VERSION ""

NS_ :

BS_:

BU_: GW BCM ACM BSD
VAL_TABLE_ Rolling_Counter_0x85 15 "Invalid" ;
VAL_TABLE_ ACM_Crash_Sts 3 "Invalid Value" 2 "Invalid Value" 1 "Crash_Detected" 0 "No_Event" ;
VAL_TABLE_ ACM_Airbag_Deployment_Status 3 "Invalid Value" 2 "Invalid Value" 1 "Airbag_Deployment" 0 "No_Airbag_Deployment" ;
VAL_TABLE_ ACM_Crash_Intensity 7 "Invalid_Value" 6 "Invalid_Value" 5 "Invalid_Value" 4 "Invalid_Value" 3 "Crash_Intensity_3" 2 "Crash_Intensity_2" 1 "Crash_Intensity_1" 0 "No_Crash" ;
VAL_TABLE_ ACM_Front_Crash 3 "Invalid Value" 2 "Invalid Value" 1 "Front_Crash_Detected" 0 "No_Event" ;
VAL_TABLE_ ACM_DriverSide_Crash 3 "Invalid Value" 2 "Invalid Value" 1 "Driverside_Crash_Detected" 0 "No_Event" ;
VAL_TABLE_ ACM_PassSide_Crash 3 "Invalid Value" 2 "Invalid Value" 1 "PassSide_Crash_Detected" 0 "No_Event" ;
VAL_TABLE_ ACM_Rear_Crash 3 "Invalid Value" 2 "Invalid Value" 1 "Rear_Crash_Detected" 0 "No_Event" ;
VAL_TABLE_ ACM_Rollover_Crash 3 "Invalid Value" 2 "Invalid Value" 1 "Rollover_Crash_Detected" 0 "No_Event" ;
VAL_TABLE_ Rolling_Counter_0x381 15 "Invalid" ;
VAL_TABLE_ ACM_Seat_Occupancy_Passenger 3 "Failure" 2 "Not_Available" 1 "Seat Occupied" 0 "Seat_Not_Occupied" ;
VAL_TABLE_ ACM_Seat_Occupancy_2nd_Row_Dri_r 3 "Failure" 2 "Not_Available" 1 "Seat Occupied" 0 "Seat_Not_Occupied" ;
VAL_TABLE_ ACM_Seat_Occupancy_2nd_Row_Pas_r 3 "Failure" 2 "Not_Available" 1 "Seat Occupied" 0 "Seat_Not_Occupied" ;
VAL_TABLE_ ACM_Seat_Occupancy_2nd_Row_Mid_r 3 "Failure" 2 "Not_Available" 1 "Seat Occupied" 0 "Seat_Not_Occupied" ;
VAL_TABLE_ ACM_Seat_Belt_Status_Passenger 3 "Failure" 2 "Not_Available" 1 "Buckled" 0 "Not_buckled" ;
VAL_TABLE_ ACM_Seat_Belt_Status_Driver 3 "Failure" 2 "Not_Available" 1 "Buckled" 0 "Not_buckled" ;
VAL_TABLE_ ACM_Seat_Belt_Status_2nd_Row_Dri 3 "Failure" 2 "Not_Available" 1 "Buckled" 0 "Not_buckled" ;
VAL_TABLE_ ACM_Seat_Belt_Status_2nd_Row_Mid 3 "Failure" 2 "Not_Available" 1 "Buckled" 0 "Not_buckled" ;
VAL_TABLE_ ACM_Seat_Belt_Status_2nd_Row_Pas 3 "Failure" 2 "Not_Available" 1 "Buckled" 0 "Not_buckled" ;
VAL_TABLE_ ACM_Seat_Belt_Status_3rd_Row_Dri 3 "Failure" 2 "Not_Available" 1 "Buckled" 0 "Not_buckled" ;
VAL_TABLE_ ACM_Seat_Belt_Status_3rd_Row_Pas 3 "Failure" 2 "Not_Available" 1 "Buckled" 0 "Not_buckled" ;
VAL_TABLE_ Rolling_Counter_0x488 15 "Invalid" ;
VAL_TABLE_ ACM_Malfunction 0 "ACM_Failure" 1 "ACM_Normal_Operation" ;
VAL_TABLE_ ACM_Pre_Drive_Check 0 "ACM_Pre_Drive_Check" 1 "ACM_Normal_Operation" ;
VAL_TABLE_ ACM_in_Plant_Mode 0 "ACM_in_Plant_Mode" 1 "ACM_in_Normal_Mode" ;
VAL_TABLE_ ACM_PAB_Suppression 0 "Not_Suppressed" 1 "Suppressed" 2 "Function Failure" 3 "Invalid_Value" ;
VAL_TABLE_ ACM_Airbag_Disabled 0 "ACM_AirBag_Disabled" 1 "ACM_Normal_Operation" ;
VAL_TABLE_ ACM_Development_Calibration 0 "ACM_Dev_Calibrated" 1 "ACM_Normal_Operation" ;
VAL_TABLE_ ACM_In_Disposal_Mode 0 "ACM_In_Disposal_Mode" 1 "ACM_Normal_Operation" ;
VAL_TABLE_ ACM_Seatbelt_Reminder_Request 0 "Seatbelt reminder NOT activated" 1 "Seatbelt reminder activated" ;
VAL_TABLE_ ACM_SBR_Chime_Req 0 "No Active Chime" 1 "Active Chime" ;
VAL_TABLE_ ACM_SBR_Blinking_Req 0 "No Blinking" 1 "Blinking 1Hz" ;
VAL_TABLE_ BCM_STAT_RemoteLockFeedback 7 "Signal invalid" 6 "Reserved" 5 "Reserved" 4 "Inactive" 3 "Horn Only" 2 "Lights Only" 1 "Lights and Horn" 0 "OFF" ;
VAL_TABLE_ BCM_STAT_RemoteDoorUnlock_reserv 3 "Signal invalid" 2 "All doors" 1 "Driver door" 0 "Reserved" ;
VAL_TABLE_ BCM_STAT_AutoDoorUnlock 3 "Signal invalid" 2 "Reserved" 1 "ON" 0 "OFF" ;
VAL_TABLE_ BCM_STAT_DoorSpeedLock 7 "Signal invalid" 5 "25KMH" 4 "20KMH" 3 "15KMH" 2 "10KMH" 1 "5KMH" 0 "OFF" ;
VAL_TABLE_ BCM_STAT_DayTimeRunningLight_res 3 "Signal invalid" 2 "Reserved" 1 "ON" 0 "OFF" ;
VAL_TABLE_ BCM_STAT_AntiTheftMode 7 "Signal invalid" 3 "Light and Horn" 2 "Horn Only" 1 "Light Only" 0 "OFF" ;
VAL_TABLE_ BCM_FOBID_userprofile_link 5 "Searching" 4 "No key found" 3 "key illegal" 2 "Fob2" 1 "Fob1" 0 "No trigger from MHU" ;
VAL_TABLE_ BCM_feedback_FollowMeHomeTime 4 "120s" 3 "90s" 2 "60s" 1 "30s" 0 "OFF" ;
VAL_TABLE_ Rolling_Counter_0x12f 15 "Invalid" ;
VAL_TABLE_ ST_KL_KEY_VLD 15 "Signal invalid" 14 "Error" 13 "Reserved" 12 "Reserved" 11 "Reserved" 10 "Reserved" 9 "Reserved" 8 "Reserved" 7 "Reserved" 6 "Reserved" 5 "Key 10sec delay" 4 "Key valid IR" 3 "Key valid AR" 2 "Key search activ" 1 "Key invalid" 0 "Init" ;
VAL_TABLE_ ST_SSP 3 "Signal invalid" 2 "Reserve" 1 "SSB pressed" 0 "SSB not pressed" ;
VAL_TABLE_ BCM_IMMO_Sts 2 "failed " 1 "pass " 0 "init" ;
VAL_TABLE_ REQ_ConsumerControlAudioVolumeCo 7 "signal invalid" 6 "Reserved" 5 "Reserved" 4 "Reserved" 3 "Reserved" 2 "Level 2" 1 "Level 1" 0 "No Reduction" ;
VAL_TABLE_ Rolling_Counter_0x105 15 "Invalid" ;
VAL_TABLE_ BCM_STAT_TrunkAjar 3 "Signal invalid" 2 "Reserved" 1 "Opened" 0 "Closed" ;
VAL_TABLE_ BCM_STAT_DoorAjarDriver 3 "Signal invalid" 2 "Reserved" 1 "Opened" 0 "Closed" ;
VAL_TABLE_ BCM_STAT_DoorAjarPassenger 3 "Signal invalid" 2 "Reserved" 1 "Opened" 0 "Closed" ;
VAL_TABLE_ BCM_STAT_DoorAjarRL 3 "Signal invalid" 2 "Reserved" 1 "Opened" 0 "Closed" ;
VAL_TABLE_ BCM_STAT_DoorAjarRR 3 "Signal invalid" 2 "Reserved" 1 "Opened" 0 "Closed" ;
VAL_TABLE_ BCM_STAT_BonnetAjar 3 "Signal invalid" 2 "Reserved" 1 "Opened" 0 "Closed" ;
VAL_TABLE_ Rolling_Counter_0x106 15 "Invalid" ;
VAL_TABLE_ BCM_HighBeamSts 0 "OFF" 1 "ON" 2 "Fault (Reserved)" 3 "Signal Invalid" ;
VAL_TABLE_ BCM_LowBeamSts 0 "OFF" 1 "ON" 2 "Fault (Reserved)" 3 "Signal Invalid" ;
VAL_TABLE_ BCM_PosLmpSts 0 "OFF" 1 "ON" 2 "Fault (Reserved)" 3 "Signal Invalid" ;
VAL_TABLE_ BCM_TurnIndicatorSts 0 "OFF" 1 "Left On" 2 "Right On" 3 "Left and Right On" ;
VAL_TABLE_ BCM_DayRunningLampSts_reserved 0 "OFF" 1 "ON" 2 "Fault (Reserved)" 3 "Signal Invalid" ;
VAL_TABLE_ BCM_ReverseLightSts 0 "OFF" 1 "ON" 2 "Fault (Reserved)" 3 "Signal Invalid" ;
VAL_TABLE_ BCM_StopLightSts 0 "OFF" 1 "ON" 2 "Fault (Reserved)" 3 "Signal Invalid" ;
VAL_TABLE_ BCM_Fr_Dimming_dome_lampSts 0 "OFF" 1 "ON" 2 "Fault (Reserved)" 3 "Signal Invalid" ;
VAL_TABLE_ BCM_Heated_rearglass 0 "OFF" 1 "ON" 2 "Fault (Reserved)" 3 "Signal Invalid" ;
VAL_TABLE_ BCM_BsdLightSts 0 "OFF" 1 "Left On" 2 "Right On" 3 "Left and Right On" ;
VAL_TABLE_ BCM_STAT_LightActivation 7 "Signal invalid" 6 "Reserved" 5 "Reserved" 4 "Reserved" 3 "AutoLight" 2 "LowBeam" 1 "PositionLight" 0 "OFF" ;
VAL_TABLE_ BCM_STAT_InteriorLight 3 "Signal invalid" 2 "Reserved" 1 "ON" 0 "OFF" ;
VAL_TABLE_ Rolling_Counter_0x107 15 "Invalid" ;
VAL_TABLE_ STAT_ATWS 7 "Signal invalid" 6 "Reserved" 5 "Reserved" 4 "Security Failure" 3 "Partly secured" 2 "Alarm" 1 "Unsecured" 0 "Secured" ;
VAL_TABLE_ STAT_DoorLockDriver 3 "Signal invalid" 2 "Reserved" 1 "Locked" 0 "Unlocked" ;
VAL_TABLE_ Rolling_Counter_0x109 15 "Invalid" ;
VAL_TABLE_ BCM_STAT_HazardWarn 3 "Signal invalid" 2 "Reserved" 1 "Active" 0 "Not active" ;
VAL_TABLE_ BCM_STAT_Horn_Reserved 3 "Signal invalid" 2 "Reserved" 1 "ON" 0 "OFF" ;
VAL_TABLE_ BCM_STAT_WiperStalkSW 7 "Invalid" 6 "Reserved" 5 "Reserved" 4 "High" 3 "Low/Mist" 2 "Auto" 1 "OFF" 0 "Mist (reserved)" ;
VAL_TABLE_ BCM_STAT_WiperStalkSW2 7 "Invalid" 6 "Reserved" 5 "Reserved" 4 "wash(Front wash)" 3 "wiper&wash" 2 "wiper (rear wiper)" 1 "OFF(rear wiper)" 0 "wiper&wash(rear wiper and rear wash)" ;
VAL_TABLE_ BCM_LigntSensor 1 "invalid" 0 "valid" ;
VAL_TABLE_ BCM_STAT_lampStalkSW1 7 "Invalid" 6 "Reserved" 5 "Reserved" 4 "Reserved" 3 "OFF" 2 "positionlight" 1 "Lowbeam" 0 "Auto" ;
VAL_TABLE_ BCM_STAT_lampStalkSW2 3 "Invalid" 2 "neutral status" 1 "HighBeam" 0 "FlashHighBeam" ;
VAL_TABLE_ Rolling_Counter_0x10a 15 "Invalid" ;
VAL_TABLE_ BCM_LVTop_up 1 "start Top up" 0 "stop Top up" ;
VAL_TABLE_ RemoteAccessKey 15 "Invalid" 8 "Panic alarm press" 7 "Panic alarm long press" 6 "Long press unlock" 5 "Long press lock" 4 "Tailgate unlock" 3 "Tailgate unlock long press" 2 "Unlock" 1 "Lock" 0 "No command" ;
VAL_TABLE_ PassiveAccessTrunk 3 "Signal invalid" 2 "Reserved" 1 "Pressed" 0 "Not pressed" ;
VAL_TABLE_ BCM_CurrentValid_FOB 0 "No Valid FOB" 1 "FOB_1" 2 "FOB_2" 3 "FOB_3" 4 "FOB_4" 5 "Reserved" 6 "Reserved" 7 "Reserved" ;
VAL_TABLE_ BCM_ACCRelayOutputSts 0 "Inactive" 1 "Active" 2 "Reserved" 3 "Signal Invalid" ;
VAL_TABLE_ BCM_IGN1RelayOutputSts 0 "Inactive" 1 "Active" 2 "Reserved" 3 "Signal Invalid" ;
VAL_TABLE_ BCM_ACCRelayFalutSts 0 "No Fault" 1 "Fault" 2 "Reserved" 3 "Signal Invalid" ;
VAL_TABLE_ BCM_IGN1RelayFalutSts 0 "No Fault" 1 "Fault" 2 "Reserved" 3 "Signal Invalid" ;
VAL_TABLE_ BCM_KEY_MatchSts 0 "No Match" 1 "Match Success" 2 "Match Failed" 3 "Matching" ;
VAL_TABLE_ Rolling_Counter_0x112 15 "Invalid" ;
VAL_TABLE_ STAT_Terminal 7 "Signal invalid" 6 "Reserved" 5 "Reserved" 4 "SW update OTA (Not used in VFe34)" 3 "Engine start (eMotor running)" 2 "ON (Driver Present)" 1 "ACC (Park)" 0 "OFF(Comfort Enable)" ;
VAL_TABLE_ STAT_CL30s_L_Reserved 3 "Signal invalid" 2 "Failure" 1 "ON" 0 "OFF" ;
VAL_TABLE_ PEPS_Lock_IGNNotOff_Alert 1 "Active" 0 "Inactive" ;
VAL_TABLE_ PEPS_CID_NotInside_Alert 1 "Active" 0 "Inactive" ;
VAL_TABLE_ PEPS_CID_Left_Alert 1 "Active" 0 "Inactive" ;
VAL_TABLE_ PEPS_RMKey_BatteryLow_Alert 1 "Active" 0 "Inactive" ;
VAL_TABLE_ PEPS_PressBrakePedal_Alert 1 "Active" 0 "Inactive" ;
VAL_TABLE_ PEPS_Shift_Position_Alert 1 "Active" 0 "Inactive" ;
VAL_TABLE_ PEPS_Lock_KeyInside_Alert 1 "Active" 0 "Inactive" ;
VAL_TABLE_ PEPS_EmergencyStop_Reserved 3 "Invalid" 2 "Reserved" 1 "EmergencyStopMode" 0 "Normal" ;
VAL_TABLE_ PEPS_CID_NotIndenfied_Alert 1 "Active" 0 "InActive" ;
VAL_TABLE_ BCM_Positionlight_reminder 0 "Inactive" 1 "Active" 2 "Reserved" 3 "Signal Invalid" ;
VAL_TABLE_ Rolling_Counter_0x20D 15 "Invalid" ;
VAL_TABLE_ BCM_ODO 1048575 "Invalid" ;
VAL_TABLE_ Rolling_Counter_0x10C 15 "Invalid" ;
VAL_TABLE_ BCM_TboxAuthStatus 0 "Have not learn. Not allow action" 1 "PASSED" 2 "FALIED: Authentication fail" 3 "Invalid" ;
VAL_TABLE_ Rolling_Counter_0x110 15 "Invalid" ;
VAL_TABLE_ BCM_APM_FLWIN_Postion 7 "Reserved" 6 "closing" 5 "opening" 4 "Open-80%（Bottom to 80%）" 3 "80%-Close(80% to Top) " 2 "Open(Bottom) " 1 "Closed(Top)" 0 "NotActive" ;
VAL_TABLE_ BCM_APM_FRWIN_Postion 7 "Reserved" 6 "closing " 5 "opening" 4 "Open-80%（Bottom to 80%）" 3 "80%-Close(80% to Top) " 2 "Open(Bottom) " 1 "Closed(Top)" 0 "NotActive" ;
VAL_TABLE_ BCM_APM_RLWIN_Postion 7 "Reserved" 6 "closing " 5 "opening" 4 "Open-80%（Bottom to 80%）" 3 "80%-Close(80% to Top) " 2 "Open(Bottom) " 1 "Closed(Top)" 0 "NotActive" ;
VAL_TABLE_ BCM_APM_RRWIN_Postion 7 "Reserved" 6 "closing " 5 "opening" 4 "Open-80%（Bottom to 80%）" 3 "80%-Close(80% to Top) " 2 "Open(Bottom) " 1 "Closed(Top)" 0 "NotActive" ;
VAL_TABLE_ APM_Status 1 "Error" 0 "No Error" ;
VAL_TABLE_ ChildProtectionStatus 3 "Invaild" 2 "Reserved" 1 "ON" 0 "OFF" ;
VAL_TABLE_ APM_Window_DriveSW_FL_Status 5 "Reserved" 4 "Auto up" 3 "Manual up " 2 "OFF " 1 "Manual down" 0 "Auto down" ;
VAL_TABLE_ APM_Window_DriveSW_FR_Status 7 "Reserved" 6 "Reserved" 5 "Reserved" 4 "Manual up (Reserved Auto up)" 3 "Manual up " 2 "OFF " 1 "Manual down" 0 "Auto down" ;
VAL_TABLE_ APM_Window_DriveSW_RL_Status 7 "Reserved" 6 "Reserved" 5 "Reserved" 4 "Manual up (Reserved Auto up)" 3 "Manual up " 2 "OFF " 1 "Manual down" 0 "Auto down" ;
VAL_TABLE_ APM_Window_DriveSW_RR_Status 7 "Reserved" 6 "Reserved" 5 "Reserved" 4 "Manual up (Reserved Auto up)" 3 "Manual up " 2 "OFF " 1 "Manual down" 0 "Auto down" ;
VAL_TABLE_ APM_Window_PassengerSW_Status 7 "Reserved" 6 "Reserved" 5 "Reserved" 4 "Manual up (Reserved Auto up)" 3 "Manual up " 2 "OFF " 1 "Manual down" 0 "Auto down" ;
VAL_TABLE_ APM_Window_PassengerSW_RL_Status 7 "Reserved" 6 "Reserved" 5 "Reserved" 4 "Manual up (Reserved Auto up)" 3 "Manual up " 2 "OFF " 1 "Manual down" 0 "Auto down" ;
VAL_TABLE_ APM_Window_PassengerSW_RR_Status 7 "Reserved" 6 "Reserved" 5 "Reserved" 4 "Manual up (Reserved Auto up)" 3 "Manual up " 2 "OFF " 1 "Manual down" 0 "Auto down" ;
VAL_TABLE_ Rolling_Counter_0x128 15 "Invalid" ;
VAL_TABLE_ ADAS_RCTA_IndLeft 0 "Indicator output off" 1 "Indicator On(warning stage - 1)" 2 "Indicator flashing(warning stage - 2)" 3 "Reserved" ;
VAL_TABLE_ ADAS_RCTA_IndRight 0 "Indicator output off" 1 "Indicator On(warning stage - 1)" 2 "Indicator flashing(warning stage - 2)" 3 "Reserved" ;
VAL_TABLE_ ADAS_RCTA_SndWarn 0 "Sound Warning disable" 1 "Left Sound Warning enable" 2 "Right Sound Warning enable" 3 "Left and Right Sound Warning enable" ;
VAL_TABLE_ ADAS_RCTA_check 0 "Available" 1 "Temporarily not available" 2 "Permanently not available" 3 "signal invalid" ;
VAL_TABLE_ ADAS_RCTA_state 0 "OFF State" 1 "Stand by state" 2 "Armed state" 3 "Warning stage" ;
VAL_TABLE_ ADAS_RCTA_sens_Feed_Reserved 0 "Early" 1 "Normal" 2 "Late" 3 "signal invalid" ;
VAL_TABLE_ ADAS_RCTA_Mode_Feed 0 "Off" 1 "On" 2 "Reserved" 3 "signal invalid" ;
VAL_TABLE_ Rolling_Counter_0x133 15 "Invalid" ;
VAL_TABLE_ ADAS_BSD_check 0 "Available" 1 "Temporarily not available" 2 "Permanently not available" 3 "signal invalid" ;
VAL_TABLE_ ADAS_BSD_state 0 "OFF State" 1 "Stand by state" 2 "Armed state" 3 "Warning" ;
VAL_TABLE_ ADAS_BSD_AudChime_Feed 0 "Off" 1 "On" 2 "Reserved" 3 "signal invalid" ;
VAL_TABLE_ ADAS_BSD_IndLeft 0 "Indicator output off" 1 "Indicator On(warning stage - 1)" 2 "Indicator flashing(warning stage - 2)" 3 "Sensor Fault" ;
VAL_TABLE_ ADAS_BSD_IndRight 0 "Indicator output off" 1 "Indicator On(warning stage - 1)" 2 "Indicator flashing(warning stage - 2)" 3 "Sensor Fault" ;
VAL_TABLE_ ADAS_BSD_SndWarn 0 "Sound Warning disable" 1 "Sound Warning enable" ;
VAL_TABLE_ ADAS_BSD_Mode_Feed 0 "Off" 1 "On" 2 "Reserved" 3 "signal invalid" ;
VAL_TABLE_ ADAS_BSD_sens_Feed 0 "Early" 1 "Normal" 2 "Late" 3 "signal invalid" ;
VAL_TABLE_ Rolling_Counter_0x352 15 "Invalid" ;
VAL_TABLE_ ADAS_DOW_Warn 0 "No Info" 1 "Left Warning" 2 "Right Warning" 3 "Left & Right Warning" ;
VAL_TABLE_ ADAS_DOW_SndWarn 0 "Sound Warning disable" 1 "Left Sound Warning enable" 2 "Right Sound Warning enable" 3 "Left and Right Sound Warning enable" ;
VAL_TABLE_ ADAS_DOW_state 0 "OFF State" 1 "Stand by state" 2 "Armed state" 3 "Warning stage" ;
VAL_TABLE_ ADAS_DOW_IndLeft 0 "Indicator output off" 1 "Indicator On(warning stage - 1)" 2 "Indicator flashing(warning stage - 2)" 3 "Sensor Fault" ;
VAL_TABLE_ ADAS_DOW_IndRight 0 "Indicator output off" 1 "Indicator On(warning stage - 1)" 2 "Indicator flashing(warning stage - 2)" 3 "Sensor Fault" ;
VAL_TABLE_ ADAS_DOW_sens_Feed_Reserved 0 "Early" 1 "Normal" 2 "Late" 3 "signal invalid" ;
VAL_TABLE_ ADAS_DOW_Mode_Feed 3 "signal invalid" 2 "Reserved" 1 "ON" 0 "OFF" ;
VAL_TABLE_ ADAS_DOW_AudChime_Feed 0 "Off" 1 "On" 2 "Reserved" 3 "signal invalid" ;
VAL_TABLE_ ADAS_DOW_check 0 "Available" 1 "Temporarily not available" 2 "Permanently not available" 3 "signal invalid" ;
VAL_TABLE_ Rolling_Counter_0x4C0 15 "Invalid" ;
VAL_TABLE_ ADAS_Warning_Flag_1 0 "No Error" 1 "Error" ;
VAL_TABLE_ ADAS_Warning_Flag_2 0 "No Error" 1 "Error" ;
VAL_TABLE_ ADAS_Warning_Flag_3 0 "No Error" 1 "Error" ;
VAL_TABLE_ ADAS_Warning_Flag_4 0 "No Error" 1 "Error" ;
VAL_TABLE_ ADAS_Warning_Flag_5 0 "No Error" 1 "Error" ;
VAL_TABLE_ ADAS_Warning_Flag_6 0 "No Error" 1 "Error" ;
VAL_TABLE_ ADAS_Warning_Flag_7 0 "No Error" 1 "Error" ;
VAL_TABLE_ ADAS_Warning_Flag_8 0 "No Error" 1 "Error" ;
VAL_TABLE_ ADAS_Warning_Flag_9 0 "No Error" 1 "Error" ;
VAL_TABLE_ ADAS_Warning_Flag_10 0 "No Error" 1 "Error" ;
VAL_TABLE_ ADAS_Warning_Flag_11 0 "No Error" 1 "Error" ;
VAL_TABLE_ ADAS_Warning_Flag_12 0 "No Error" 1 "Error" ;
VAL_TABLE_ ADAS_Warning_Flag_13 0 "No Error" 1 "Error" ;
VAL_TABLE_ ADAS_Warning_Flag_14 0 "No Error" 1 "Error" ;
VAL_TABLE_ ADAS_Warning_Flag_15 0 "No Error" 1 "Error" ;
VAL_TABLE_ ADAS_Warning_Flag_16 0 "No Error" 1 "Error" ;
VAL_TABLE_ ADAS_Warning_Flag_17 0 "No Error" 1 "Error" ;
VAL_TABLE_ ADAS_Warning_Flag_18 0 "No Error" 1 "Error" ;
VAL_TABLE_ ADAS_Warning_Flag_19 0 "No Error" 1 "Error" ;
VAL_TABLE_ ADAS_Warning_Flag_20 0 "No Error" 1 "Error" ;
VAL_TABLE_ ADAS_Warning_Flag_21 0 "No Error" 1 "Error" ;
VAL_TABLE_ ADAS_Warning_Flag_22 0 "No Error" 1 "Error" ;
VAL_TABLE_ ADAS_Warning_Flag_23 0 "No Error" 1 "Error" ;
VAL_TABLE_ ADAS_Warning_Flag_24 0 "No Error" 1 "Error" ;
VAL_TABLE_ ADAS_Warning_Flag_25 0 "No Error" 1 "Error" ;
VAL_TABLE_ ADAS_Warning_Flag_26 0 "No Error" 1 "Error" ;
VAL_TABLE_ ADAS_Warning_Flag_27 0 "No Error" 1 "Error" ;
VAL_TABLE_ ADAS_Warning_Flag_28 0 "No Error" 1 "Error" ;
VAL_TABLE_ Rolling_Counter_0x353 15 "Invalid" ;
VAL_TABLE_ ADAS_RadarRight_Cal_Status 0 "No Calib" 1 "Calib OK" ;
VAL_TABLE_ ADAS_RadarLeft_Cal_Status 0 "No Calib" 1 "Calib OK" ;
VAL_TABLE_ ADAS_RadarRight_DynaCal_Status 0 "In Calibrating" 1 "The absolute value of calibration angle is greater than 6 degrees" ;
VAL_TABLE_ ADAS_RadarLeft_DynaCal_Status 0 "In Calibrating" 1 "The absolute value of calibration angle is greater than 6 degrees" ;
VAL_TABLE_ ADAS_MasterSRR_check 0 "Available" 1 "Temporarily not available" 2 "Permanently not available" ;
VAL_TABLE_ ADAS_SlaveSRR_check 0 "Available" 1 "Temporarily not available" 2 "Permanently not available" ;
VAL_TABLE_ ADAS_CalSensorMasterProgress 255 "Invaild" ;
VAL_TABLE_ ADAS_CalSensorSlaverProgress 255 "Invalid" ;
VAL_TABLE_ RollingCounter_0x342 15 "Invalid" ;
VAL_TABLE_ ABS_LRWhlSpdRaw 32767 "Invalid" ;
VAL_TABLE_ ABS_LRWhlSpdRawValid 1 "Valid" 0 "Invalid" ;
VAL_TABLE_ ABS_RRWhlSpdRaw 32767 "Invalid" ;
VAL_TABLE_ ABS_RRWhlSpdRawValid 1 "Valid" 0 "Invalid" ;
VAL_TABLE_ ABS_VehSpd 32767 "Invalid" ;
VAL_TABLE_ ABS_VehSpdValid 1 "Valid" 0 "Invalid" ;
VAL_TABLE_ RollingCounter_0x142 15 "Invalid" ;
VAL_TABLE_ AbsDiagSessionLampReq_Reserved 1 "lamp on" 0 "lamp off" ;
VAL_TABLE_ ABS_AbsCtrlActv 1 "active" 0 "inactive" ;
VAL_TABLE_ ABS_EbdFlgFlt 1 "failure" 0 "no failure" ;
VAL_TABLE_ ABS_AbsFlgFlt 1 "failure" 0 "no failure" ;
VAL_TABLE_ ABS_ESS_Active 1 "active" 0 "inactive" ;
VAL_TABLE_ ABS_LowBrakeFluid 1 "failure" 0 "no failure" ;
VAL_TABLE_ RollingCounter_0x132 15 "Invalid" ;
VAL_TABLE_ ESC_HSA_Control_Status 1 "active" 0 "inactive" ;
VAL_TABLE_ ESC_HSA_Status_Fault 1 " HSA Defective" 0 "HSA Normale" ;
VAL_TABLE_ ESC_TcsDisableSts 3 "signal invalid" 2 "reservred" 1 "disabled" 0 "enabled" ;
VAL_TABLE_ ESC_TcsCtrlActv 1 "active" 0 "inactive" ;
VAL_TABLE_ ESC_TcsFlgFlt 1 "failure" 0 "no failure" ;
VAL_TABLE_ ESC_EscDisableSts 1 "disabled" 0 "enabled" ;
VAL_TABLE_ ESC_EscCtrlActv 1 "active" 0 "inactive" ;
VAL_TABLE_ ESC_EscFlgFlt 1 "failure" 0 "no failure" ;
VAL_TABLE_ ESC_HBAFlgFlt 1 "failure" 0 "no failure" ;
VAL_TABLE_ ESC_HbaCtrlActv 1 "active" 0 "inactive" ;
VAL_TABLE_ ESC_SlopeGradeAngle 255 "Invalid" ;
VAL_TABLE_ ESC_MasterCylinderPressure 4095 "Invalid" ;
VAL_TABLE_ RollingCounter_0x3E2 15 "Invalid" ;
VAL_TABLE_ ESC_LateralACC 255 "Invalid" ;
VAL_TABLE_ ESC_LateralACC_Valid 1 "Valid" 0 "Invalid" ;
VAL_TABLE_ ESC_LongitudeACC 1023 "Invalid" ;
VAL_TABLE_ ESC_LongitudeACC_Valid 1 "Valid" 0 "Invalid" ;
VAL_TABLE_ ESC_VehDynYawRate 16383 "Invalid" ;
VAL_TABLE_ ESC_VehDynYawRate_Valid 1 "Valid" 0 "Invalid" ;
VAL_TABLE_ Rolling_counter_0x37E 15 "Invalid" ;
VAL_TABLE_ EPS_SteeringTorque 4095 "Invalid" ;
VAL_TABLE_ EPS_TorqSensorStatus 1 "Invalid" 0 "Valid" ;
VAL_TABLE_ EPS_EpsFailed 1 "failed" 0 "not failed" ;
VAL_TABLE_ EPS_Mode 3 " Invalid" 1 "low assist" 0 "full assist" ;
VAL_TABLE_ Rolling_counter_0x17E 15 "Invalid" ;
VAL_TABLE_ SAS_SteerWheelAngle 65535 "Invalid" ;
VAL_TABLE_ SAS_SteeringAngleValid 1 "Valid" 0 "Invalid" ;
VAL_TABLE_ SAS_SASStsSnsr 1 "sensor value valid" 0 "sensor value Invalid" ;
VAL_TABLE_ SAS_SteerWhlRotSpd 16383 "Invalid" ;
VAL_TABLE_ SAS_SteerWhlRotSpdStatus 1 "Valid" 0 "Invalid" ;
VAL_TABLE_ SAS_Calibrated 1 "Calibrated" 0 "Not Calibrated" ;
VAL_TABLE_ SAS_SASFailure 1 "No Failure" 0 "Failure" ;
VAL_TABLE_ RollingCounter_0x269 15 "Invalid" ;
VAL_TABLE_ VCU_VehicleHVStatus 3 "Reserved" 2 "ReadyToDrive" 1 "HV On" 0 "Not ready" ;
VAL_TABLE_ VCU_ActualGear 7 "Fault" 6 "Reserved" 5 "Reserved" 4 "Reserved" 3 "D" 2 "N" 1 "R" 0 "P reserved" ;
VAL_TABLE_ VCU_ActualGearValid 1 "nvalid" 0 "Valid" ;
VAL_TABLE_ VCU_AccPedalPosition 255 "Invalid" ;
VAL_TABLE_ VCU_AccPedalPositionValid 1 "Invalid" 0 "Valid" ;
VAL_TABLE_ VCU_TqReductionRqstResponse_Rese 1 "active" 0 "inactive" ;
VAL_TABLE_ VCU_BrakePedalSts 3 "Invalid" 2 "Reserved" 1 "pressed" 0 "Not pressed" ;
VAL_TABLE_ CCU_ExternalTemperature 255 "Invaild" ;
VAL_TABLE_ CCU_ExternalTemperatureFailSts 1 "invalid" 0 "valid" ;
VAL_TABLE_ IPC_Sec 63 "Invalid" ;
VAL_TABLE_ IPC_Min 63 "Invalid" ;
VAL_TABLE_ IPC_Hour 31 "Invalid" ;
VAL_TABLE_ IPC_Day 31 "Invalid" ;
VAL_TABLE_ IPC_Month 15 "Invalid" ;
VAL_TABLE_ IPC_Year 255 "Invalid" ;
VAL_TABLE_ IPC_SelfCheckStatus 1 "self-check finish" 0 "self-checking" ;
VAL_TABLE_ Rolling_Counter_0x20C 15 "Invalid" ;
VAL_TABLE_ IPC_ODO 1048575 "Invalid" ;
VAL_TABLE_ IPC_TripA 65535 "Invalid" ;
VAL_TABLE_ IPC_AverageSpeedTripA 4095 "Invalid" ;
VAL_TABLE_ IPC_AverageConsumptionTripA 1023 "Invalid" ;
VAL_TABLE_ IPC_ParkBrakeSts 3 "Invalid" 2 "Reserved" 1 "Applied" 0 "Released" ;
VAL_TABLE_ IPC_VehSpd 32767 "Invalid" ;
VAL_TABLE_ MHU_SET_DoorSpeedLock 15 "Invalid" 14 "Reserved" 13 "Reserved" 12 "Reserved" 11 "Reserved" 10 "Reserved" 9 "Reserved" 8 "Reserved" 7 "Reserved" 6 "Inactive" 5 "25KMH" 4 "20KMH" 3 "15KMH" 2 "10KMH" 1 "5KMH" 0 "OFF" ;
VAL_TABLE_ MHU_SET_RemoteDoorUnlock_reserve 3 "Signal invalid" 2 "Reserved" 1 "All doors" 0 "Driver door" ;
VAL_TABLE_ MHU_SET_RemoteLockFeedback 7 "Signal Invalid" 6 "Reserved" 5 "Reserved" 4 "inactive" 3 "Horn" 2 "Light" 1 "Light/Horn" 0 "OFF" ;
VAL_TABLE_ MHU_SET_AutoUnlockDoor 7 "Invalid" 6 "Reserved" 5 "Reserved" 4 "Reserved" 3 "Reserved" 2 "Inactive" 1 "ON" 0 "OFF" ;
VAL_TABLE_ MHU_SET_MirrorAuto_reserved 3 "Signal invalid" 2 "Reserved" 1 "ON" 0 "OFF" ;
VAL_TABLE_ MHU_Anti_theftAlarmSet 7 "Invalid" 6 "Reserved" 5 "Reserved" 4 "inactive" 3 "Light/Horn" 2 "Horn" 1 "Light" 0 "OFF" ;
VAL_TABLE_ MHU_TriggerReadKey 3 "Signal Invalid" 2 "Reserved" 1 "Request" 0 "No Request" ;
VAL_TABLE_ MHU_Heatrearglass_Set 0 "OFF" 1 "ON" 2 "No action" 3 "Invalid" ;
VAL_TABLE_ MHU_SET_DayTimeRunningLight_rese 3 "Signal invalid" 2 "Reserved" 1 "ON" 0 "OFF" ;
VAL_TABLE_ MHU_SET_FollowMeHomeTime 7 "Invalid" 6 "Inactive" 5 "Reserved" 4 "120s" 3 "90s" 2 "60s" 1 "30s" 0 "OFF" ;
VAL_TABLE_ MHU_St_DimmingIPC 15 "Invalid" 14 "Level 15" 13 "Level 14" 12 "Level 13" 11 "Level 12" 10 "Level 11" 9 "Level 10" 8 "Level 9" 7 "Level 8" 6 "Level 7" 5 "Level 6" 4 "Level 5" 3 "Level 4" 2 "Level 3" 1 "Level 2" 0 "Level 1" ;
VAL_TABLE_ Rolling_Counter_0x432 15 "Invalid" ;
VAL_TABLE_ MHU_FOTA_State 0 "INIT" 1 "NORMAL" 2 "FOTA FLASHING" 3 "FOTA-SUSPENDED" 4 "FAIL-SAFE-ERROR" 5 "SHUTDOWN" 6 "REMOTE DIAGNOSTICS" 7 "Invalid" ;
VAL_TABLE_ TBOX_STAT_TerminalReq 7 "Signal invalid" 6 "No action" 5 "Reserved" 4 "SW Update OTA" 3 "Engine start (eMotor running)" 2 "ON (Driver Present)" 1 "ACC (Park)" 0 "OFF(Comfort Enable)" ;
VAL_TABLE_ MHU_BCM_reqTrunk 3 "Signal invalid" 2 "No action" 1 "Open" 0 "Close reserved" ;
VAL_TABLE_ MHU_BCM_RemoteDoorCtrl 3 "Signal invalid" 2 "Reserved" 1 "Unlock" 0 "Lock" ;
VAL_TABLE_ MHU_APM_ReqWindow 2 "Open(Bottom) " 1 "Closed(Top)" 0 "No action" ;
VAL_TABLE_ MHU_SetHighBeam 1 "Request flashing" 2 "No request" 3 "Invalid" ;
VAL_TABLE_ MHU_SetHornOnOff 0 "OFF" 1 "ON" 2 "No action" 3 "Invalid" ;
VAL_TABLE_ MHU_SetLowBeam 0 "OFF" 1 "ON" 2 "No action" 3 "Invalid" ;
VAL_TABLE_ MHU_BSD_On 3 "Signal invalid" 2 "inactive" 1 "ON" 0 "OFF" ;
VAL_TABLE_ MHU_BSD_sens_Reserved 7 "invalid" 6 "Reserved" 5 "Reserved" 4 "Reserved" 3 "Inactive" 2 "Late" 1 "Normal" 0 "Early" ;
VAL_TABLE_ MHU_BSD_AudWarning 3 "Signal invalid" 2 "inactive" 1 "ON" 0 "OFF" ;
VAL_TABLE_ MHU_RCTA_On 3 "Signal invalid" 2 "inactive" 1 "ON" 0 "OFF" ;
VAL_TABLE_ MHU_RCTA_sens_Reserved 7 "invalid" 6 "Reserved" 5 "Reserved" 4 "Reserved" 3 "Inactive" 2 "Late" 1 "Normal" 0 "Early" ;
VAL_TABLE_ MHU_PA_On 3 "Signal invalid" 2 "inactive" 1 "ON" 0 "OFF" ;
VAL_TABLE_ MHU_DOW_Mode 3 "Signal invalid" 2 "inactive" 1 "ON" 0 "OFF" ;
VAL_TABLE_ MHU_DOW_sens_Reserved 7 "invalid" 6 "Reserved" 5 "Reserved" 4 "Reserved" 3 "Inactive" 2 "Late" 1 "Normal" 0 "Early" ;
VAL_TABLE_ MHU_DOW_AudWarning 3 "Signal invalid" 2 "inactive" 1 "ON" 0 "OFF" ;
VAL_TABLE_ VCU_RegenLevel_Feed 3 "invalid" 2 "High" 1 "Low" 0 "none" ;
VAL_TABLE_ VCU_RBCSts 1 "active" 0 "incative" ;
VAL_TABLE_ VCU_RDCSts 1 "active" 0 "incative" ;
VAL_TABLE_ VCU_Veh_ERR 1 "Error" 0 "Normal" ;
VAL_TABLE_ VCU_DrvSys_ERR 1 "Error" 0 "Normal" ;
VAL_TABLE_ VCU_PackSys_ERR 1 "Error" 0 "Normal" ;
VAL_TABLE_ VCU_TBOX_Veh_STS_Reserved 3 "Other" 2 "Off" 1 "Start" 0 "Invalid" ;
VAL_TABLE_ VCU_VehChg_STS 3 "Charge fault" 2 "Charging complete" 1 "Charging in progress" 0 "Charging not in progress" ;
VAL_TABLE_ VCU_BatterVoltage_Reserved 255 "Invalid" ;
VAL_TABLE_ VCU_BatteryVoltErr_Reserved 1 "warning" 0 "no warning" ;
VAL_TABLE_ VCU_MotorCoolingCircuitErr_Reser 1 "Error" 0 "Normal" ;
VAL_TABLE_ VCU_PackCoolingCircuitErr_Reserv 1 "Error" 0 "Normal" ;
VAL_TABLE_ VCU_VehicleHVStatus 3 "Reserved" 2 "ReadyToDrive" 1 "HV On" 0 "Not ready" ;
VAL_TABLE_ VCU_InstantPowerConsump 1023 "Invalid" ;
VAL_TABLE_ VCU_AveragePowerConsump 1023 "Invalid" ;
VAL_TABLE_ VCU_BrakePedalSts 3 "Invalid" 2 "Reserved" 1 "pressed" 0 "Not pressed" ;
VAL_TABLE_ VCU_DCDC_Output_REQ 1 "enable" 0 "disable" ;
VAL_TABLE_ VCU_DCDC_OutVoltage_REQ 511 "Invalid" ;
VAL_TABLE_ VCU_DCDCAllowedPower 511 "Invalid" ;
VAL_TABLE_ VCU_FanControl_Sts 2 "FAN High " 1 "FAN Low " 0 " off" ;
VAL_TABLE_ VCU_IMMO_Sts 2 "failed " 1 "pass " 0 "init" ;
VAL_TABLE_ VCU_VacuumSts_reserved 3 "Invalid" 2 "quick leak " 1 "slow leak " 0 "Normal" ;
VAL_TABLE_ VCU_VacuumPresWrn 3 "Invalid" 2 "Serious Insufficient " 1 "Slight Insufficient " 0 "Normal" ;
VAL_TABLE_ Rolling_Counter_0x1F8 15 "Invalid" ;
VAL_TABLE_ EDS_output_trq_FR 65535 "Invalid" ;
VAL_TABLE_ EDS_output_trqValid_FR 1 "valid" 0 "invalid" ;
VAL_TABLE_ EDS_Spd_FR 65535 "Invalid" ;
VAL_TABLE_ EDS_SpdValid_FR 1 "valid" 0 "invalid" ;
VAL_TABLE_ EDS_MotorDriveSts_FR 3 "Invaild" 2 "regen control" 1 "Drive control" 0 "Zero control" ;
VAL_TABLE_ EDS_Work_STS_FR 15 "invaild" 14 "power off" 13 "Failure" 12 "after run" 11 "shut down" 5 "HVReady" 4 "normal" 3 "precharge" 2 "standby" 1 "init" 0 "default" ;
VAL_TABLE_ EDS_powoff_req_FR 1 "(Request high voltage power down)" 0 "(No request)" ;
VAL_TABLE_ Rolling_Counter_0x215 15 "Invalid" ;
VAL_TABLE_ BMS_SOE 255 "Invalid" ;
VAL_TABLE_ BMS_HWCrash_Sts 1 "Crash " 0 "No Crash" ;
VAL_TABLE_ BMS_HVIL_STS 2 "short to ground" 1 "Open & short to battery" 0 "Closed" ;
VAL_TABLE_ BMS_IGN_Sts 1 "ON " 0 "OFF" ;
VAL_TABLE_ BMS_Sys_STS 8 "Invalid" 7 "Failure, unable to operate" 6 "BCU Sleep mode" 5 "Successful Power Down" 4 "Power Down process" 3 "Successful Power Down of HV" 2 "Successful High Voltage Power Up" 1 "Self-check passes, can be high-voltage" 0 "Initialization of power on, self-checking" ;
VAL_TABLE_ BMS_HVOnOff_STS 3 "Fail to HV on " 2 "HV On " 1 "Precharge " 0 "HV Off" ;
VAL_TABLE_ BMS_Balance_STS 1 "active " 0 "Inactive" ;
VAL_TABLE_ BMS_SocActual_EST 1023 "Invalid" ;
VAL_TABLE_ BMS_BatBalance_ERR 1 "normal " 0 "Error" ;
VAL_TABLE_ BMS_ISU_Status 3 "Level3(<100 Ohms/V)" 2 "Level2(<200 Ohms/V)" 1 "Level1 <500 Ohms/V ~ >200 Ohms/V" 0 "Normal (> 500 Ohms/V)" ;
VAL_TABLE_ BMS_ERR_LEV 7 "Battery locked -Reserved" 6 "Fault, needs Shutdown and Wakeup" 5 "Emergency off condition" 4 "Delayed power down with FTTI" 3 "Power down without FTTI" 2 "Limp Home" 1 " Warning (any warning in system)" 0 "No error" ;
VAL_TABLE_ BMS_SOH 255 "Invalid" ;
VAL_TABLE_ BMS_HV_Sts 4 "AC Charge" 3 "Super Fast Charge" 2 "HV ON" 1 "Precharge" 0 "HV Off" ;

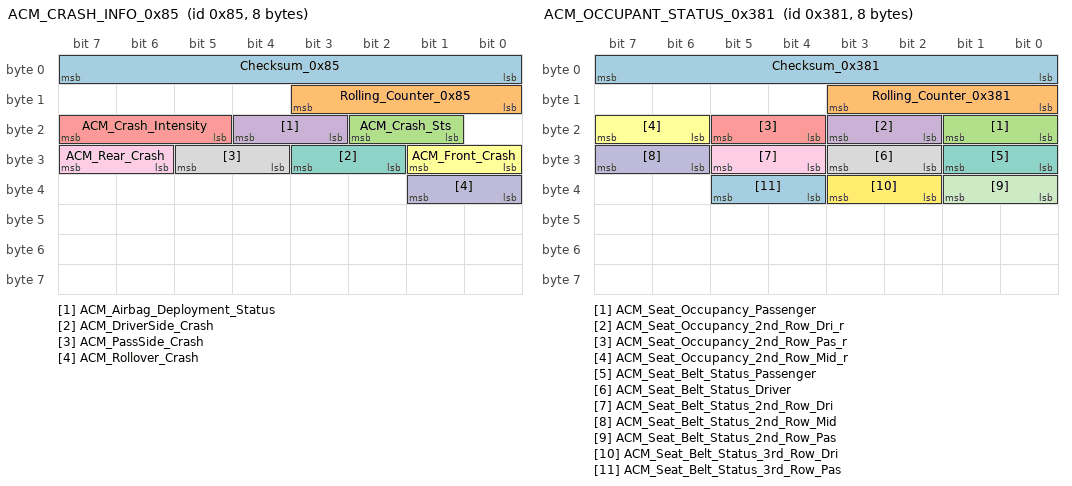
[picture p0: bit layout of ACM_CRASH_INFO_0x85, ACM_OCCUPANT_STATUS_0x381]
BO_ 133 ACM_CRASH_INFO_0x85: 8 ACM
 SG_ Checksum_0x85 : 7|8@0+ (1,0) [0|255] ""  GW,BCM
 SG_ Rolling_Counter_0x85 : 11|4@0+ (1,0) [0|15] ""  GW,BCM
 SG_ ACM_Crash_Sts : 18|2@0+ (1,0) [0|3] ""  GW,BCM
 SG_ ACM_Airbag_Deployment_Status : 20|2@0+ (1,0) [0|3] ""  GW
 SG_ ACM_Crash_Intensity : 23|3@0+ (1,0) [0|7] ""  GW
 SG_ ACM_Front_Crash : 25|2@0+ (1,0) [0|3] ""  GW
 SG_ ACM_DriverSide_Crash : 27|2@0+ (1,0) [0|3] ""  GW
 SG_ ACM_PassSide_Crash : 29|2@0+ (1,0) [0|3] ""  GW
 SG_ ACM_Rear_Crash : 31|2@0+ (1,0) [0|3] ""  GW
 SG_ ACM_Rollover_Crash : 33|2@0+ (1,0) [0|3] ""  GW

BO_ 897 ACM_OCCUPANT_STATUS_0x381: 8 ACM
 SG_ Checksum_0x381 : 7|8@0+ (1,0) [0|255] ""  GW
 SG_ Rolling_Counter_0x381 : 11|4@0+ (1,0) [0|15] ""  GW
 SG_ ACM_Seat_Occupancy_Passenger : 17|2@0+ (1,0) [0|3] ""  GW
 SG_ ACM_Seat_Occupancy_2nd_Row_Dri_r : 19|2@0+ (1,0) [0|3] ""  GW
 SG_ ACM_Seat_Occupancy_2nd_Row_Pas_r : 21|2@0+ (1,0) [0|3] ""  GW
 SG_ ACM_Seat_Occupancy_2nd_Row_Mid_r : 23|2@0+ (1,0) [0|3] ""  GW
 SG_ ACM_Seat_Belt_Status_Passenger : 25|2@0+ (1,0) [0|3] ""  GW
 SG_ ACM_Seat_Belt_Status_Driver : 27|2@0+ (1,0) [0|3] ""  GW
 SG_ ACM_Seat_Belt_Status_2nd_Row_Dri : 29|2@0+ (1,0) [0|3] ""  GW
 SG_ ACM_Seat_Belt_Status_2nd_Row_Mid : 31|2@0+ (1,0) [0|3] ""  GW
 SG_ ACM_Seat_Belt_Status_2nd_Row_Pas : 33|2@0+ (1,0) [0|3] ""  GW
 SG_ ACM_Seat_Belt_Status_3rd_Row_Dri : 35|2@0+ (1,0) [0|3] ""  GW
 SG_ ACM_Seat_Belt_Status_3rd_Row_Pas : 37|2@0+ (1,0) [0|3] ""  GW

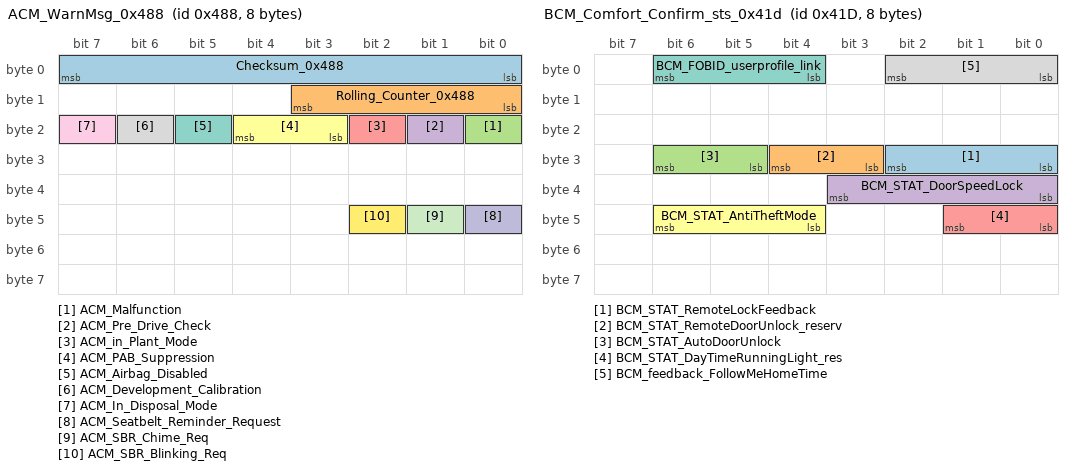
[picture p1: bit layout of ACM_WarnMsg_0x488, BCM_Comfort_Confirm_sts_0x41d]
BO_ 1160 ACM_WarnMsg_0x488: 8 ACM
 SG_ Checksum_0x488 : 7|8@0+ (1,0) [0|255] ""  GW
 SG_ Rolling_Counter_0x488 : 11|4@0+ (1,0) [0|15] ""  GW
 SG_ ACM_Malfunction : 16|1@0+ (1,0) [0|1] ""  GW
 SG_ ACM_Pre_Drive_Check : 17|1@0+ (1,0) [0|1] "Bit"  GW
 SG_ ACM_in_Plant_Mode : 18|1@0+ (1,0) [0|1] "Bit"  GW
 SG_ ACM_PAB_Suppression : 20|2@0+ (1,0) [0|3] "Bit"  GW
 SG_ ACM_Airbag_Disabled : 21|1@0+ (1,0) [0|1] ""  GW
 SG_ ACM_Development_Calibration : 22|1@0+ (1,0) [0|1] ""  GW
 SG_ ACM_In_Disposal_Mode : 23|1@0+ (1,0) [0|1] ""  GW
 SG_ ACM_Seatbelt_Reminder_Request : 40|1@0+ (1,0) [0|1] ""  GW
 SG_ ACM_SBR_Chime_Req : 41|1@0+ (1,0) [0|1] ""  GW
 SG_ ACM_SBR_Blinking_Req : 42|1@0+ (1,0) [0|1] ""  GW

BO_ 1053 BCM_Comfort_Confirm_sts_0x41d: 8 BCM
 SG_ BCM_STAT_RemoteLockFeedback : 26|3@0+ (1,0) [0|7] ""  GW,BSD
 SG_ BCM_STAT_RemoteDoorUnlock_reserv : 28|2@0+ (1,0) [0|3] ""  GW,BSD
 SG_ BCM_STAT_AutoDoorUnlock : 30|2@0+ (1,0) [0|3] ""  GW,BSD
 SG_ BCM_STAT_DoorSpeedLock : 35|4@0+ (1,0) [0|7] ""  GW
 SG_ BCM_STAT_DayTimeRunningLight_res : 41|2@0+ (1,0) [0|3] ""  GW
 SG_ BCM_STAT_AntiTheftMode : 46|3@0+ (1,0) [0|7] ""  GW
 SG_ BCM_FOBID_userprofile_link : 6|3@0+ (1,0) [0|7] ""  GW
 SG_ BCM_feedback_FollowMeHomeTime : 2|3@0+ (1,0) [0|7] ""  GW

BO_ 303 BCM_TERMINAL_0x12f: 8 BCM
 SG_ Checksum_0x12f : 7|8@0+ (1,0) [0|255] ""  GW
 SG_ Rolling_Counter_0x12f : 11|4@0+ (1,0) [0|15] ""  GW
 SG_ ST_KL_KEY_VLD : 19|4@0+ (1,0) [0|15] ""  GW
 SG_ ST_SSP : 25|2@0+ (1,0) [0|3] ""  GW
 SG_ BCM_IMMO_Sts : 29|2@0+ (1,0) [0|2] ""  GW

BO_ 259 BCM_ENERGY_MANAGEMENT_0x103: 8 BCM
 SG_ Q_Discharge : 47|16@0+ (0.125,0) [0|8191.75] "Ah"  GW
 SG_ Q_Charge : 31|16@0+ (0.125,0) [0|8191.75] "Ah"  GW
 SG_ RQ_DCDC_U : 15|8@0+ (0.1,0) [0|25.2] "Vol"  GW
 SG_ REQ_ConsumerControlAudioVolumeCo : 18|3@0+ (1,0) [0|7] ""  GW
 SG_ REQ_CCU_PTC_Limitation : 63|8@0+ (1,0) [0|100] "percent"  GW

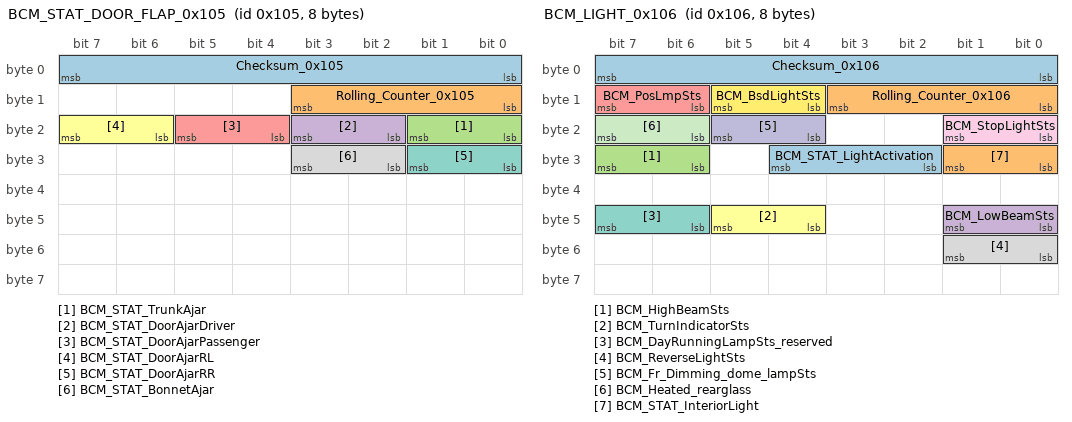
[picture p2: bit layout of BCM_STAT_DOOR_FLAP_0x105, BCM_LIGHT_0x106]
BO_ 261 BCM_STAT_DOOR_FLAP_0x105: 8 BCM
 SG_ Checksum_0x105 : 7|8@0+ (1,0) [0|255] ""  GW,BSD
 SG_ Rolling_Counter_0x105 : 11|4@0+ (1,0) [0|15] ""  GW,BSD
 SG_ BCM_STAT_TrunkAjar : 17|2@0+ (1,0) [0|3] "Bit"  GW,BSD
 SG_ BCM_STAT_DoorAjarDriver : 19|2@0+ (1,0) [0|3] "Bit"  GW,BSD
 SG_ BCM_STAT_DoorAjarPassenger : 21|2@0+ (1,0) [0|3] "Bit"  GW,BSD
 SG_ BCM_STAT_DoorAjarRL : 23|2@0+ (1,0) [0|3] "Bit"  GW,BSD
 SG_ BCM_STAT_DoorAjarRR : 25|2@0+ (1,0) [0|3] "Bit"  GW,BSD
 SG_ BCM_STAT_BonnetAjar : 27|2@0+ (1,0) [0|3] "Bit"  GW,BSD

BO_ 262 BCM_LIGHT_0x106: 8 BCM
 SG_ Checksum_0x106 : 7|8@0+ (1,0) [0|255] ""  GW,ACM,BSD
 SG_ Rolling_Counter_0x106 : 11|4@0+ (1,0) [0|15] ""  GW,ACM,BSD
 SG_ BCM_HighBeamSts : 31|2@0+ (1,0) [0|3] ""  GW
 SG_ BCM_LowBeamSts : 41|2@0+ (1,0) [0|3] ""  GW
 SG_ BCM_PosLmpSts : 15|2@0+ (1,0) [0|3] ""  GW
 SG_ BCM_TurnIndicatorSts : 45|2@0+ (1,0) [0|3] ""  GW,ACM,BSD
 SG_ BCM_DayRunningLampSts_reserved : 47|2@0+ (1,0) [0|3] ""  GW
 SG_ BCM_ReverseLightSts : 49|2@0+ (1,0) [0|3] ""  GW
 SG_ BCM_StopLightSts : 17|2@0+ (1,0) [0|3] ""  GW
 SG_ BCM_Fr_Dimming_dome_lampSts : 21|2@0+ (1,0) [0|3] ""  GW
 SG_ BCM_Heated_rearglass : 23|2@0+ (1,0) [0|3] ""  GW
 SG_ BCM_BsdLightSts : 13|2@0+ (1,0) [0|3] ""  GW
 SG_ BCM_STAT_LightActivation : 28|3@0+ (1,0) [0|7] ""  GW
 SG_ BCM_STAT_InteriorLight : 25|2@0+ (1,0) [0|3] "Bit"  GW

BO_ 263 BCM_STAT_CENTRAL_LOCK_0x107: 8 BCM
 SG_ Checksum_0x107 : 7|8@0+ (1,0) [0|255] ""  GW,BSD
 SG_ Rolling_Counter_0x107 : 11|4@0+ (1,0) [0|15] ""  GW,BSD
 SG_ STAT_ATWS : 20|3@0+ (1,0) [0|7] "Bit"  GW
 SG_ STAT_DoorLockDriver : 23|2@0+ (1,0) [0|3] "Bit"  GW,BSD

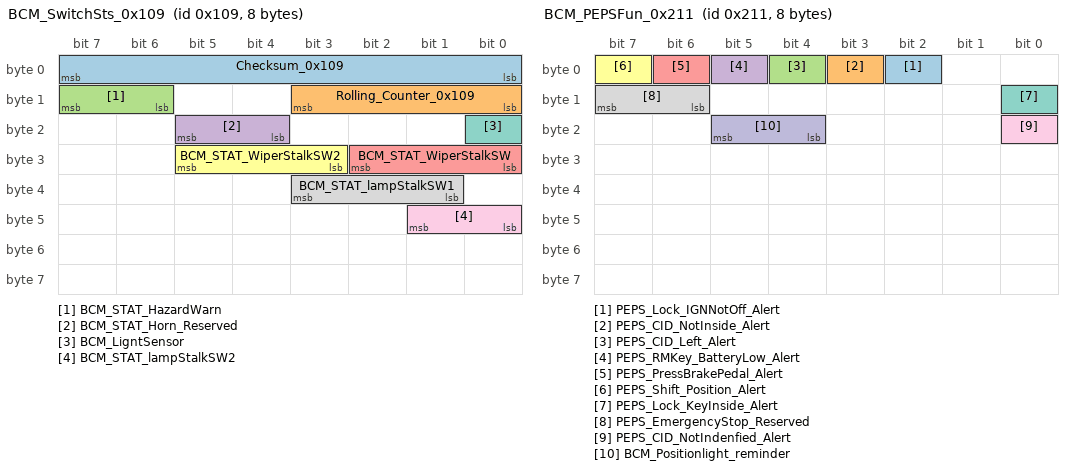
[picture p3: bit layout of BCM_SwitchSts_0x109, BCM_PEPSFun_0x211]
BO_ 265 BCM_SwitchSts_0x109: 8 BCM
 SG_ Checksum_0x109 : 7|8@0+ (1,0) [0|255] ""  ACM,BSD
 SG_ Rolling_Counter_0x109 : 11|4@0+ (1,0) [0|15] ""  ACM,BSD
 SG_ BCM_STAT_HazardWarn : 15|2@0+ (1,0) [0|3] ""  ACM,BSD
 SG_ BCM_STAT_Horn_Reserved : 21|2@0+ (1,0) [0|3] "" Vector__XXX
 SG_ BCM_STAT_WiperStalkSW : 26|3@0+ (1,0) [0|7] ""  BSD
 SG_ BCM_STAT_WiperStalkSW2 : 29|3@0+ (1,0) [0|7] ""  BSD
 SG_ BCM_LigntSensor : 16|1@0+ (1,0) [0|1] "" Vector__XXX
 SG_ BCM_STAT_lampStalkSW1 : 35|3@0+ (1,0) [0|7] ""  BSD
 SG_ BCM_STAT_lampStalkSW2 : 41|2@0+ (1,0) [0|3] ""  BSD

BO_ 266 BCM_VOLTAGE_0x10a: 8 BCM
 SG_ Checksum_0x10a : 7|8@0+ (1,0) [0|255] ""  GW,ACM,BSD
 SG_ Rolling_Counter_0x10a : 11|4@0+ (1,0) [0|15] ""  GW,ACM,BSD
 SG_ BCM_LVTop_up : 24|1@0+ (1,0) [0|1] ""  GW,ACM,BSD
 SG_ Ubatt_Reserved : 23|14@0+ (0.001,3) [3|18] "V"  GW,ACM,BSD

BO_ 270 BCM_ENTRY_CONTROL_0x10e: 8 BCM
 SG_ RemoteAccessKey : 7|4@0+ (1,0) [0|7] ""  GW
 SG_ PassiveAccessTrunk : 9|2@0+ (1,0) [0|3] ""  GW
 SG_ BCM_CurrentValid_FOB : 18|3@0+ (1,0) [0|4] ""  GW

BO_ 283 BCM_Power_0x11b: 8 BCM
 SG_ BCM_ACCRelayOutputSts : 3|2@0+ (1,0) [0|3] ""  GW
 SG_ BCM_IGN1RelayOutputSts : 5|2@0+ (1,0) [0|3] ""  GW
 SG_ BCM_ACCRelayFalutSts : 9|2@0+ (1,0) [0|3] ""  GW
 SG_ BCM_IGN1RelayFalutSts : 11|2@0+ (1,0) [0|3] ""  GW
 SG_ BCM_KEY_MatchSts : 15|2@0+ (1,0) [0|3] ""  GW

BO_ 274 BCM_CLAMP_STAT_0x112: 8 BCM
 SG_ Checksum_0x112 : 7|8@0+ (1,0) [0|255] ""  GW,ACM,BSD
 SG_ Rolling_Counter_0x112 : 11|4@0+ (1,0) [0|15] ""  GW,ACM,BSD
 SG_ STAT_Terminal : 34|3@0+ (1,0) [0|7] "Bit"  GW,ACM,BSD
 SG_ STAT_CL30s_L_Reserved : 41|2@0+ (1,0) [0|3] "Bit"  GW

BO_ 529 BCM_PEPSFun_0x211: 8 BCM
 SG_ PEPS_Lock_IGNNotOff_Alert : 2|1@0+ (1,0) [0|1] ""  GW
 SG_ PEPS_CID_NotInside_Alert : 3|1@0+ (1,0) [0|1] ""  GW
 SG_ PEPS_CID_Left_Alert : 4|1@0+ (1,0) [0|1] ""  GW
 SG_ PEPS_RMKey_BatteryLow_Alert : 5|1@0+ (1,0) [0|1] ""  GW
 SG_ PEPS_PressBrakePedal_Alert : 6|1@0+ (1,0) [0|1] ""  GW
 SG_ PEPS_Shift_Position_Alert : 7|1@0+ (1,0) [0|1] ""  GW
 SG_ PEPS_Lock_KeyInside_Alert : 8|1@0+ (1,0) [0|1] ""  GW
 SG_ PEPS_EmergencyStop_Reserved : 15|2@0+ (1,0) [0|3] ""  GW
 SG_ PEPS_CID_NotIndenfied_Alert : 16|1@0+ (1,0) [0|1] ""  GW
 SG_ BCM_Positionlight_reminder : 21|2@0+ (1,0) [0|3] ""  GW

BO_ 525 BCM_ODO_0x20D: 8 BCM
 SG_ Checksum_0x20D : 7|8@0+ (1,0) [0|255] ""  GW
 SG_ Rolling_Counter_0x20D : 11|4@0+ (1,0) [0|15] ""  GW
 SG_ BCM_ODO : 31|20@0+ (1,0) [0|999999] "km"  GW

BO_ 268 BCM_RemoteCtrlSts_0x10C: 8 BCM
 SG_ Checksum_0x10C : 7|8@0+ (1,0) [0|255] ""  GW
 SG_ Rolling_Counter_0x10C : 11|4@0+ (1,0) [0|15] ""  GW
 SG_ BCM_TboxAuthStatus : 13|2@0+ (1,0) [0|2] ""  GW
 SG_ BCM_RandomNum32bit : 39|32@0+ (1,0) [0|4294967295] ""  GW

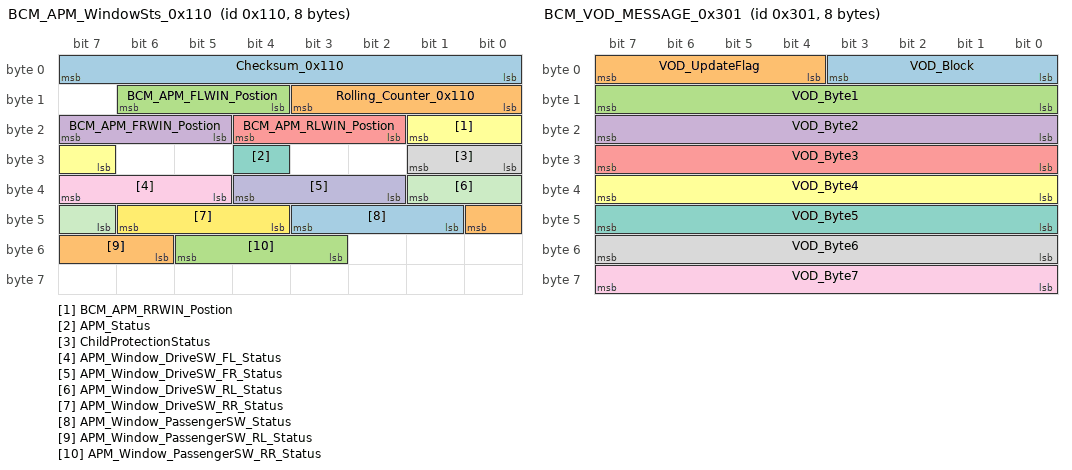
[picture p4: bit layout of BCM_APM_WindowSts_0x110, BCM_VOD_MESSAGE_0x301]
BO_ 272 BCM_APM_WindowSts_0x110: 8 BCM
 SG_ Checksum_0x110 : 7|8@0+ (1,0) [0|255] ""  GW
 SG_ Rolling_Counter_0x110 : 11|4@0+ (1,0) [0|14] ""  GW
 SG_ BCM_APM_FLWIN_Postion : 14|3@0+ (1,0) [0|6] ""  GW
 SG_ BCM_APM_FRWIN_Postion : 23|3@0+ (1,0) [0|6] ""  GW
 SG_ BCM_APM_RLWIN_Postion : 20|3@0+ (1,0) [0|6] ""  GW
 SG_ BCM_APM_RRWIN_Postion : 17|3@0+ (1,0) [0|6] ""  GW
 SG_ APM_Status : 28|1@0+ (1,0) [0|1] ""  GW
 SG_ ChildProtectionStatus : 25|2@0+ (1,0) [0|3] ""  GW
 SG_ APM_Window_DriveSW_FL_Status : 39|3@0+ (1,0) [0|6] ""  GW
 SG_ APM_Window_DriveSW_FR_Status : 36|3@0+ (1,0) [0|6] ""  GW
 SG_ APM_Window_DriveSW_RL_Status : 33|3@0+ (1,0) [0|6] ""  GW
 SG_ APM_Window_DriveSW_RR_Status : 46|3@0+ (1,0) [0|6] ""  GW
 SG_ APM_Window_PassengerSW_Status : 43|3@0+ (1,0) [0|6] ""  GW
 SG_ APM_Window_PassengerSW_RL_Status : 40|3@0+ (1,0) [0|6] ""  GW
 SG_ APM_Window_PassengerSW_RR_Status : 53|3@0+ (1,0) [0|6] ""  GW

BO_ 769 BCM_VOD_MESSAGE_0x301: 8 BCM
 SG_ VOD_Block : 3|4@0+ (1,0) [0|7] ""  GW
 SG_ VOD_UpdateFlag : 7|4@0+ (1,0) [0|7] ""  GW
 SG_ VOD_Byte1 : 15|8@0+ (1,0) [0|255] ""  GW
 SG_ VOD_Byte2 : 23|8@0+ (1,0) [0|255] ""  GW
 SG_ VOD_Byte3 : 31|8@0+ (1,0) [0|255] ""  GW
 SG_ VOD_Byte4 : 39|8@0+ (1,0) [0|255] ""  GW
 SG_ VOD_Byte5 : 47|8@0+ (1,0) [0|255] ""  GW
 SG_ VOD_Byte6 : 55|8@0+ (1,0) [0|255] ""  GW
 SG_ VOD_Byte7 : 63|8@0+ (1,0) [0|255] ""  GW

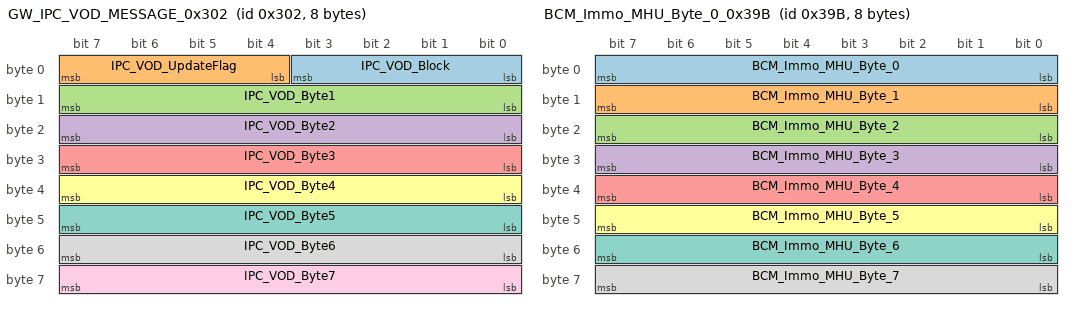
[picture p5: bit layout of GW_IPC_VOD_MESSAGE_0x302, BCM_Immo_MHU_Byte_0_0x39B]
BO_ 770 GW_IPC_VOD_MESSAGE_0x302: 8 GW
 SG_ IPC_VOD_Block : 3|4@0+ (1,0) [0|7] ""  BCM
 SG_ IPC_VOD_UpdateFlag : 7|4@0+ (1,0) [0|7] ""  BCM
 SG_ IPC_VOD_Byte1 : 15|8@0+ (1,0) [0|255] ""  BCM
 SG_ IPC_VOD_Byte2 : 23|8@0+ (1,0) [0|255] ""  BCM
 SG_ IPC_VOD_Byte3 : 31|8@0+ (1,0) [0|255] ""  BCM
 SG_ IPC_VOD_Byte4 : 39|8@0+ (1,0) [0|255] ""  BCM
 SG_ IPC_VOD_Byte5 : 47|8@0+ (1,0) [0|255] ""  BCM
 SG_ IPC_VOD_Byte6 : 55|8@0+ (1,0) [0|255] ""  BCM
 SG_ IPC_VOD_Byte7 : 63|8@0+ (1,0) [0|255] ""  BCM

BO_ 923 BCM_Immo_MHU_Byte_0_0x39B: 8 BCM
 SG_ BCM_Immo_MHU_Byte_0 : 7|8@0+ (1,0) [0|255] ""  GW
 SG_ BCM_Immo_MHU_Byte_1 : 15|8@0+ (1,0) [0|255] ""  GW
 SG_ BCM_Immo_MHU_Byte_2 : 23|8@0+ (1,0) [0|255] ""  GW
 SG_ BCM_Immo_MHU_Byte_3 : 31|8@0+ (1,0) [0|255] ""  GW
 SG_ BCM_Immo_MHU_Byte_4 : 39|8@0+ (1,0) [0|255] ""  GW
 SG_ BCM_Immo_MHU_Byte_5 : 47|8@0+ (1,0) [0|255] ""  GW
 SG_ BCM_Immo_MHU_Byte_6 : 55|8@0+ (1,0) [0|255] ""  GW
 SG_ BCM_Immo_MHU_Byte_7 : 63|8@0+ (1,0) [0|255] ""  GW

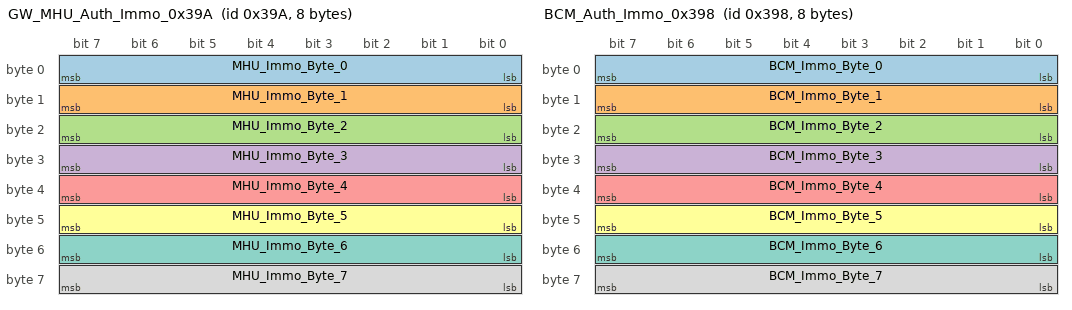
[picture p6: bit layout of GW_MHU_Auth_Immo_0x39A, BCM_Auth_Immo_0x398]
BO_ 922 GW_MHU_Auth_Immo_0x39A: 8 GW
 SG_ MHU_Immo_Byte_0 : 7|8@0+ (1,0) [0|255] ""  BCM
 SG_ MHU_Immo_Byte_1 : 15|8@0+ (1,0) [0|255] ""  BCM
 SG_ MHU_Immo_Byte_2 : 23|8@0+ (1,0) [0|255] ""  BCM
 SG_ MHU_Immo_Byte_3 : 31|8@0+ (1,0) [0|255] ""  BCM
 SG_ MHU_Immo_Byte_4 : 39|8@0+ (1,0) [0|255] ""  BCM
 SG_ MHU_Immo_Byte_5 : 47|8@0+ (1,0) [0|255] ""  BCM
 SG_ MHU_Immo_Byte_6 : 55|8@0+ (1,0) [0|255] ""  BCM
 SG_ MHU_Immo_Byte_7 : 63|8@0+ (1,0) [0|255] ""  BCM

BO_ 920 BCM_Auth_Immo_0x398: 8 BCM
 SG_ BCM_Immo_Byte_0 : 7|8@0+ (1,0) [0|255] ""  GW
 SG_ BCM_Immo_Byte_1 : 15|8@0+ (1,0) [0|255] ""  GW
 SG_ BCM_Immo_Byte_2 : 23|8@0+ (1,0) [0|255] ""  GW
 SG_ BCM_Immo_Byte_3 : 31|8@0+ (1,0) [0|255] ""  GW
 SG_ BCM_Immo_Byte_4 : 39|8@0+ (1,0) [0|255] ""  GW
 SG_ BCM_Immo_Byte_5 : 47|8@0+ (1,0) [0|255] ""  GW
 SG_ BCM_Immo_Byte_6 : 55|8@0+ (1,0) [0|255] ""  GW
 SG_ BCM_Immo_Byte_7 : 63|8@0+ (1,0) [0|255] ""  GW

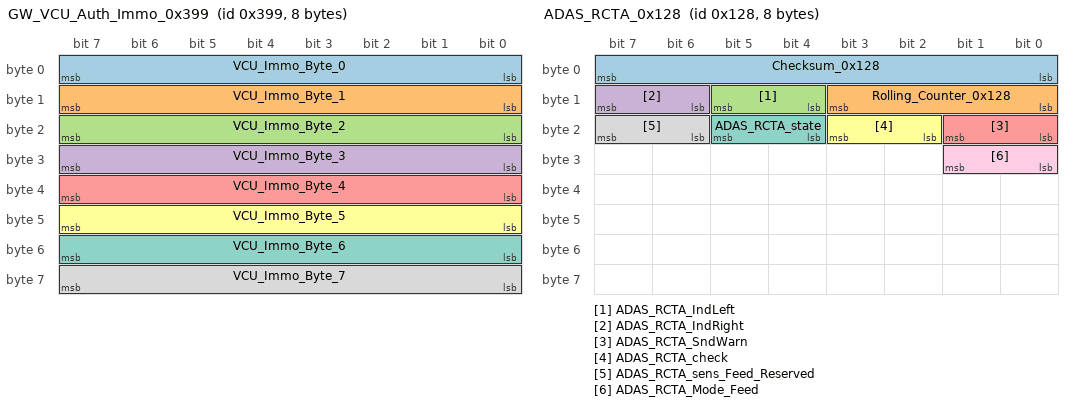
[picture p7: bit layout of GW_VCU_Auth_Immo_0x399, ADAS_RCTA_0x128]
BO_ 921 GW_VCU_Auth_Immo_0x399: 8 GW
 SG_ VCU_Immo_Byte_0 : 7|8@0+ (1,0) [0|255] ""  BCM
 SG_ VCU_Immo_Byte_1 : 15|8@0+ (1,0) [0|255] ""  BCM
 SG_ VCU_Immo_Byte_2 : 23|8@0+ (1,0) [0|255] ""  BCM
 SG_ VCU_Immo_Byte_3 : 31|8@0+ (1,0) [0|255] ""  BCM
 SG_ VCU_Immo_Byte_4 : 39|8@0+ (1,0) [0|255] ""  BCM
 SG_ VCU_Immo_Byte_5 : 47|8@0+ (1,0) [0|255] ""  BCM
 SG_ VCU_Immo_Byte_6 : 55|8@0+ (1,0) [0|255] ""  BCM
 SG_ VCU_Immo_Byte_7 : 63|8@0+ (1,0) [0|255] ""  BCM

BO_ 296 ADAS_RCTA_0x128: 8 BSD
 SG_ Checksum_0x128 : 7|8@0+ (1,0) [0|255] ""  GW,BCM
 SG_ Rolling_Counter_0x128 : 11|4@0+ (1,0) [0|15] ""  GW,BCM
 SG_ ADAS_RCTA_IndLeft : 13|2@0+ (1,0) [0|3] ""  GW,BCM
 SG_ ADAS_RCTA_IndRight : 15|2@0+ (1,0) [0|3] ""  GW,BCM
 SG_ ADAS_RCTA_SndWarn : 17|2@0+ (1,0) [0|3] ""  GW,BCM
 SG_ ADAS_RCTA_check : 19|2@0+ (1,0) [0|3] ""  GW,BCM
 SG_ ADAS_RCTA_state : 21|2@0+ (1,0) [0|3] ""  GW,BCM
 SG_ ADAS_RCTA_sens_Feed_Reserved : 23|2@0+ (1,0) [0|3] ""  GW,BCM
 SG_ ADAS_RCTA_Mode_Feed : 25|2@0+ (1,0) [0|3] ""  GW,BCM

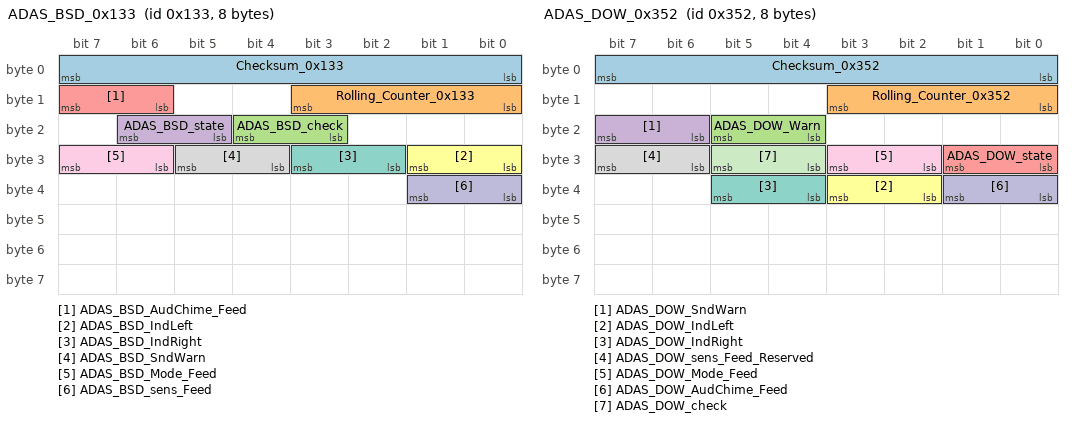
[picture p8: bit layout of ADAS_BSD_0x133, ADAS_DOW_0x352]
BO_ 307 ADAS_BSD_0x133: 8 BSD
 SG_ Checksum_0x133 : 7|8@0+ (1,0) [0|255] ""  GW,BCM
 SG_ Rolling_Counter_0x133 : 11|4@0+ (1,0) [0|15] ""  GW,BCM
 SG_ ADAS_BSD_check : 20|2@0+ (1,0) [0|3] ""  GW,BCM
 SG_ ADAS_BSD_state : 22|2@0+ (1,0) [0|3] ""  GW,BCM
 SG_ ADAS_BSD_AudChime_Feed : 15|2@0+ (1,0) [0|3] ""  GW,BCM
 SG_ ADAS_BSD_IndLeft : 25|2@0+ (1,0) [0|3] ""  GW,BCM
 SG_ ADAS_BSD_IndRight : 27|2@0+ (1,0) [0|3] ""  GW,BCM
 SG_ ADAS_BSD_SndWarn : 29|2@0+ (1,0) [0|3] ""  GW,BCM
 SG_ ADAS_BSD_Mode_Feed : 31|2@0+ (1,0) [0|3] ""  GW,BCM
 SG_ ADAS_BSD_sens_Feed : 33|2@0+ (1,0) [0|3] ""  GW,BCM

BO_ 850 ADAS_DOW_0x352: 8 BSD
 SG_ Checksum_0x352 : 7|8@0+ (1,0) [0|255] ""  GW,BCM
 SG_ Rolling_Counter_0x352 : 11|4@0+ (1,0) [0|15] ""  GW,BCM
 SG_ ADAS_DOW_Warn : 21|2@0+ (1,0) [0|3] ""  GW,BCM
 SG_ ADAS_DOW_SndWarn : 23|2@0+ (1,0) [0|3] ""  GW,BCM
 SG_ ADAS_DOW_state : 25|2@0+ (1,0) [0|3] ""  GW,BCM
 SG_ ADAS_DOW_IndLeft : 35|2@0+ (1,0) [0|3] ""  GW,BCM
 SG_ ADAS_DOW_IndRight : 37|2@0+ (1,0) [0|3] ""  GW,BCM
 SG_ ADAS_DOW_sens_Feed_Reserved : 31|2@0+ (1,0) [0|3] ""  GW,BCM
 SG_ ADAS_DOW_Mode_Feed : 27|2@0+ (1,0) [0|3] ""  GW,BCM
 SG_ ADAS_DOW_AudChime_Feed : 33|2@0+ (1,0) [0|3] ""  GW,BCM
 SG_ ADAS_DOW_check : 29|2@0+ (1,0) [0|3] ""  GW,BCM

BO_ 1216 ADAS_WarnMsg_0x4C0: 8 BSD
 SG_ Checksum_0x4C0 : 7|8@0+ (1,0) [0|255] ""  GW
 SG_ Rolling_Counter_0x4C0 : 11|4@0+ (1,0) [0|15] ""  GW
 SG_ ADAS_Warning_Flag_1 : 12|1@0+ (1,0) [0|1] ""  GW
 SG_ ADAS_Warning_Flag_2 : 13|1@0+ (1,0) [0|1] ""  GW
 SG_ ADAS_Warning_Flag_3 : 14|1@0+ (1,0) [0|1] ""  GW
 SG_ ADAS_Warning_Flag_4 : 15|1@0+ (1,0) [0|1] ""  GW
 SG_ ADAS_Warning_Flag_5 : 16|1@0+ (1,0) [0|1] ""  GW
 SG_ ADAS_Warning_Flag_6 : 17|1@0+ (1,0) [0|1] ""  GW
 SG_ ADAS_Warning_Flag_7 : 18|1@0+ (1,0) [0|1] ""  GW
 SG_ ADAS_Warning_Flag_8 : 19|1@0+ (1,0) [0|1] ""  GW
 SG_ ADAS_Warning_Flag_9 : 20|1@0+ (1,0) [0|1] ""  GW
 SG_ ADAS_Warning_Flag_10 : 21|1@0+ (1,0) [0|1] ""  GW
 SG_ ADAS_Warning_Flag_11 : 22|1@0+ (1,0) [0|1] ""  GW
 SG_ ADAS_Warning_Flag_12 : 23|1@0+ (1,0) [0|1] ""  GW
 SG_ ADAS_Warning_Flag_13 : 24|1@0+ (1,0) [0|1] ""  GW
 SG_ ADAS_Warning_Flag_14 : 25|1@0+ (1,0) [0|1] ""  GW
 SG_ ADAS_Warning_Flag_15 : 26|1@0+ (1,0) [0|1] ""  GW
 SG_ ADAS_Warning_Flag_16 : 27|1@0+ (1,0) [0|1] ""  GW
 SG_ ADAS_Warning_Flag_17 : 28|1@0+ (1,0) [0|1] ""  GW
 SG_ ADAS_Warning_Flag_18 : 29|1@0+ (1,0) [0|1] ""  GW
 SG_ ADAS_Warning_Flag_19 : 30|1@0+ (1,0) [0|1] ""  GW
 SG_ ADAS_Warning_Flag_20 : 31|1@0+ (1,0) [0|1] ""  GW
 SG_ ADAS_Warning_Flag_21 : 32|1@0+ (1,0) [0|1] ""  GW
 SG_ ADAS_Warning_Flag_22 : 33|1@0+ (1,0) [0|1] ""  GW
 SG_ ADAS_Warning_Flag_23 : 34|1@0+ (1,0) [0|1] ""  GW
 SG_ ADAS_Warning_Flag_24 : 35|1@0+ (1,0) [0|1] ""  GW
 SG_ ADAS_Warning_Flag_25 : 36|1@0+ (1,0) [0|1] ""  GW
 SG_ ADAS_Warning_Flag_26 : 37|1@0+ (1,0) [0|1] ""  GW
 SG_ ADAS_Warning_Flag_27 : 38|1@0+ (1,0) [0|1] ""  GW
 SG_ ADAS_Warning_Flag_28 : 39|1@0+ (1,0) [0|1] ""  GW
 SG_ ADAS_Reserved_signal3 : 47|8@0+ (1,0) [0|255] ""  GW
 SG_ ADAS_Reserved_signal4 : 55|8@0+ (1,0) [0|255] ""  GW
 SG_ ADAS_Reserved_signal5 : 63|8@0+ (1,0) [0|255] ""  GW

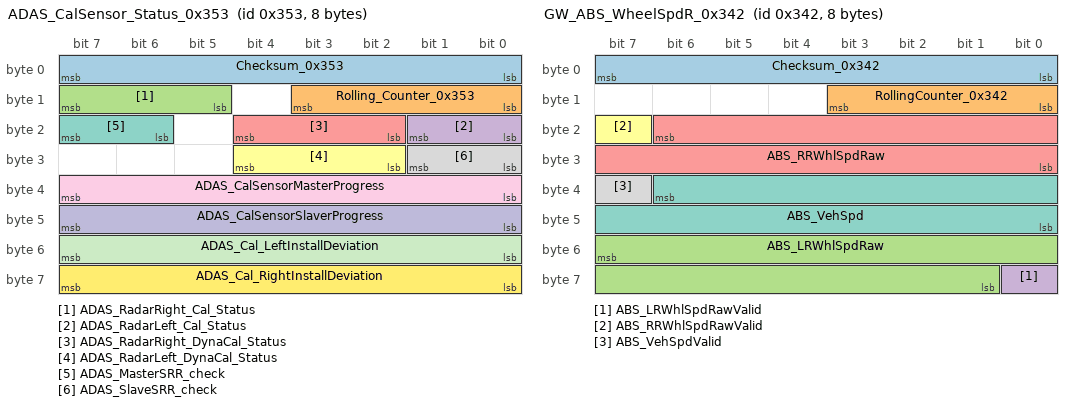
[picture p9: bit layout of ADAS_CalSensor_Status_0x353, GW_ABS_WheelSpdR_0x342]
BO_ 851 ADAS_CalSensor_Status_0x353: 8 BSD
 SG_ Checksum_0x353 : 7|8@0+ (1,0) [0|255] ""  GW
 SG_ Rolling_Counter_0x353 : 11|4@0+ (1,0) [0|15] ""  GW
 SG_ ADAS_RadarRight_Cal_Status : 15|3@0+ (1,0) [0|7] ""  GW
 SG_ ADAS_RadarLeft_Cal_Status : 17|2@0+ (1,0) [0|3] ""  GW
 SG_ ADAS_RadarRight_DynaCal_Status : 20|3@0+ (1,0) [0|7] ""  GW
 SG_ ADAS_RadarLeft_DynaCal_Status : 28|3@0+ (1,0) [0|7] ""  GW
 SG_ ADAS_MasterSRR_check : 23|2@0+ (1,0) [0|3] ""  GW
 SG_ ADAS_SlaveSRR_check : 25|2@0+ (1,0) [0|3] ""  GW
 SG_ ADAS_CalSensorMasterProgress : 39|8@0+ (0.4,0) [0|100] "%"  GW
 SG_ ADAS_CalSensorSlaverProgress : 47|8@0+ (0.4,0) [0|100] "%"  GW
 SG_ ADAS_Cal_LeftInstallDeviation : 55|8@0- (0.1,0) [-12.8|12.7] "deg"  GW
 SG_ ADAS_Cal_RightInstallDeviation : 63|8@0- (0.1,0) [-12.8|12.7] "deg"  GW

BO_ 834 GW_ABS_WheelSpdR_0x342: 8 GW
 SG_ Checksum_0x342 : 7|8@0+ (1,0) [0|255] ""  BCM,ACM,BSD
 SG_ RollingCounter_0x342 : 11|4@0+ (1,0) [0|15] ""  BCM,ACM,BSD
 SG_ ABS_LRWhlSpdRaw : 55|15@0+ (0.01,0) [0|327.66] "kph" Vector__XXX
 SG_ ABS_LRWhlSpdRawValid : 56|1@0+ (1,0) [0|1] "" Vector__XXX
 SG_ ABS_RRWhlSpdRaw : 22|15@0+ (0.01,0) [0|327.66] "kph" Vector__XXX
 SG_ ABS_RRWhlSpdRawValid : 23|1@0+ (1,0) [0|1] "" Vector__XXX
 SG_ ABS_VehSpd : 38|15@0+ (0.01,0) [0|327.66] "kph"  BCM,ACM,BSD
 SG_ ABS_VehSpdValid : 39|1@0+ (1,0) [0|1] ""  BCM,ACM,BSD

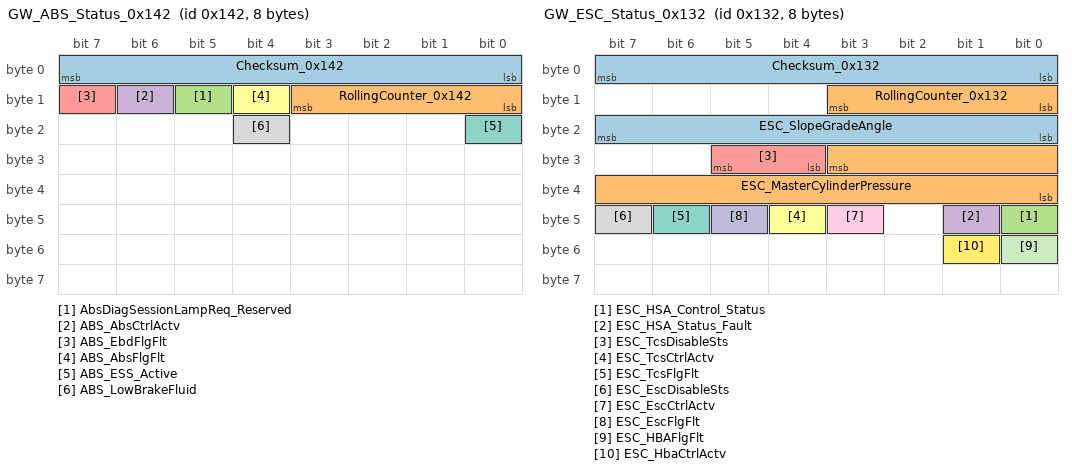
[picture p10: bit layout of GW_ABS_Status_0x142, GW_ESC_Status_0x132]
BO_ 322 GW_ABS_Status_0x142: 8 GW
 SG_ Checksum_0x142 : 7|8@0+ (1,0) [0|255] ""  BCM,ACM
 SG_ RollingCounter_0x142 : 11|4@0+ (1,0) [0|15] ""  BCM,ACM
 SG_ AbsDiagSessionLampReq_Reserved : 13|1@0+ (1,0) [0|1] "" Vector__XXX
 SG_ ABS_AbsCtrlActv : 14|1@0+ (1,0) [0|1] ""  ACM
 SG_ ABS_EbdFlgFlt : 15|1@0+ (1,0) [0|1] "" Vector__XXX
 SG_ ABS_AbsFlgFlt : 12|1@0+ (1,0) [0|1] ""  ACM
 SG_ ABS_ESS_Active : 16|1@0+ (1,0) [0|1] ""  BCM
 SG_ ABS_LowBrakeFluid : 20|1@0+ (1,0) [0|1] "" Vector__XXX

BO_ 306 GW_ESC_Status_0x132: 8 GW
 SG_ Checksum_0x132 : 7|8@0+ (1,0) [0|255] ""  ACM,BSD
 SG_ RollingCounter_0x132 : 11|4@0+ (1,0) [0|15] ""  ACM,BSD
 SG_ ESC_HSA_Control_Status : 40|1@0+ (1,0) [0|1] ""  BSD
 SG_ ESC_HSA_Status_Fault : 41|1@0+ (1,0) [0|1] ""  BSD
 SG_ ESC_TcsDisableSts : 29|2@0+ (1,0) [0|3] ""  BSD
 SG_ ESC_TcsCtrlActv : 44|1@0+ (1,0) [0|1] ""  BSD
 SG_ ESC_TcsFlgFlt : 46|1@0+ (1,0) [0|1] ""  BSD
 SG_ ESC_EscDisableSts : 47|1@0+ (1,0) [0|1] ""  BSD
 SG_ ESC_EscCtrlActv : 43|1@0+ (1,0) [0|1] ""  ACM,BSD
 SG_ ESC_EscFlgFlt : 45|1@0+ (1,0) [0|1] ""  ACM,BSD
 SG_ ESC_HBAFlgFlt : 48|1@0+ (1,0) [0|1] ""  BSD
 SG_ ESC_HbaCtrlActv : 49|1@0+ (1,0) [0|1] ""  BSD
 SG_ ESC_SlopeGradeAngle : 23|8@0+ (0.35433,-45) [-45|45] "deg"  BSD
 SG_ ESC_MasterCylinderPressure : 27|12@0+ (0.1,-100) [-100|309.4] "bar"  BSD

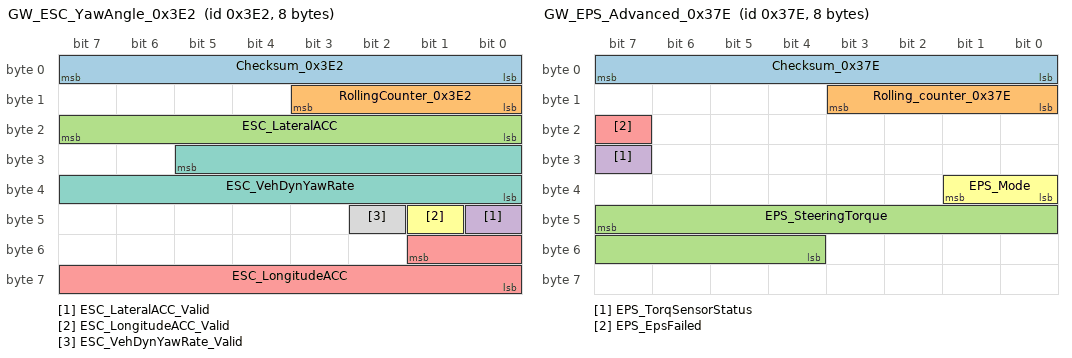
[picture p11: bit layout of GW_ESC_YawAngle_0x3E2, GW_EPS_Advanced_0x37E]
BO_ 994 GW_ESC_YawAngle_0x3E2: 8 GW
 SG_ Checksum_0x3E2 : 7|8@0+ (1,0) [0|255] ""  ACM,BSD
 SG_ RollingCounter_0x3E2 : 11|4@0+ (1,0) [0|15] ""  ACM,BSD
 SG_ ESC_LateralACC : 23|8@0+ (0.01587,-2.0193) [-2.0193|2.0193] "g"  BSD
 SG_ ESC_LateralACC_Valid : 40|1@0+ (1,0) [0|1] ""  BSD
 SG_ ESC_LongitudeACC : 49|10@0+ (0.00392,-1.9929) [-1.9929|1.9929] "g"  BCM,BSD
 SG_ ESC_LongitudeACC_Valid : 41|1@0+ (1,0) [0|1] ""  BCM,BSD
 SG_ ESC_VehDynYawRate : 29|14@0+ (0.03125,-256) [-256|255.96875] "deg/s"  ACM,BSD
 SG_ ESC_VehDynYawRate_Valid : 42|1@0+ (1,0) [0|1] ""  ACM,BSD

BO_ 894 GW_EPS_Advanced_0x37E: 8 GW
 SG_ Checksum_0x37E : 7|8@0+ (1,0) [0|255] ""  BSD
 SG_ Rolling_counter_0x37E : 11|4@0+ (1,0) [0|15] ""  BSD
 SG_ EPS_SteeringTorque : 47|12@0+ (0.01,-20.47) [-20.47|20.47] "Nm"  BSD
 SG_ EPS_TorqSensorStatus : 31|1@0+ (1,0) [0|1] ""  BSD
 SG_ EPS_EpsFailed : 23|1@0+ (1,0) [0|1] ""  BSD
 SG_ EPS_Mode : 33|2@0+ (1,0) [0|3] "" Vector__XXX

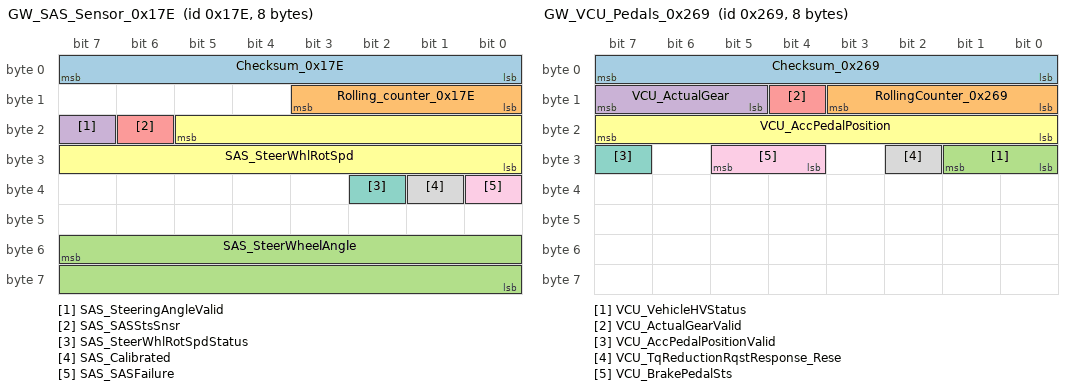
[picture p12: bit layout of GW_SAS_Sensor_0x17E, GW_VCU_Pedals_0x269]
BO_ 382 GW_SAS_Sensor_0x17E: 8 GW
 SG_ Checksum_0x17E : 7|8@0+ (1,0) [0|255] ""  ACM,BSD
 SG_ Rolling_counter_0x17E : 11|4@0+ (1,0) [0|15] ""  ACM,BSD
 SG_ SAS_SteerWheelAngle : 55|16@0+ (0.0238,-780) [-780|779.7] "deg"  ACM,BSD
 SG_ SAS_SteeringAngleValid : 23|1@0+ (1,0) [0|1] ""  ACM,BSD
 SG_ SAS_SASStsSnsr : 22|1@0+ (1,0) [0|1] ""  BSD
 SG_ SAS_SteerWhlRotSpd : 21|14@0+ (0.125,-1024) [-1024|1023.75] "degs"  BSD
 SG_ SAS_SteerWhlRotSpdStatus : 34|1@0+ (1,0) [0|1] ""  BSD
 SG_ SAS_Calibrated : 33|1@0+ (1,0) [0|1] ""  BSD
 SG_ SAS_SASFailure : 32|1@0+ (1,0) [0|1] ""  BSD

BO_ 617 GW_VCU_Pedals_0x269: 8 GW
 SG_ Checksum_0x269 : 7|8@0+ (1,0) [0|255] ""  BCM,ACM,BSD
 SG_ RollingCounter_0x269 : 11|4@0+ (1,0) [0|15] ""  BCM,ACM,BSD
 SG_ VCU_VehicleHVStatus : 25|2@0+ (1,0) [0|3] ""  BCM,ACM
 SG_ VCU_ActualGear : 15|3@0+ (1,0) [0|7] ""  BCM,BSD
 SG_ VCU_ActualGearValid : 12|1@0+ (1,0) [0|1] ""  BCM,BSD
 SG_ VCU_AccPedalPosition : 23|8@0+ (0.4,0) [0|100] "%"  ACM,BSD
 SG_ VCU_AccPedalPositionValid : 31|1@0+ (1,0) [0|1] ""  ACM,BSD
 SG_ VCU_TqReductionRqstResponse_Rese : 26|1@0+ (1,0) [0|1] "" Vector__XXX
 SG_ VCU_BrakePedalSts : 29|2@0+ (1,0) [0|3] ""  BCM,ACM,BSD

BO_ 814 GW_CCU_Info_0x32E: 8 GW
 SG_ CCU_ExternalTemperature : 7|8@0+ (0.5,-40) [-40|87] "°C"  BCM,ACM,BSD
 SG_ CCU_ExternalTemperatureFailSts : 8|1@0+ (1,0) [0|1] ""  BCM,ACM,BSD

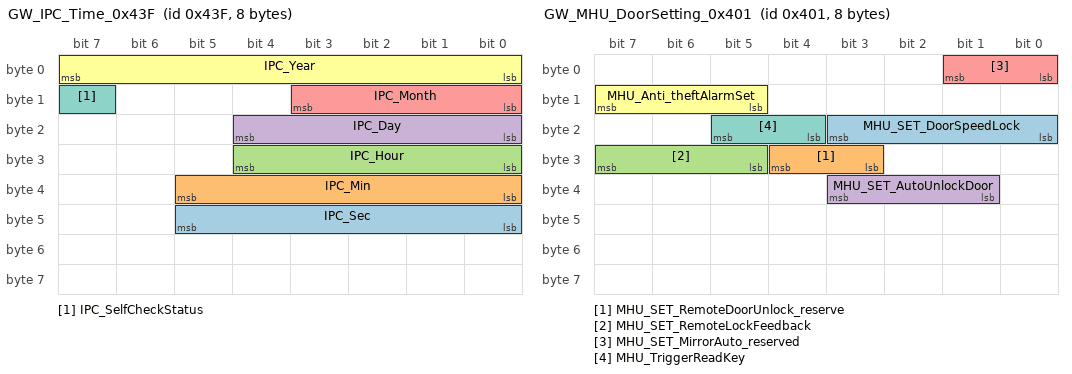
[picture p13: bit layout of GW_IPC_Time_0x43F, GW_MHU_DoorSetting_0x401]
BO_ 1087 GW_IPC_Time_0x43F: 8 GW
 SG_ IPC_Sec : 45|6@0+ (1,0) [0|59] "second"  BCM,ACM,BSD
 SG_ IPC_Min : 37|6@0+ (1,0) [0|59] "min"  BCM,ACM,BSD
 SG_ IPC_Hour : 28|5@0+ (1,0) [0|23] "hour"  BCM,ACM,BSD
 SG_ IPC_Day : 20|5@0+ (1,0) [1|31] ""  BCM,ACM,BSD
 SG_ IPC_Month : 11|4@0+ (1,0) [1|12] ""  BCM,ACM,BSD
 SG_ IPC_Year : 7|8@0+ (1,2000) [2000|2255] ""  BCM,ACM,BSD
 SG_ IPC_SelfCheckStatus : 15|1@0+ (1,0) [0|1] ""  BCM,ACM,BSD

BO_ 524 GW_IPC_ODO_0x20C: 8 GW
 SG_ Checksum_0x20C : 7|8@0+ (1,0) [0|255] ""  BCM,ACM
 SG_ Rolling_Counter_0x20C : 11|4@0+ (1,0) [0|15] ""  BCM,ACM
 SG_ IPC_ODO : 31|20@0+ (1,0) [0|999999] "km"  BCM,ACM,BSD

BO_ 703 GW_IPC_Information_0x2BF: 8 GW
 SG_ IPC_TripA : 7|16@0+ (0.1,0) [0|999.9] "km"  BCM
 SG_ IPC_AverageSpeedTripA : 27|12@0+ (0.0625,0) [0|250] "km/h"  BCM
 SG_ IPC_AverageConsumptionTripA : 23|10@0+ (0.1,0) [0|100] "kwh/100km"  BCM
 SG_ IPC_ParkBrakeSts : 29|2@0+ (1,0) [0|3] ""  BCM
 SG_ IPC_VehSpd : 54|15@0+ (0.01,0) [0|327.66] "kph"  BCM

BO_ 1025 GW_MHU_DoorSetting_0x401: 8 GW
 SG_ MHU_SET_DoorSpeedLock : 19|4@0+ (1,0) [0|15] ""  BCM
 SG_ MHU_SET_RemoteDoorUnlock_reserve : 28|2@0+ (1,0) [0|3] ""  BCM
 SG_ MHU_SET_RemoteLockFeedback : 31|3@0+ (1,0) [0|7] ""  BCM
 SG_ MHU_SET_AutoUnlockDoor : 35|3@0+ (1,0) [0|7] ""  BCM
 SG_ MHU_SET_MirrorAuto_reserved : 1|2@0+ (1,0) [0|3] ""  BCM
 SG_ MHU_Anti_theftAlarmSet : 15|3@0+ (1,0) [0|7] ""  BCM
 SG_ MHU_TriggerReadKey : 21|2@0+ (1,0) [0|3] ""  BCM

BO_ 1026 GW_MHU_LightSetting_0x402: 8 GW
 SG_ MHU_Heatrearglass_Set : 3|2@0+ (1,0) [0|3] ""  BCM
 SG_ MHU_SET_DayTimeRunningLight_rese : 1|2@0+ (1,0) [0|3] ""  BCM
 SG_ MHU_SET_FollowMeHomeTime : 10|3@0+ (1,0) [0|7] ""  BCM

BO_ 967 GW_MHU_SetIPC_0x3C7: 8 GW
 SG_ MHU_VehsSpd_Warn : 39|15@0+ (0.01,0) [0|120] ""  BCM
 SG_ MHU_SET_Volume : 31|8@0+ (1,0) [0|32] "" Vector__XXX
 SG_ MHU_St_DimmingIPC : 7|4@0+ (1,0) [0|15] ""  BCM

BO_ 1074 GW_TELEMATICS_SERVICES_0x432: 8 GW
 SG_ Checksum_0x432 : 7|8@0+ (1,0) [0|255] ""  BCM,BSD
 SG_ Rolling_Counter_0x432 : 11|4@0+ (1,0) [0|14] ""  BCM,BSD
 SG_ MHU_FOTA_State : 15|4@0+ (1,0) [0|14] ""  BCM,BSD
 SG_ MHU_FOTA_Error_Code : 23|8@0+ (1,0) [0|255] ""  BCM,BSD

BO_ 267 GW_MHU_BCM_RemoteClampCtrl_0x10B: 8 GW
 SG_ TBOX_STAT_TerminalReq : 2|3@0+ (1,0) [0|7] "Bit"  BCM
 SG_ TBOX_AuthCode_0x10B : 55|16@0+ (1,0) [0|65535] ""  BCM

BO_ 269 GW_MHU_BCM_DoorsCtrl_0x10D: 8 GW
 SG_ MHU_BCM_reqTrunk : 7|2@0+ (1,0) [0|3] "Bit"  BCM
 SG_ MHU_BCM_RemoteDoorCtrl : 5|2@0+ (1,0) [0|3] "Bit"  BCM
 SG_ MHU_APM_ReqWindow : 3|3@0+ (1,0) [0|6] ""  BCM
 SG_ TBOX_AuthCode_0x10D : 55|16@0+ (1,0) [0|65535] ""  BCM

BO_ 271 GW_MHU_BCM_HornLightControl_0x10: 8 GW
 SG_ MHU_SetHighBeam : 7|2@0+ (1,0) [0|2] ""  BCM
 SG_ MHU_SetHornOnOff : 5|2@0+ (1,0) [0|2] ""  BCM
 SG_ MHU_SetLowBeam : 3|2@0+ (1,0) [0|2] ""  BCM
 SG_ TBOX_AuthCode_0x10F : 55|16@0+ (1,0) [0|65535] ""  BCM

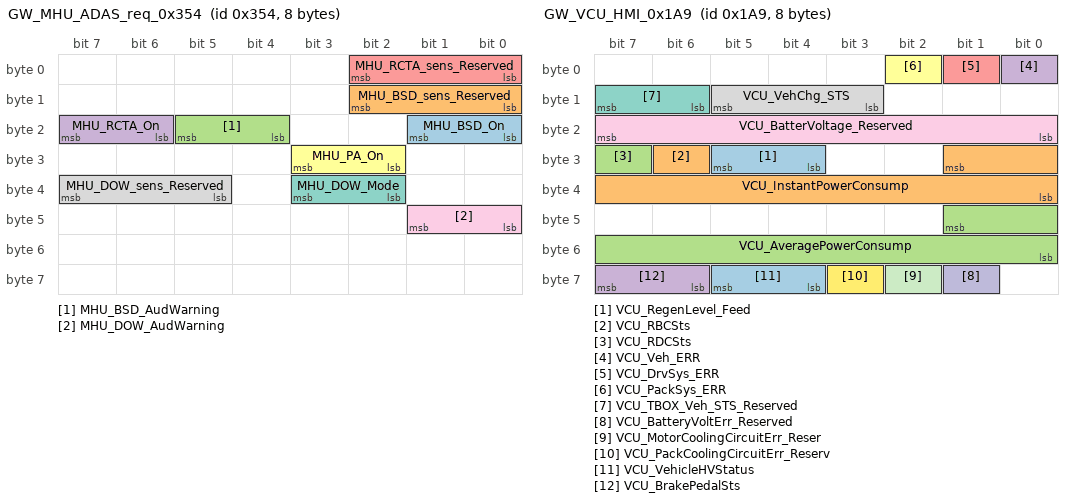
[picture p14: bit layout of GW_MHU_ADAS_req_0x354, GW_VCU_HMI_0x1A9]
BO_ 852 GW_MHU_ADAS_req_0x354: 8 GW
 SG_ MHU_BSD_On : 17|2@0+ (1,0) [0|3] ""  BSD
 SG_ MHU_BSD_sens_Reserved : 10|3@0+ (1,0) [0|3] ""  BSD
 SG_ MHU_BSD_AudWarning : 21|2@0+ (1,0) [0|3] ""  BSD
 SG_ MHU_RCTA_On : 23|2@0+ (1,0) [0|3] ""  BSD
 SG_ MHU_RCTA_sens_Reserved : 2|3@0+ (1,0) [0|3] ""  BSD
 SG_ MHU_PA_On : 27|2@0+ (1,0) [0|3] ""  BSD
 SG_ MHU_DOW_Mode : 35|2@0+ (1,0) [0|3] ""  BSD
 SG_ MHU_DOW_sens_Reserved : 39|3@0+ (1,0) [0|3] ""  BSD
 SG_ MHU_DOW_AudWarning : 41|2@0+ (1,0) [0|3] ""  BSD

BO_ 425 GW_VCU_HMI_0x1A9: 8 GW
 SG_ VCU_RegenLevel_Feed : 29|2@0+ (1,0) [0|3] "" Vector__XXX
 SG_ VCU_RBCSts : 30|1@0+ (1,0) [0|1] "" Vector__XXX
 SG_ VCU_RDCSts : 31|1@0+ (1,0) [0|1] ""  BCM
 SG_ VCU_Veh_ERR : 0|1@0+ (1,0) [0|1] "" Vector__XXX
 SG_ VCU_DrvSys_ERR : 1|1@0+ (1,0) [0|1] "" Vector__XXX
 SG_ VCU_PackSys_ERR : 2|1@0+ (1,0) [0|1] "" Vector__XXX
 SG_ VCU_TBOX_Veh_STS_Reserved : 15|2@0+ (1,0) [0|3] "" Vector__XXX
 SG_ VCU_VehChg_STS : 13|3@0+ (1,0) [0|7] "" Vector__XXX
 SG_ VCU_BatterVoltage_Reserved : 23|8@0+ (0.07,0) [0|17.85] "V"  ACM
 SG_ VCU_BatteryVoltErr_Reserved : 57|1@0+ (1,0) [0|1] "" Vector__XXX
 SG_ VCU_MotorCoolingCircuitErr_Reser : 58|1@0+ (1,0) [0|1] "" Vector__XXX
 SG_ VCU_PackCoolingCircuitErr_Reserv : 59|1@0+ (1,0) [0|1] "" Vector__XXX
 SG_ VCU_VehicleHVStatus : 61|2@0+ (1,0) [0|3] "" Vector__XXX
 SG_ VCU_InstantPowerConsump : 25|10@0+ (0.1,0) [0|100] "kwh/100km" Vector__XXX
 SG_ VCU_AveragePowerConsump : 41|10@0+ (0.1,0) [0|100] "kwh/100km" Vector__XXX
 SG_ VCU_BrakePedalSts : 63|2@0+ (1,0) [0|3] "" Vector__XXX

BO_ 725 GW_VCU_DCDCcontrol_0x2D5: 8 GW
 SG_ VCU_DCDC_Output_REQ : 55|1@0+ (1,0) [0|1] "" Vector__XXX
 SG_ VCU_DCDC_OutVoltage_REQ : 32|9@0+ (0.1,0) [0|50] "V" Vector__XXX
 SG_ VCU_DCDCAllowedPower : 16|9@0+ (0.1,0) [0|50] "KW"  BCM

BO_ 905 GW_VCU_Sts3_0x389: 8 GW
 SG_ VCU_FanControl_Sts : 1|2@0+ (1,0) [0|3] "" Vector__XXX
 SG_ VCU_HVACInletWateTemp : 55|8@0+ (1,-40) [-40|215] "degree" Vector__XXX
 SG_ VCU_IMMO_Sts : 35|2@0+ (1,0) [0|2] ""  BCM
 SG_ VCU_VacuumSts_reserved : 39|2@0+ (1,0) [0|3] "" Vector__XXX
 SG_ VCU_VacuumPresWrn : 37|2@0+ (1,0) [0|3] "" Vector__XXX

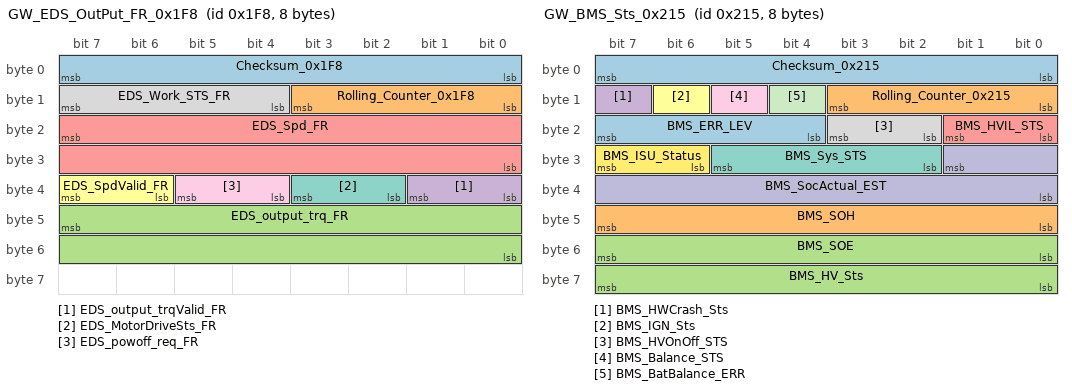
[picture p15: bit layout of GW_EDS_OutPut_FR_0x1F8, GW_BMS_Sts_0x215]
BO_ 504 GW_EDS_OutPut_FR_0x1F8: 8 GW
 SG_ Checksum_0x1F8 : 7|8@0+ (1,0) [0|255] ""  ACM
 SG_ Rolling_Counter_0x1F8 : 11|4@0+ (1,0) [0|15] ""  ACM
 SG_ EDS_output_trq_FR : 47|16@0+ (1,-2000) [-2000|2000] "Nm" Vector__XXX
 SG_ EDS_output_trqValid_FR : 33|2@0+ (1,0) [0|1] "" Vector__XXX
 SG_ EDS_Spd_FR : 23|16@0+ (1,-20000) [-20000|20000] "rpm"  ACM
 SG_ EDS_SpdValid_FR : 39|2@0+ (1,0) [0|1] ""  ACM
 SG_ EDS_MotorDriveSts_FR : 35|2@0+ (1,0) [0|3] "" Vector__XXX
 SG_ EDS_Work_STS_FR : 15|4@0+ (1,0) [0|15] "" Vector__XXX
 SG_ EDS_powoff_req_FR : 37|2@0+ (1,0) [0|1] "" Vector__XXX

BO_ 533 GW_BMS_Sts_0x215: 8 GW
 SG_ Checksum_0x215 : 7|8@0+ (1,0) [0|255] ""  BCM,BSD
 SG_ Rolling_Counter_0x215 : 11|4@0+ (1,0) [0|15] ""  BCM,BSD
 SG_ BMS_SOE : 55|8@0+ (0.5,0) [0|100] "%" Vector__XXX
 SG_ BMS_HWCrash_Sts : 15|1@0+ (1,0) [0|1] "" Vector__XXX
 SG_ BMS_HVIL_STS : 17|2@0+ (1,0) [0|3] "" Vector__XXX
 SG_ BMS_IGN_Sts : 14|1@0+ (1,0) [0|1] "" Vector__XXX
 SG_ BMS_Sys_STS : 29|4@0+ (1,0) [0|15] "" Vector__XXX
 SG_ BMS_HVOnOff_STS : 19|2@0+ (1,0) [0|3] ""  BCM,BSD
 SG_ BMS_Balance_STS : 13|1@0+ (1,0) [0|1] "" Vector__XXX
 SG_ BMS_SocActual_EST : 25|10@0+ (0.1,0) [0|100] "percent" Vector__XXX
 SG_ BMS_BatBalance_ERR : 12|1@0+ (1,0) [0|1] "" Vector__XXX
 SG_ BMS_ISU_Status : 31|2@0+ (1,0) [0|3] "" Vector__XXX
 SG_ BMS_ERR_LEV : 23|4@0+ (1,0) [0|15] "" Vector__XXX
 SG_ BMS_SOH : 47|8@0+ (0.5,0) [0|100] "%" Vector__XXX
 SG_ BMS_HV_Sts : 63|8@0+ (1,0) [0|255] ""  BSD

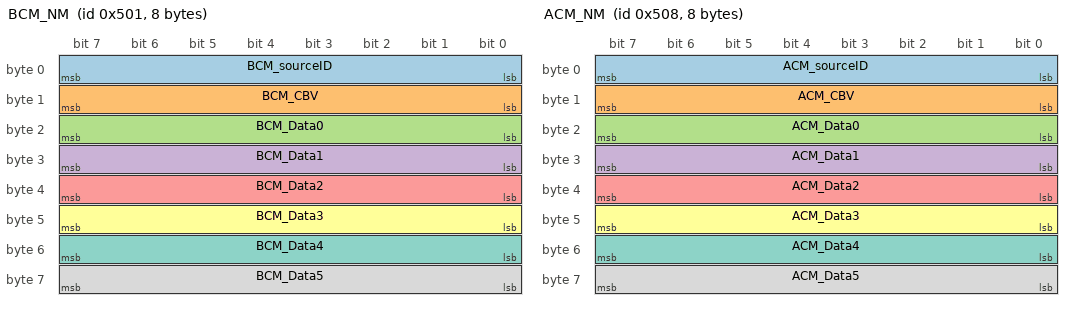
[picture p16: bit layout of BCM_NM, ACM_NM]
BO_ 1281 BCM_NM: 8 BCM
 SG_ BCM_sourceID : 7|8@0+ (1,0) [0|255] ""  GW,ACM,BSD
 SG_ BCM_CBV : 15|8@0+ (1,0) [0|255] ""  GW,ACM,BSD
 SG_ BCM_Data0 : 23|8@0+ (1,0) [0|255] ""  GW,ACM,BSD
 SG_ BCM_Data1 : 31|8@0+ (1,0) [0|255] ""  GW,ACM,BSD
 SG_ BCM_Data2 : 39|8@0+ (1,0) [0|255] ""  GW,ACM,BSD
 SG_ BCM_Data3 : 47|8@0+ (1,0) [0|255] ""  GW,ACM,BSD
 SG_ BCM_Data4 : 55|8@0+ (1,0) [0|255] ""  GW,ACM,BSD
 SG_ BCM_Data5 : 63|8@0+ (1,0) [0|255] ""  GW,ACM,BSD

BO_ 1288 ACM_NM: 8 ACM
 SG_ ACM_sourceID : 7|8@0+ (1,0) [0|255] ""  GW,BCM,BSD
 SG_ ACM_CBV : 15|8@0+ (1,0) [0|255] ""  GW,BCM,BSD
 SG_ ACM_Data0 : 23|8@0+ (1,0) [0|255] ""  GW,BCM,BSD
 SG_ ACM_Data1 : 31|8@0+ (1,0) [0|255] ""  GW,BCM,BSD
 SG_ ACM_Data2 : 39|8@0+ (1,0) [0|255] ""  GW,BCM,BSD
 SG_ ACM_Data3 : 47|8@0+ (1,0) [0|255] ""  GW,BCM,BSD
 SG_ ACM_Data4 : 55|8@0+ (1,0) [0|255] ""  GW,BCM,BSD
 SG_ ACM_Data5 : 63|8@0+ (1,0) [0|255] ""  GW,BCM,BSD

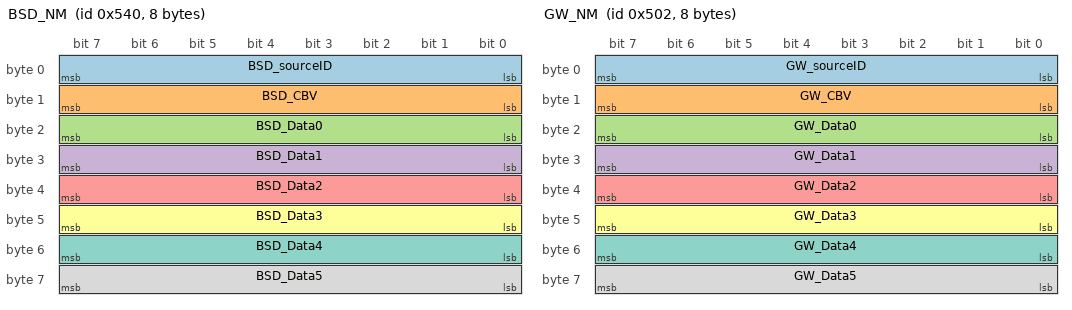
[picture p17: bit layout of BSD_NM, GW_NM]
BO_ 1344 BSD_NM: 8 BSD
 SG_ BSD_sourceID : 7|8@0+ (1,0) [0|255] ""  GW,BCM,ACM
 SG_ BSD_CBV : 15|8@0+ (1,0) [0|255] ""  GW,BCM,ACM
 SG_ BSD_Data0 : 23|8@0+ (1,0) [0|255] ""  GW,BCM,ACM
 SG_ BSD_Data1 : 31|8@0+ (1,0) [0|255] ""  GW,BCM,ACM
 SG_ BSD_Data2 : 39|8@0+ (1,0) [0|255] ""  GW,BCM,ACM
 SG_ BSD_Data3 : 47|8@0+ (1,0) [0|255] ""  GW,BCM,ACM
 SG_ BSD_Data4 : 55|8@0+ (1,0) [0|255] ""  GW,BCM,ACM
 SG_ BSD_Data5 : 63|8@0+ (1,0) [0|255] ""  GW,BCM,ACM

BO_ 1282 GW_NM: 8 GW
 SG_ GW_sourceID : 7|8@0+ (1,0) [0|255] ""  BCM,ACM,BSD
 SG_ GW_CBV : 15|8@0+ (1,0) [0|255] ""  BCM,ACM,BSD
 SG_ GW_Data0 : 23|8@0+ (1,0) [0|255] ""  BCM,ACM,BSD
 SG_ GW_Data1 : 31|8@0+ (1,0) [0|255] ""  BCM,ACM,BSD
 SG_ GW_Data2 : 39|8@0+ (1,0) [0|255] ""  BCM,ACM,BSD
 SG_ GW_Data3 : 47|8@0+ (1,0) [0|255] ""  BCM,ACM,BSD
 SG_ GW_Data4 : 55|8@0+ (1,0) [0|255] ""  BCM,ACM,BSD
 SG_ GW_Data5 : 63|8@0+ (1,0) [0|255] ""  BCM,ACM,BSD

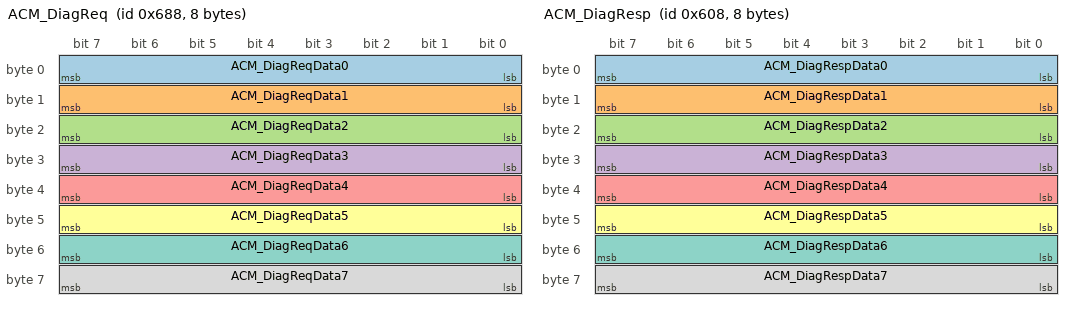
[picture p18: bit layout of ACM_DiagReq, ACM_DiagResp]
BO_ 1672 ACM_DiagReq: 8 GW
 SG_ ACM_DiagReqData0 : 7|8@0+ (1,0) [0|255] ""  ACM
 SG_ ACM_DiagReqData1 : 15|8@0+ (1,0) [0|255] ""  ACM
 SG_ ACM_DiagReqData2 : 23|8@0+ (1,0) [0|255] ""  ACM
 SG_ ACM_DiagReqData3 : 31|8@0+ (1,0) [0|255] ""  ACM
 SG_ ACM_DiagReqData4 : 39|8@0+ (1,0) [0|255] ""  ACM
 SG_ ACM_DiagReqData5 : 47|8@0+ (1,0) [0|255] ""  ACM
 SG_ ACM_DiagReqData6 : 55|8@0+ (1,0) [0|255] ""  ACM
 SG_ ACM_DiagReqData7 : 63|8@0+ (1,0) [0|255] ""  ACM

BO_ 1544 ACM_DiagResp: 8 ACM
 SG_ ACM_DiagRespData0 : 7|8@0+ (1,0) [0|255] ""  GW
 SG_ ACM_DiagRespData1 : 15|8@0+ (1,0) [0|255] ""  GW
 SG_ ACM_DiagRespData2 : 23|8@0+ (1,0) [0|255] ""  GW
 SG_ ACM_DiagRespData3 : 31|8@0+ (1,0) [0|255] ""  GW
 SG_ ACM_DiagRespData4 : 39|8@0+ (1,0) [0|255] ""  GW
 SG_ ACM_DiagRespData5 : 47|8@0+ (1,0) [0|255] ""  GW
 SG_ ACM_DiagRespData6 : 55|8@0+ (1,0) [0|255] ""  GW
 SG_ ACM_DiagRespData7 : 63|8@0+ (1,0) [0|255] ""  GW

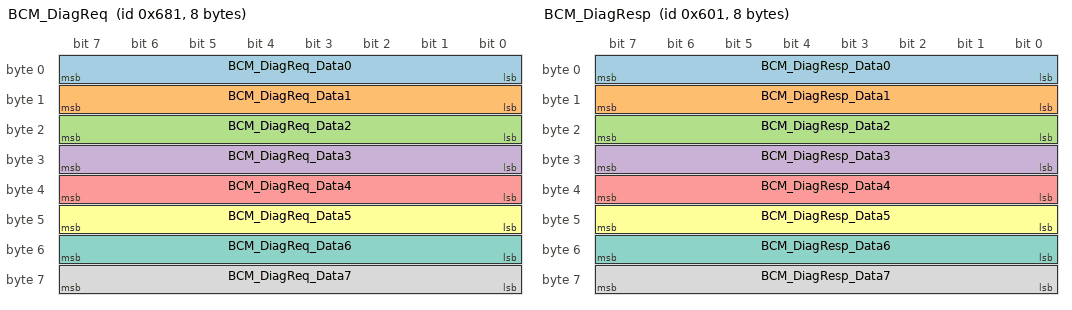
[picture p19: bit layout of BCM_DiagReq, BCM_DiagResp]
BO_ 1665 BCM_DiagReq: 8 GW
 SG_ BCM_DiagReq_Data0 : 7|8@0+ (1,0) [0|255] ""  BCM
 SG_ BCM_DiagReq_Data1 : 15|8@0+ (1,0) [0|255] ""  BCM
 SG_ BCM_DiagReq_Data2 : 23|8@0+ (1,0) [0|255] ""  BCM
 SG_ BCM_DiagReq_Data3 : 31|8@0+ (1,0) [0|255] ""  BCM
 SG_ BCM_DiagReq_Data4 : 39|8@0+ (1,0) [0|255] ""  BCM
 SG_ BCM_DiagReq_Data5 : 47|8@0+ (1,0) [0|255] ""  BCM
 SG_ BCM_DiagReq_Data6 : 55|8@0+ (1,0) [0|255] ""  BCM
 SG_ BCM_DiagReq_Data7 : 63|8@0+ (1,0) [0|255] ""  BCM

BO_ 1537 BCM_DiagResp: 8 BCM
 SG_ BCM_DiagResp_Data0 : 7|8@0+ (1,0) [0|255] ""  GW
 SG_ BCM_DiagResp_Data1 : 15|8@0+ (1,0) [0|255] ""  GW
 SG_ BCM_DiagResp_Data2 : 23|8@0+ (1,0) [0|255] ""  GW
 SG_ BCM_DiagResp_Data3 : 31|8@0+ (1,0) [0|255] ""  GW
 SG_ BCM_DiagResp_Data4 : 39|8@0+ (1,0) [0|255] ""  GW
 SG_ BCM_DiagResp_Data5 : 47|8@0+ (1,0) [0|255] ""  GW
 SG_ BCM_DiagResp_Data6 : 55|8@0+ (1,0) [0|255] ""  GW
 SG_ BCM_DiagResp_Data7 : 63|8@0+ (1,0) [0|255] ""  GW

BO_ 1728 BSD_DiagReq: 8 GW
 SG_ BSD_DiagReq_Data0 : 7|8@0+ (1,0) [0|255] ""  BSD
 SG_ BSD_DiagReq_Data1 : 15|8@0+ (1,0) [0|255] ""  BSD
 SG_ BSD_DiagReq_Data2 : 23|8@0+ (1,0) [0|255] ""  BSD
 SG_ BSD_DiagReq_Data3 : 31|8@0+ (1,0) [0|255] ""  BSD
 SG_ BSD_DiagReq_Data4 : 39|8@0+ (1,0) [0|255] ""  BSD
 SG_ BSD_DiagReq_Data5 : 47|8@0+ (1,0) [0|255] ""  BSD
 SG_ BSD_DiagReq_Data6 : 55|8@0+ (1,0) [0|255] ""  BSD
 SG_ BSD_DiagReq_Data7 : 63|8@0+ (1,0) [0|255] ""  BSD

BO_ 1600 BSD_DiagResp: 8 BSD
 SG_ BSD_DiagResp_Data0 : 7|8@0+ (1,0) [0|255] ""  GW
 SG_ BSD_DiagResp_Data1 : 15|8@0+ (1,0) [0|255] ""  GW
 SG_ BSD_DiagResp_Data2 : 23|8@0+ (1,0) [0|255] ""  GW
 SG_ BSD_DiagResp_Data3 : 31|8@0+ (1,0) [0|255] ""  GW
 SG_ BSD_DiagResp_Data4 : 39|8@0+ (1,0) [0|255] ""  GW
 SG_ BSD_DiagResp_Data5 : 47|8@0+ (1,0) [0|255] ""  GW
 SG_ BSD_DiagResp_Data6 : 55|8@0+ (1,0) [0|255] ""  GW
 SG_ BSD_DiagResp_Data7 : 63|8@0+ (1,0) [0|255] ""  GW

BO_ 1791 GW_DiagFunctionalAddressing: 8 GW
 SG_ GW_DiagFunctionalAddressingData0 : 7|8@0+ (1,0) [0|255] ""  BCM,ACM,BSD
 SG_ GW_DiagFunctionalAddressingData1 : 15|8@0+ (1,0) [0|255] ""  BCM,ACM,BSD
 SG_ GW_DiagFunctionalAddressingData2 : 23|8@0+ (1,0) [0|255] ""  BCM,ACM,BSD
 SG_ GW_DiagFunctionalAddressingData3 : 31|8@0+ (1,0) [0|255] ""  BCM,ACM,BSD
 SG_ GW_DiagFunctionalAddressingData4 : 39|8@0+ (1,0) [0|255] ""  BCM,ACM,BSD
 SG_ GW_DiagFunctionalAddressingData5 : 47|8@0+ (1,0) [0|255] ""  BCM,ACM,BSD
 SG_ GW_DiagFunctionalAddressingData6 : 55|8@0+ (1,0) [0|255] ""  BCM,ACM,BSD
 SG_ GW_DiagFunctionalAddressingData7 : 63|8@0+ (1,0) [0|255] ""  BCM,ACM,BSD

CM_ SG_ 133 Checksum_0x85 "Checksum";
CM_ SG_ 133 Rolling_Counter_0x85 "Rolling Counter";
CM_ SG_ 133 ACM_Crash_Sts "Crash status";
CM_ SG_ 133 ACM_Airbag_Deployment_Status "Signal to indicate if airbag/pretensioner/pyrofuse is deployed";
CM_ SG_ 133 ACM_Crash_Intensity "Indicate crash intensity level";
CM_ SG_ 133 ACM_Front_Crash "Output information for direction of crash";
CM_ SG_ 133 ACM_DriverSide_Crash "Output information for direction of crash";
CM_ SG_ 133 ACM_PassSide_Crash "Output information for direction of crash";
CM_ SG_ 133 ACM_Rear_Crash "Output information for direction of crash";
CM_ SG_ 133 ACM_Rollover_Crash "Output information for direction of crash";
CM_ SG_ 897 Checksum_0x381 "Checksum";
CM_ SG_ 897 Rolling_Counter_0x381 "Rolling Counter";
CM_ SG_ 897 ACM_Seat_Occupancy_Passenger "Signal to indicate status of occupancy";
CM_ SG_ 897 ACM_Seat_Occupancy_2nd_Row_Dri_r "Signal to indicate status of occupancy";
CM_ SG_ 897 ACM_Seat_Occupancy_2nd_Row_Pas_r "Signal to indicate status of occupancy";
CM_ SG_ 897 ACM_Seat_Occupancy_2nd_Row_Mid_r "Signal to indicate status of occupancy";
CM_ SG_ 897 ACM_Seat_Belt_Status_Passenger "Seatbelt status for seatbelt reminder function";
CM_ SG_ 897 ACM_Seat_Belt_Status_Driver "Seatbelt status for seatbelt reminder function";
CM_ SG_ 897 ACM_Seat_Belt_Status_2nd_Row_Dri "Seatbelt status for seatbelt reminder function";
CM_ SG_ 897 ACM_Seat_Belt_Status_2nd_Row_Mid "Seatbelt status for seatbelt reminder function";
CM_ SG_ 897 ACM_Seat_Belt_Status_2nd_Row_Pas "Seatbelt status for seatbelt reminder function";
CM_ SG_ 897 ACM_Seat_Belt_Status_3rd_Row_Dri "Seatbelt status for seatbelt reminder function";
CM_ SG_ 897 ACM_Seat_Belt_Status_3rd_Row_Pas "Seatbelt status for seatbelt reminder function";
CM_ SG_ 1160 Checksum_0x488 "Checksum";
CM_ SG_ 1160 Rolling_Counter_0x488 "Rolling Counter";
CM_ SG_ 1160 ACM_Malfunction "ACM Malfunction (trigger airbag warning lamp)";
CM_ SG_ 1160 ACM_Pre_Drive_Check "ACM status after pre-drive check (trigger airbag warning lamp if any failure)";
CM_ SG_ 1160 ACM_in_Plant_Mode "ACM plant mode status (trigger airbag warning lamp)";
CM_ SG_ 1160 ACM_PAB_Suppression "ACM suppress passenger airbag (front AB 1st stage, front AB 2nd stage, knee AB). This is used to trigger PAB indicator in MHU's display.";
CM_ SG_ 1160 ACM_Airbag_Disabled "ACM airbag disabled status due to Algo disabled or Firing disabled due to diagnostic or inert calibration file is flashed (trigger Airbag warning lamp when airbag is disabled)";
CM_ SG_ 1160 ACM_Development_Calibration "ACM calibration file status indicate whether ACM is flashed with calibration file for development purpose only (trigger Airbag warning lamp and chime when ACM is flashed with development calibration file)";
CM_ SG_ 1160 ACM_In_Disposal_Mode "ACM disposal mode status (trigger airbag warning lamp when ACM in disposal mode)";
CM_ SG_ 1160 ACM_Seatbelt_Reminder_Request "ACM request seatbelt reminder (1 signal for whole front and rear seats)";
CM_ SG_ 1160 ACM_SBR_Chime_Req "ACM request chime to MHU for seatbelt reminder front row";
CM_ SG_ 1160 ACM_SBR_Blinking_Req "ACM send blinking request to MHU (trigger blinking of seatbelt reminder lamp)";
CM_ SG_ 1053 BCM_STAT_RemoteLockFeedback "Remote Lock dback: customer can choose light feedback when lock or unlock the door with remote key";
CM_ SG_ 1053 BCM_STAT_RemoteDoorUnlock_reserv "Settings for Door lock unlock conditions";
CM_ SG_ 1053 BCM_STAT_AutoDoorUnlock "Auto door unlock: When the car is stopped and the shift lever is in “P ” or “N ” position, selected doors will be unlocked automatically";
CM_ SG_ 1053 BCM_STAT_DoorSpeedLock "Status feedback from BCM for Setting Door speed lock mode";
CM_ SG_ 1053 BCM_STAT_DayTimeRunningLight_res "BCM send out status for On Off Day Time Running Light";
CM_ SG_ 1053 BCM_STAT_AntiTheftMode "Confirm of setting Anti-theft mode";
CM_ SG_ 1053 BCM_FOBID_userprofile_link "Only use for link the keyfob into user profile";
CM_ SG_ 1053 BCM_feedback_FollowMeHomeTime "Feedback the time of Follow Me Home light";
CM_ SG_ 303 Checksum_0x12f "Checksum";
CM_ SG_ 303 Rolling_Counter_0x12f "Rolling_Counter";
CM_ SG_ 303 ST_KL_KEY_VLD "Key valid";
CM_ SG_ 303 ST_SSP "Status SSB";
CM_ SG_ 303 BCM_IMMO_Sts "IMMO staus";
CM_ SG_ 259 Q_Discharge "Negative";
CM_ SG_ 259 Q_Charge "Positive";
CM_ SG_ 259 RQ_DCDC_U "Voltage request for DCDC using power management";
CM_ SG_ 259 REQ_ConsumerControlAudioVolumeCo "Consumer control audio volume for powermanagement";
CM_ SG_ 259 REQ_CCU_PTC_Limitation "Consumer control PTC for powermanagement";
CM_ SG_ 261 Checksum_0x105 "Checksum";
CM_ SG_ 261 Rolling_Counter_0x105 "Rolling_Counter";
CM_ SG_ 261 BCM_STAT_TrunkAjar "Trunk Ajar Door Status";
CM_ SG_ 261 BCM_STAT_DoorAjarDriver "Ajar Door Driver Status";
CM_ SG_ 261 BCM_STAT_DoorAjarPassenger "Ajar Door Passenger Status";
CM_ SG_ 261 BCM_STAT_DoorAjarRL "Ajar Door Rear Left Status";
CM_ SG_ 261 BCM_STAT_DoorAjarRR "Ajar Door Rear Right Status";
CM_ SG_ 261 BCM_STAT_BonnetAjar "Ajar Bonnet Status";
CM_ SG_ 262 Checksum_0x106 "Checksum";
CM_ SG_ 262 Rolling_Counter_0x106 "Rolling_Counter";
CM_ SG_ 262 BCM_HighBeamSts "High beam output Status";
CM_ SG_ 262 BCM_LowBeamSts "Low beam output  Status";
CM_ SG_ 262 BCM_PosLmpSts "Position light output Status";
CM_ SG_ 262 BCM_TurnIndicatorSts "Turn light output  Status";
CM_ SG_ 262 BCM_DayRunningLampSts_reserved "DayRunning Lamp output Status";
CM_ SG_ 262 BCM_ReverseLightSts "Reverse light output Status";
CM_ SG_ 262 BCM_StopLightSts "Stop light output Status";
CM_ SG_ 262 BCM_Fr_Dimming_dome_lampSts "Dimming dome lamp Front Status";
CM_ SG_ 262 BCM_Heated_rearglass "Heate Rear Glass  Feedback";
CM_ SG_ 262 BCM_BsdLightSts "Indicates BSD status";
CM_ SG_ 262 BCM_STAT_LightActivation "Status of light";
CM_ SG_ 262 BCM_STAT_InteriorLight "status of backlight illumination";
CM_ SG_ 263 Checksum_0x107 "Checksum";
CM_ SG_ 263 Rolling_Counter_0x107 "Rolling_Counter";
CM_ SG_ 263 STAT_ATWS "Locking/UnLocking Status Anti theft Invalid value = 7";
CM_ SG_ 263 STAT_DoorLockDriver "Lock Status Driver Door used as central lock information(lock/unlock the vehicle by the fob/PESW/CentralLock button)";
CM_ SG_ 265 Checksum_0x109 "Checksum";
CM_ SG_ 265 Rolling_Counter_0x109 "Rolling_Counter";
CM_ SG_ 265 BCM_STAT_HazardWarn "Hazard Warning switch activation";
CM_ SG_ 265 BCM_STAT_Horn_Reserved "Status switch horn";
CM_ SG_ 265 BCM_STAT_WiperStalkSW "Status of Wiper stalk SW";
CM_ SG_ 265 BCM_STAT_WiperStalkSW2 "Status of Wiper stalk SW2(rear wiper and washer)";
CM_ SG_ 265 BCM_LigntSensor "BCM  LIGHT  SENSOR State";
CM_ SG_ 265 BCM_STAT_lampStalkSW1 "the position of stalk which control the Master light switch status";
CM_ SG_ 265 BCM_STAT_lampStalkSW2 "the position of stalk which control the low beam and high beam status";
CM_ SG_ 266 Checksum_0x10a "Checksum";
CM_ SG_ 266 Rolling_Counter_0x10a "Rolling_Counter";
CM_ SG_ 266 BCM_LVTop_up "LV  battery top up requice signal";
CM_ SG_ 266 Ubatt_Reserved "Battery Voltage(UBatt to be received by all modules,Required for DTC snapshots)";
CM_ SG_ 270 RemoteAccessKey "Status of remote key button Tailgate opening long press > 1.5 sec";
CM_ SG_ 270 PassiveAccessTrunk "BCM request for passive entry trunk";
CM_ SG_ 270 BCM_CurrentValid_FOB "Current valid of FOB ID";
CM_ SG_ 283 BCM_ACCRelayOutputSts "ACCRelays Output Status";
CM_ SG_ 283 BCM_IGN1RelayOutputSts "IG1 Relays Output Status";
CM_ SG_ 283 BCM_ACCRelayFalutSts "ACCRelays Fault Status";
CM_ SG_ 283 BCM_IGN1RelayFalutSts "IG1 Relays Fault Status";
CM_ SG_ 283 BCM_KEY_MatchSts "Match status with Key";
CM_ SG_ 274 Checksum_0x112 "Checksum";
CM_ SG_ 274 Rolling_Counter_0x112 "Rolling_Counter";
CM_ SG_ 274 STAT_Terminal "Represent the status of physical terminal(STAT_Terminal to be received by all modules,Required for DTC snapshots and for FOTA)";
CM_ SG_ 274 STAT_CL30s_L_Reserved "Status Clamp 30s Logical ON/OFF";
CM_ SG_ 529 PEPS_Lock_IGNNotOff_Alert "Power ON Alarm When Lock The Vehicle By key fob";
CM_ SG_ 529 PEPS_CID_NotInside_Alert "Key Not In Side Alarm When Start";
CM_ SG_ 529 PEPS_CID_Left_Alert "Key Left Alter";
CM_ SG_ 529 PEPS_RMKey_BatteryLow_Alert "Remote Key_Battery Low_Alert";
CM_ SG_ 529 PEPS_PressBrakePedal_Alert "Press Brake Pedal Alert";
CM_ SG_ 529 PEPS_Shift_Position_Alert "Shift_Position_AlertP/N（VCU）";
CM_ SG_ 529 PEPS_Lock_KeyInside_Alert "KeyInside Alert When Lock The Vehicle By Door Handler";
CM_ SG_ 529 PEPS_EmergencyStop_Reserved "Emergency Stop (reserved)";
CM_ SG_ 529 PEPS_CID_NotIndenfied_Alert "PEPS CID NotIndenfied Alert";
CM_ SG_ 529 BCM_Positionlight_reminder "reminde driver forgot turn OFF the position light when vehicle go to off";
CM_ SG_ 525 Checksum_0x20D "Checksum";
CM_ SG_ 525 Rolling_Counter_0x20D "Rolling_Counter";
CM_ SG_ 525 BCM_ODO "odograph";
CM_ SG_ 268 Checksum_0x10C "Checksum";
CM_ SG_ 268 Rolling_Counter_0x10C "Rolling_Counter";
CM_ SG_ 268 BCM_TboxAuthStatus "MHU's TBOX authentication status";
CM_ SG_ 268 BCM_RandomNum32bit "BCM's random OTP 32 bits and refresh every 20 secs";
CM_ SG_ 272 Checksum_0x110 "Checksum";
CM_ SG_ 272 Rolling_Counter_0x110 "Rolling_Counter";
CM_ SG_ 272 BCM_APM_FLWIN_Postion "FL window postion";
CM_ SG_ 272 BCM_APM_FRWIN_Postion "FR window postion";
CM_ SG_ 272 BCM_APM_RLWIN_Postion "RL window postion";
CM_ SG_ 272 BCM_APM_RRWIN_Postion "RR window postion";
CM_ SG_ 272 APM_Status "APM_Status";
CM_ SG_ 272 ChildProtectionStatus "Child Protection Status";
CM_ SG_ 272 APM_Window_DriveSW_FL_Status "Driver's window switch - left front window switch status";
CM_ SG_ 272 APM_Window_DriveSW_FR_Status "Driver's window switch - right front window switch status";
CM_ SG_ 272 APM_Window_DriveSW_RL_Status "Driver's window switch - left rear window switch status";
CM_ SG_ 272 APM_Window_DriveSW_RR_Status "Driver's window switch - right rear window switch status";
CM_ SG_ 272 APM_Window_PassengerSW_Status "Passenger's window switch - window switch status";
CM_ SG_ 272 APM_Window_PassengerSW_RL_Status "Passenger's window switch - left rear window switch status";
CM_ SG_ 272 APM_Window_PassengerSW_RR_Status "Passenger's window switch - right rear window switch status";
CM_ SG_ 923 BCM_Immo_MHU_Byte_0 "BCM Authentication signal byte 0 with MHU";
CM_ SG_ 923 BCM_Immo_MHU_Byte_1 "BCM Authentication signal byte 1 with MHU";
CM_ SG_ 923 BCM_Immo_MHU_Byte_2 "BCM Authentication signal byte 2 with MHU";
CM_ SG_ 923 BCM_Immo_MHU_Byte_3 "BCM Authentication signal byte 3 with MHU";
CM_ SG_ 923 BCM_Immo_MHU_Byte_4 "BCM Authentication signal byte 4 with MHU";
CM_ SG_ 923 BCM_Immo_MHU_Byte_5 "BCM Authentication signal byte 5 with MHU";
CM_ SG_ 923 BCM_Immo_MHU_Byte_6 "BCM Authentication signal byte 6 with MHU";
CM_ SG_ 923 BCM_Immo_MHU_Byte_7 "BCM Authentication signal byte 7 with MHU";
CM_ SG_ 922 MHU_Immo_Byte_0 "MHU Authentication signal byte 0";
CM_ SG_ 922 MHU_Immo_Byte_1 "MHU Authentication signal byte 1";
CM_ SG_ 922 MHU_Immo_Byte_2 "MHU Authentication signal byte 2";
CM_ SG_ 922 MHU_Immo_Byte_3 "MHU Authentication signal byte 3";
CM_ SG_ 922 MHU_Immo_Byte_4 "MHU Authentication signal byte 4";
CM_ SG_ 922 MHU_Immo_Byte_5 "MHU Authentication signal byte 5";
CM_ SG_ 922 MHU_Immo_Byte_6 "MHU Authentication signal byte 6";
CM_ SG_ 922 MHU_Immo_Byte_7 "MHU Authentication signal byte 7";
CM_ SG_ 920 BCM_Immo_Byte_0 "BCM Authentication signal byte 0";
CM_ SG_ 920 BCM_Immo_Byte_1 "BCM Authentication signal byte 1";
CM_ SG_ 920 BCM_Immo_Byte_2 "BCM Authentication signal byte 2";
CM_ SG_ 920 BCM_Immo_Byte_3 "BCM Authentication signal byte 3";
CM_ SG_ 920 BCM_Immo_Byte_4 "BCM Authentication signal byte 4";
CM_ SG_ 920 BCM_Immo_Byte_5 "BCM Authentication signal byte 5";
CM_ SG_ 920 BCM_Immo_Byte_6 "BCM Authentication signal byte 6";
CM_ SG_ 920 BCM_Immo_Byte_7 "BCM Authentication signal byte 7";
CM_ SG_ 921 VCU_Immo_Byte_0 "VCU Authentication signal byte 0";
CM_ SG_ 921 VCU_Immo_Byte_1 "VCU Authentication signal byte 1";
CM_ SG_ 921 VCU_Immo_Byte_2 "VCU Authentication signal byte 2";
CM_ SG_ 921 VCU_Immo_Byte_3 "VCU Authentication signal byte 3";
CM_ SG_ 921 VCU_Immo_Byte_4 "VCU Authentication signal byte 4";
CM_ SG_ 921 VCU_Immo_Byte_5 "VCU Authentication signal byte 5";
CM_ SG_ 921 VCU_Immo_Byte_6 "VCU Authentication signal byte 6";
CM_ SG_ 921 VCU_Immo_Byte_7 "VCU Authentication signal byte 7";
CM_ SG_ 296 Checksum_0x128 "Checksum";
CM_ SG_ 296 Rolling_Counter_0x128 "Rolling_Counter";
CM_ SG_ 296 ADAS_RCTA_IndLeft "Left Rear Cross Traffic Alert (RCTA) System Warning";
CM_ SG_ 296 ADAS_RCTA_IndRight "Right Rear Cross Traffic Alert (RCTA) System Warning";
CM_ SG_ 296 ADAS_RCTA_SndWarn "Rear Cross Traffic Alert warning sound en disable";
CM_ SG_ 296 ADAS_RCTA_check "Rear Cross Traffic Alert Check";
CM_ SG_ 296 ADAS_RCTA_state "Rear Cross Traffic Alert  Warning State";
CM_ SG_ 296 ADAS_RCTA_sens_Feed_Reserved "Rear Cross Traffic Alert  Warning Sensitivity Feedback";
CM_ SG_ 296 ADAS_RCTA_Mode_Feed "Rear Cross Traffic Alert  Warning On Off Feedback";
CM_ SG_ 307 Checksum_0x133 "Checksum";
CM_ SG_ 307 Rolling_Counter_0x133 "Rolling_Counter";
CM_ SG_ 307 ADAS_BSD_check "Blind Sport Detection Check";
CM_ SG_ 307 ADAS_BSD_state "Blind Sport Detection State Feedback";
CM_ SG_ 307 ADAS_BSD_AudChime_Feed "Blind Sport Detection Audible Chime Feedback";
CM_ SG_ 307 ADAS_BSD_IndLeft "Left Blind Sport Detection Warning";
CM_ SG_ 307 ADAS_BSD_IndRight "Right Blind Sport Detection Warning";
CM_ SG_ 307 ADAS_BSD_SndWarn "Rear Blind Sport Detection warning sound en disable";
CM_ SG_ 307 ADAS_BSD_Mode_Feed "Blind Sport Detection On Off Feedback";
CM_ SG_ 307 ADAS_BSD_sens_Feed "Blind Sport Detection sensitivity Feedback";
CM_ SG_ 850 Checksum_0x352 "Checksum";
CM_ SG_ 850 Rolling_Counter_0x352 "Rolling_Counter";
CM_ SG_ 850 ADAS_DOW_Warn "Left Right Door Open Warning";
CM_ SG_ 850 ADAS_DOW_SndWarn "Door Open Sound Warning en disable";
CM_ SG_ 850 ADAS_DOW_state "Door Open Warning State";
CM_ SG_ 850 ADAS_DOW_IndLeft "Left   Door Open Warning";
CM_ SG_ 850 ADAS_DOW_IndRight "Right Door Open Warning";
CM_ SG_ 850 ADAS_DOW_sens_Feed_Reserved "Door Open Warning sensitivity Feedback";
CM_ SG_ 850 ADAS_DOW_Mode_Feed "Door Open Warning Mode select Feedback";
CM_ SG_ 850 ADAS_DOW_AudChime_Feed "DOW audit chime On off Feedback";
CM_ SG_ 850 ADAS_DOW_check "Door Opening Warning Check";
CM_ SG_ 1216 Checksum_0x4C0 "Checksum";
CM_ SG_ 1216 Rolling_Counter_0x4C0 "Rolling_Counter";
CM_ SG_ 1216 ADAS_Warning_Flag_1 "Warning Message Flag, Component owner, Supplier align and define for this signal";
CM_ SG_ 1216 ADAS_Warning_Flag_2 "Warning Message Flag, Component owner, Supplier align and define for this signal";
CM_ SG_ 1216 ADAS_Warning_Flag_3 "Warning Message Flag, Component owner, Supplier align and define for this signal";
CM_ SG_ 1216 ADAS_Warning_Flag_4 "Warning Message Flag, Component owner, Supplier align and define for this signal";
CM_ SG_ 1216 ADAS_Warning_Flag_5 "Warning Message Flag, Component owner, Supplier align and define for this signal";
CM_ SG_ 1216 ADAS_Warning_Flag_6 "Warning Message Flag, Component owner, Supplier align and define for this signal";
CM_ SG_ 1216 ADAS_Warning_Flag_7 "Corner Short Range Rear Left Radar temporary not available";
CM_ SG_ 1216 ADAS_Warning_Flag_8 "Corner Short Range Rear Left Radar permanently not available";
CM_ SG_ 1216 ADAS_Warning_Flag_9 "Corner Short Range Rear Right Radar temporary not available";
CM_ SG_ 1216 ADAS_Warning_Flag_10 "Corner Short Range Rear Right Radar permanently not available";
CM_ SG_ 1216 ADAS_Warning_Flag_11 "Warning Message Flag, Component owner, Supplier align and define for this signal";
CM_ SG_ 1216 ADAS_Warning_Flag_12 "Warning Message Flag, Component owner, Supplier align and define for this signal";
CM_ SG_ 1216 ADAS_Warning_Flag_13 "Warning Message Flag, Component owner, Supplier align and define for this signal";
CM_ SG_ 1216 ADAS_Warning_Flag_14 "I-ECU has BSD function fault : speed /gear loss";
CM_ SG_ 1216 ADAS_Warning_Flag_15 "I-ECU has RCTA function fault.speed /gear loss";
CM_ SG_ 1216 ADAS_Warning_Flag_16 "Warning Message Flag, Component owner, Supplier align and define for this signal";
CM_ SG_ 1216 ADAS_Warning_Flag_17 "I-ECU has DOW function fault: speed /gear loss";
CM_ SG_ 1216 ADAS_Warning_Flag_18 "Warning Message Flag, Component owner, Supplier align and define for this signal";
CM_ SG_ 1216 ADAS_Warning_Flag_19 "Warning Message Flag, Component owner, Supplier align and define for this signal";
CM_ SG_ 1216 ADAS_Warning_Flag_20 "Warning Message Flag, Component owner, Supplier align and define for this signal";
CM_ SG_ 1216 ADAS_Warning_Flag_21 "LeftCornerRadaar Install Faulty";
CM_ SG_ 1216 ADAS_Warning_Flag_22 "RightCornerRadaar Install Faulty";
CM_ SG_ 1216 ADAS_Warning_Flag_23 "LeftCornerRadaar Calib Faulty";
CM_ SG_ 1216 ADAS_Warning_Flag_24 "RightCornerRadaar Calib Faulty";
CM_ SG_ 1216 ADAS_Warning_Flag_25 "Warning Message Flag, Component owner, Supplier align and define for this signal";
CM_ SG_ 1216 ADAS_Warning_Flag_26 "Warning Message Flag, Component owner, Supplier align and define for this signal";
CM_ SG_ 1216 ADAS_Warning_Flag_27 "Warning Message Flag, Component owner, Supplier align and define for this signal";
CM_ SG_ 1216 ADAS_Warning_Flag_28 "Warning Message Flag, Component owner, Supplier align and define for this signal";
CM_ SG_ 1216 ADAS_Reserved_signal3 "Warning Message Flag, Component owner, Supplier align and define for this signal";
CM_ SG_ 1216 ADAS_Reserved_signal4 "Warning Message Flag, Component owner, Supplier align and define for this signal";
CM_ SG_ 1216 ADAS_Reserved_signal5 "Warning Message Flag, Component owner, Supplier align and define for this signal";
CM_ SG_ 851 Checksum_0x353 "Checksum";
CM_ SG_ 851 Rolling_Counter_0x353 "Rolling_Counter";
CM_ SG_ 851 ADAS_RadarRight_Cal_Status "BSD right calibration Status";
CM_ SG_ 851 ADAS_RadarLeft_Cal_Status "BSD left calibration Status";
CM_ SG_ 851 ADAS_RadarRight_DynaCal_Status "BSD right dynamic calibration status";
CM_ SG_ 851 ADAS_RadarLeft_DynaCal_Status "BSD left dynamic calibration status";
CM_ SG_ 851 ADAS_MasterSRR_check "Master Corner radar Check";
CM_ SG_ 851 ADAS_SlaveSRR_check "Slave Corner radar Check";
CM_ SG_ 851 ADAS_CalSensorMasterProgress "Master(Left) radar calibration progress when get in";
CM_ SG_ 851 ADAS_CalSensorSlaverProgress "Slaver(Right) radar calibration progress when get in";
CM_ SG_ 851 ADAS_Cal_LeftInstallDeviation "left radar install angle deviation  from auto calibration";
CM_ SG_ 851 ADAS_Cal_RightInstallDeviation "right radar install angle deviation  from auto calibration";
CM_ SG_ 834 Checksum_0x342 "Check sum";
CM_ SG_ 834 RollingCounter_0x342 "Rolling Counter";
CM_ SG_ 834 ABS_LRWhlSpdRaw "Current Raw wheel speed information of rear left wheel.";
CM_ SG_ 834 ABS_LRWhlSpdRawValid "Current Raw wheel speed information valid flag of rear left wheel.";
CM_ SG_ 834 ABS_RRWhlSpdRaw "Current Raw wheel speed information of rear right wheel.";
CM_ SG_ 834 ABS_RRWhlSpdRawValid "Current Raw wheel speed information valid flag of rear right wheel";
CM_ SG_ 834 ABS_VehSpd "Current Longitudinal Vehicle Speed";
CM_ SG_ 834 ABS_VehSpdValid "Speed Valid Flag";
CM_ SG_ 322 Checksum_0x142 "check sum";
CM_ SG_ 322 RollingCounter_0x142 "Rolling counter";
CM_ SG_ 322 AbsDiagSessionLampReq_Reserved "ABS or ESC is currently in safety system diagnostic  session,(DVT mode) need cluster to turn on ESC/TCS, EBD, ABS fault lamp";
CM_ SG_ 322 ABS_AbsCtrlActv "ABS status(Indiacte ABS  function is active or not.When ABS intervention starts,it sets as 1)ABS";
CM_ SG_ 322 ABS_EbdFlgFlt "The EBD system fault, The EBD warning lamp should be open,The signal will be set as  whenEBD is disable due to faultEBD";
CM_ SG_ 322 ABS_AbsFlgFlt "The ABS system fault, The ABS warning lamp should be open,The signal will be set as whenABS is disable due to fault";
CM_ SG_ 322 ABS_ESS_Active "Emergency Stop Signaling Active,when emergency stop, this signal will set true";
CM_ SG_ 322 ABS_LowBrakeFluid "Detect the brake fluid level";
CM_ SG_ 306 Checksum_0x132 "check sum";
CM_ SG_ 306 RollingCounter_0x132 "Rolling counter";
CM_ SG_ 306 ESC_HSA_Control_Status "Indicate HSA function is active or not";
CM_ SG_ 306 ESC_HSA_Status_Fault "Detect the HAS Fault status";
CM_ SG_ 306 ESC_TcsDisableSts "Indicate the TCS function can use or not";
CM_ SG_ 306 ESC_TcsCtrlActv "Indicate TCS  function is active or not";
CM_ SG_ 306 ESC_TcsFlgFlt "Detect the TCS function fault status";
CM_ SG_ 306 ESC_EscDisableSts "Indicate the ESC function can use or not";
CM_ SG_ 306 ESC_EscCtrlActv "Indicate ESC  function is active or not";
CM_ SG_ 306 ESC_EscFlgFlt "Detect the ESC function fault status";
CM_ SG_ 306 ESC_HBAFlgFlt "Detect the HBA(Hydraulic Brake Assist) function status";
CM_ SG_ 306 ESC_HbaCtrlActv "Indicate HBA(Hydraulic Brake Assist)   function is active or not";
CM_ SG_ 306 ESC_SlopeGradeAngle "Vehicle slope,Uphill is negative (head is higher than tail), downhill is positive (tail is higher than head)";
CM_ SG_ 306 ESC_MasterCylinderPressure "Master cylinder pressure";
CM_ SG_ 994 Checksum_0x3E2 "check sum";
CM_ SG_ 994 RollingCounter_0x3E2 "Rolling counter";
CM_ SG_ 994 ESC_LateralACC "Indicate lateral acceleration";
CM_ SG_ 994 ESC_LateralACC_Valid "Valid flag of lateral acceleration";
CM_ SG_ 994 ESC_LongitudeACC "Indicate longitude acceleration";
CM_ SG_ 994 ESC_LongitudeACC_Valid "Valid flag of longitude acceleration";
CM_ SG_ 994 ESC_VehDynYawRate "Indicate the yaw rate";
CM_ SG_ 994 ESC_VehDynYawRate_Valid "Valid flag of yaw rate";
CM_ SG_ 894 Checksum_0x37E "Check sum";
CM_ SG_ 894 Rolling_counter_0x37E "Rolling Counter";
CM_ SG_ 894 EPS_SteeringTorque "steering torque bosch(Positive, to left; Negative, to right)";
CM_ SG_ 894 EPS_TorqSensorStatus "Validation bit of torsion bar torque";
CM_ SG_ 894 EPS_EpsFailed "EPS failed bit";
CM_ SG_ 894 EPS_Mode "Electric steering mode";
CM_ SG_ 382 Checksum_0x17E "Check sum";
CM_ SG_ 382 Rolling_counter_0x17E "Rolling Counter";
CM_ SG_ 382 SAS_SteerWheelAngle "The current angle of the steering wheel(Positive, to left; Negative, to right)";
CM_ SG_ 382 SAS_SteeringAngleValid "Effective signal for steering angle";
CM_ SG_ 382 SAS_SASStsSnsr "the flag of  SAS status Punch:Steering angle status";
CM_ SG_ 382 SAS_SteerWhlRotSpd "The current rotation speed of the steering wheel.";
CM_ SG_ 382 SAS_SteerWhlRotSpdStatus "The status of SteerWheel Rotation Speed valid";
CM_ SG_ 382 SAS_Calibrated "SAS calibration state of Steer Angle Sensor";
CM_ SG_ 382 SAS_SASFailure "Angle sensor disabled.";
CM_ SG_ 617 Checksum_0x269 "Check sum";
CM_ SG_ 617 RollingCounter_0x269 "Rolling counter";
CM_ SG_ 617 VCU_VehicleHVStatus "Vehicle High voltage Ready State(VCU_VehicleHVStatus to be received by all modules,Used as a flash programming pre-condition (replacement for engine running)";
CM_ SG_ 617 VCU_ActualGear "actual gear";
CM_ SG_ 617 VCU_ActualGearValid "Indicate the current gear position";
CM_ SG_ 617 VCU_AccPedalPosition "Indicate the acceleraton pedal position";
CM_ SG_ 617 VCU_AccPedalPositionValid "Indicate the acceleration pedal position valid flag";
CM_ SG_ 617 VCU_TqReductionRqstResponse_Rese "Indicate the response for the RBS/TCS request torqueRBS/TCS";
CM_ SG_ 617 VCU_BrakePedalSts "Brake Pedal Sts";
CM_ SG_ 814 CCU_ExternalTemperature "External Temperature";
CM_ SG_ 814 CCU_ExternalTemperatureFailSts "External Temperature Fail Sts";
CM_ SG_ 1087 IPC_Sec "Represents the current second.60 - 63 = Invalid";
CM_ SG_ 1087 IPC_Min "Represents the current minute. 60 - 63 = Invalid";
CM_ SG_ 1087 IPC_Hour "Represents the current hour, 24 - 30 = not used";
CM_ SG_ 1087 IPC_Day "Represents the current dayInvalid value = 0";
CM_ SG_ 1087 IPC_Month "Represents the current month.0, 13 to 15 = Invalid";
CM_ SG_ 1087 IPC_Year "Represents the current year.";
CM_ SG_ 1087 IPC_SelfCheckStatus "Power on self check status";
CM_ SG_ 524 Checksum_0x20C "Checksum";
CM_ SG_ 524 Rolling_Counter_0x20C "Rolling_Counter";
CM_ SG_ 524 IPC_ODO "odograph";
CM_ SG_ 703 IPC_TripA "Set Trip A";
CM_ SG_ 703 IPC_AverageSpeedTripA "Average Speed of TripA";
CM_ SG_ 703 IPC_AverageConsumptionTripA "Average Consumption of TripA";
CM_ SG_ 703 IPC_ParkBrakeSts "Park Brake Status";
CM_ SG_ 703 IPC_VehSpd "Current Displayed Longitudinal Vehicle Speed";
CM_ SG_ 1025 MHU_SET_DoorSpeedLock "Setting Door speed lock mode";
CM_ SG_ 1025 MHU_SET_RemoteDoorUnlock_reserve "Setting which door will be unlocked when car unlock";
CM_ SG_ 1025 MHU_SET_RemoteLockFeedback "Setting remote car lock or unlock feedback mechanism";
CM_ SG_ 1025 MHU_SET_AutoUnlockDoor "Setting auto unlock door mode Park Engine off Manual";
CM_ SG_ 1025 MHU_SET_MirrorAuto_reserved "Change mirror auto mode";
CM_ SG_ 1025 MHU_Anti_theftAlarmSet "Anti theft Alarm Set";
CM_ SG_ 1025 MHU_TriggerReadKey "Trigger BCM to read KeyFOB ID";
CM_ SG_ 1026 MHU_Heatrearglass_Set "Heating command";
CM_ SG_ 1026 MHU_SET_DayTimeRunningLight_rese "On Off Day Time Running Light";
CM_ SG_ 1026 MHU_SET_FollowMeHomeTime "Set the time of Follow Me Home light";
CM_ SG_ 967 MHU_VehsSpd_Warn "MHU  To Configure  OverSpeed Threshold";
CM_ SG_ 967 MHU_SET_Volume "MHU SET IPC volume";
CM_ SG_ 967 MHU_St_DimmingIPC "MHU  Background lump level setting to IPC";
CM_ SG_ 1074 Checksum_0x432 "Checksum";
CM_ SG_ 1074 Rolling_Counter_0x432 "Rolling_Counter";
CM_ SG_ 1074 MHU_FOTA_State "FOTA global status";
CM_ SG_ 1074 MHU_FOTA_Error_Code "FOTA Error Code";
CM_ SG_ 267 TBOX_STAT_TerminalReq "CAR state switching request";
CM_ SG_ 267 TBOX_AuthCode_0x10B "TBOX Message Authentication Code of message 0x10B";
CM_ SG_ 269 MHU_BCM_reqTrunk "MHU Set Trunk Ajar Door or Tailgate";
CM_ SG_ 269 MHU_BCM_RemoteDoorCtrl "MHU set door state remotely.";
CM_ SG_ 269 MHU_APM_ReqWindow "Request control Window from MHU";
CM_ SG_ 269 TBOX_AuthCode_0x10D "TBOX Message Authentication Code of message 0x10D";
CM_ SG_ 271 MHU_SetHighBeam "Set high beam light ON/FF";
CM_ SG_ 271 MHU_SetHornOnOff "Set horn ON/OFF";
CM_ SG_ 271 MHU_SetLowBeam "Set low beam light ON/FF";
CM_ SG_ 271 TBOX_AuthCode_0x10F "TBOX Message Authentication Code of message 0x10F";
CM_ SG_ 852 MHU_BSD_On "BSD On off";
CM_ SG_ 852 MHU_BSD_sens_Reserved "BSD Sensitivity (Early   Normal   Late)";
CM_ SG_ 852 MHU_BSD_AudWarning "Setting Audible warning for BSD On off";
CM_ SG_ 852 MHU_RCTA_On "RCTA On off";
CM_ SG_ 852 MHU_RCTA_sens_Reserved "RCTA Sensitivity (Early   Normal   Late)";
CM_ SG_ 852 MHU_PA_On "PA On off";
CM_ SG_ 852 MHU_DOW_Mode "Door Open Warning Mode select";
CM_ SG_ 852 MHU_DOW_sens_Reserved "DOW Sensitivity (Early   Normal   Late)";
CM_ SG_ 852 MHU_DOW_AudWarning "DOW audit chime On off";
CM_ SG_ 425 VCU_RegenLevel_Feed "VCU current Feedback Set power regenerative level";
CM_ SG_ 425 VCU_RBCSts "Regenerative Braking";
CM_ SG_ 425 VCU_RDCSts "Regenerative coasted";
CM_ SG_ 425 VCU_Veh_ERR "Vehicle System Error";
CM_ SG_ 425 VCU_DrvSys_ERR "DriveSystemError";
CM_ SG_ 425 VCU_PackSys_ERR "StoredEnergySystemError";
CM_ SG_ 425 VCU_TBOX_Veh_STS_Reserved "Vehicle Status";
CM_ SG_ 425 VCU_VehChg_STS "Vehicle Charge Status";
CM_ SG_ 425 VCU_BatterVoltage_Reserved "BetteryVoltage";
CM_ SG_ 425 VCU_BatteryVoltErr_Reserved "Indicate the generator is warning when Mechanical flag or Electrical flag is active (Reserved)（）";
CM_ SG_ 425 VCU_MotorCoolingCircuitErr_Reser "Motor cooling loop failure state (Reserved)";
CM_ SG_ 425 VCU_PackCoolingCircuitErr_Reserv "Battery pack cooling loop failure state (Reserved)";
CM_ SG_ 425 VCU_VehicleHVStatus "Vehicle High voltage Ready State(VCU_VehicleHVStatus to be received by all modules,Used as a flash programming pre-condition (replacement for engine running)";
CM_ SG_ 425 VCU_InstantPowerConsump "Instant power consumption";
CM_ SG_ 425 VCU_AveragePowerConsump "Average power comsumption";
CM_ SG_ 425 VCU_BrakePedalSts "Brake Pedal Sts";
CM_ SG_ 725 VCU_DCDC_Output_REQ "Control DCDC Output AbleEnable";
CM_ SG_ 725 VCU_DCDC_OutVoltage_REQ "DCDC OutputVoltage";
CM_ SG_ 725 VCU_DCDCAllowedPower "DCDCAllowedPower";
CM_ SG_ 905 VCU_FanControl_Sts "Fan Control status";
CM_ SG_ 905 VCU_HVACInletWateTemp "HVAC inlet water temperature";
CM_ SG_ 905 VCU_IMMO_Sts "IMMO staus";
CM_ SG_ 905 VCU_VacuumSts_reserved "Vacuum Pressure status";
CM_ SG_ 905 VCU_VacuumPresWrn "Vacuum Pressure warning";
CM_ SG_ 504 Checksum_0x1F8 "Check sum";
CM_ SG_ 504 Rolling_Counter_0x1F8 "Rolling counter";
CM_ SG_ 504 EDS_output_trq_FR "Actual output torque of current EDS";
CM_ SG_ 504 EDS_output_trqValid_FR "Indicate the valid flag of current motor torque";
CM_ SG_ 504 EDS_Spd_FR "current motor speed";
CM_ SG_ 504 EDS_SpdValid_FR "Indicate the valid flag of current motor speed";
CM_ SG_ 504 EDS_MotorDriveSts_FR "The drive state of EDS";
CM_ SG_ 504 EDS_Work_STS_FR "EDS Work status";
CM_ SG_ 504 EDS_powoff_req_FR "If there is a serious failure in the running process of EDS, the high voltage of VCU will be requested";
CM_ SG_ 533 Checksum_0x215 "Checksum";
CM_ SG_ 533 Rolling_Counter_0x215 "Rolling Counter";
CM_ SG_ 533 BMS_SOE "BMS State Of Enegy";
CM_ SG_ 533 BMS_HWCrash_Sts "Battery Pack Hardware Crash signal Status";
CM_ SG_ 533 BMS_HVIL_STS "The HVIL state of BMS";
CM_ SG_ 533 BMS_IGN_Sts "the ignition signal status (on/off)";
CM_ SG_ 533 BMS_Sys_STS "BMS_Status(Self-test after BMS wake-up)";
CM_ SG_ 533 BMS_HVOnOff_STS "BMS High Voltage Status(BMS_HVOnOff_STS to be received by all modules,Used as a flash programming pre-condition (replacement for engine running)";
CM_ SG_ 533 BMS_Balance_STS "BMS Balance Status";
CM_ SG_ 533 BMS_SocActual_EST "Actual SOC";
CM_ SG_ 533 BMS_BatBalance_ERR "Battery Balance Error indicates Balancing switch is short or open";
CM_ SG_ 533 BMS_ISU_Status "Insulation status";
CM_ SG_ 533 BMS_ERR_LEV "BMS requesting VCU to operate at the limited operating strategy (LOS)";
CM_ SG_ 533 BMS_SOH "BMS State Of Health";
CM_ SG_ 533 BMS_HV_Sts "BMS High Voltage Status";
CM_ SG_ 1281 BCM_sourceID "source ID";
CM_ SG_ 1281 BCM_CBV "CBV";
CM_ SG_ 1281 BCM_Data0 "Data0";
CM_ SG_ 1281 BCM_Data1 "Data1";
CM_ SG_ 1281 BCM_Data2 "Data2";
CM_ SG_ 1281 BCM_Data3 "Data3";
CM_ SG_ 1281 BCM_Data4 "Data4";
CM_ SG_ 1281 BCM_Data5 "Data5";
CM_ SG_ 1288 ACM_sourceID "source ID";
CM_ SG_ 1288 ACM_CBV "CBV";
CM_ SG_ 1288 ACM_Data0 "Data0";
CM_ SG_ 1288 ACM_Data1 "Data1";
CM_ SG_ 1288 ACM_Data2 "Data2";
CM_ SG_ 1288 ACM_Data3 "Data3";
CM_ SG_ 1288 ACM_Data4 "Data4";
CM_ SG_ 1288 ACM_Data5 "Data5";
CM_ SG_ 1344 BSD_sourceID "source ID";
CM_ SG_ 1344 BSD_CBV "CBV";
CM_ SG_ 1344 BSD_Data0 "Data0";
CM_ SG_ 1344 BSD_Data1 "Data1";
CM_ SG_ 1344 BSD_Data2 "Data2";
CM_ SG_ 1344 BSD_Data3 "Data3";
CM_ SG_ 1344 BSD_Data4 "Data4";
CM_ SG_ 1344 BSD_Data5 "Data5";
CM_ SG_ 1282 GW_sourceID "source ID";
CM_ SG_ 1282 GW_CBV "CBV";
CM_ SG_ 1282 GW_Data0 "Data0";
CM_ SG_ 1282 GW_Data1 "Data1";
CM_ SG_ 1282 GW_Data2 "Data2";
CM_ SG_ 1282 GW_Data3 "Data3";
CM_ SG_ 1282 GW_Data4 "Data4";
CM_ SG_ 1282 GW_Data5 "Data5";
CM_ SG_ 1672 ACM_DiagReqData0 "Data0";
CM_ SG_ 1672 ACM_DiagReqData1 "Data1";
CM_ SG_ 1672 ACM_DiagReqData2 "Data2";
CM_ SG_ 1672 ACM_DiagReqData3 "Data3";
CM_ SG_ 1672 ACM_DiagReqData4 "Data4";
CM_ SG_ 1672 ACM_DiagReqData5 "Data5";
CM_ SG_ 1672 ACM_DiagReqData6 "Data6";
CM_ SG_ 1672 ACM_DiagReqData7 "Data7";
CM_ SG_ 1544 ACM_DiagRespData0 "Data0";
CM_ SG_ 1544 ACM_DiagRespData1 "Data1";
CM_ SG_ 1544 ACM_DiagRespData2 "Data2";
CM_ SG_ 1544 ACM_DiagRespData3 "Data3";
CM_ SG_ 1544 ACM_DiagRespData4 "Data4";
CM_ SG_ 1544 ACM_DiagRespData5 "Data5";
CM_ SG_ 1544 ACM_DiagRespData6 "Data6";
CM_ SG_ 1544 ACM_DiagRespData7 "Data7";
CM_ SG_ 1665 BCM_DiagReq_Data0 "Data0";
CM_ SG_ 1665 BCM_DiagReq_Data1 "Data1";
CM_ SG_ 1665 BCM_DiagReq_Data2 "Data2";
CM_ SG_ 1665 BCM_DiagReq_Data3 "Data3";
CM_ SG_ 1665 BCM_DiagReq_Data4 "Data4";
CM_ SG_ 1665 BCM_DiagReq_Data5 "Data5";
CM_ SG_ 1665 BCM_DiagReq_Data6 "Data6";
CM_ SG_ 1665 BCM_DiagReq_Data7 "Data7";
CM_ SG_ 1537 BCM_DiagResp_Data0 "Data0";
CM_ SG_ 1537 BCM_DiagResp_Data1 "Data1";
CM_ SG_ 1537 BCM_DiagResp_Data2 "Data2";
CM_ SG_ 1537 BCM_DiagResp_Data3 "Data3";
CM_ SG_ 1537 BCM_DiagResp_Data4 "Data4";
CM_ SG_ 1537 BCM_DiagResp_Data5 "Data5";
CM_ SG_ 1537 BCM_DiagResp_Data6 "Data6";
CM_ SG_ 1537 BCM_DiagResp_Data7 "Data7";
CM_ SG_ 1728 BSD_DiagReq_Data0 "Data0";
CM_ SG_ 1728 BSD_DiagReq_Data1 "Data1";
CM_ SG_ 1728 BSD_DiagReq_Data2 "Data2";
CM_ SG_ 1728 BSD_DiagReq_Data3 "Data3";
CM_ SG_ 1728 BSD_DiagReq_Data4 "Data4";
CM_ SG_ 1728 BSD_DiagReq_Data5 "Data5";
CM_ SG_ 1728 BSD_DiagReq_Data6 "Data6";
CM_ SG_ 1728 BSD_DiagReq_Data7 "Data7";
CM_ SG_ 1600 BSD_DiagResp_Data0 "Data0";
CM_ SG_ 1600 BSD_DiagResp_Data1 "Data1";
CM_ SG_ 1600 BSD_DiagResp_Data2 "Data2";
CM_ SG_ 1600 BSD_DiagResp_Data3 "Data3";
CM_ SG_ 1600 BSD_DiagResp_Data4 "Data4";
CM_ SG_ 1600 BSD_DiagResp_Data5 "Data5";
CM_ SG_ 1600 BSD_DiagResp_Data6 "Data6";
CM_ SG_ 1600 BSD_DiagResp_Data7 "Data7";
CM_ SG_ 1791 GW_DiagFunctionalAddressingData0 "Data0";
CM_ SG_ 1791 GW_DiagFunctionalAddressingData1 "Data1";
CM_ SG_ 1791 GW_DiagFunctionalAddressingData2 "Data2";
CM_ SG_ 1791 GW_DiagFunctionalAddressingData3 "Data3";
CM_ SG_ 1791 GW_DiagFunctionalAddressingData4 "Data4";
CM_ SG_ 1791 GW_DiagFunctionalAddressingData5 "Data5";
CM_ SG_ 1791 GW_DiagFunctionalAddressingData6 "Data6";
CM_ SG_ 1791 GW_DiagFunctionalAddressingData7 "Data7";
BA_DEF_ BO_  "DiagRequest" ENUM  "No","Yes";
BA_DEF_ BO_  "DiagResponse" ENUM  "No","Yes";
BA_DEF_ BO_  "DiagState" ENUM  "No","Yes";
BA_DEF_ BO_  "GenMsgCycleTime" INT 0 65535;
BA_DEF_ BO_  "GenMsgCycleTimeFast" INT 0 65535;
BA_DEF_ BO_  "GenMsgDelayTime" INT 0 65535;
BA_DEF_ BO_  "GenMsgILSupport" ENUM  "No","Yes";
BA_DEF_ BO_  "GenMsgNrOfRepetition" INT 0 65535;
BA_DEF_ BO_  "GenMsgSendType" ENUM  "Cycle","Event","IfActive","CE","CA";
BA_DEF_ BO_  "NmAsrMessage" ENUM  "No","Yes";
BA_DEF_ BO_  "NmMessage" ENUM  "No","Yes";
BA_DEF_ SG_  "GenSigSendType" ENUM  "Cycle","OnWrite","OnWriteWithRepetition","OnChange","OnChangeWithRepetition","IfActive","IfActiveWithRepetition";
BA_DEF_ SG_  "GenSigStartValue" INT 0 2147483647;
BA_DEF_ SG_  "GenSigInvalidValue" INT 0 2147483647;
BA_DEF_ SG_  "GenSigInactiveValue" INT 0 2147483647;
BA_DEF_ BU_  "ILUsed" ENUM  "No","Yes";
BA_DEF_ BU_  "NmAsrCanMsgReducedTime" INT 320 640;
BA_DEF_ BU_  "NmAsrNode" ENUM  "No","Yes";
BA_DEF_  "Baudrate" INT 0 1000000;
BA_DEF_  "BusType" STRING ;
BA_DEF_  "Manufacturer" STRING ;
BA_DEF_  "NmAsrBaseAddress" HEX 0 2047;
BA_DEF_  "NmAsrCanMsgCycleTime" INT 0 65535;
BA_DEF_  "NmAsrMessageCount" INT 1 256;
BA_DEF_  "NmAsrRepeatMessageTime" INT 0 65535;
BA_DEF_  "NmAsrTimeoutTime" INT 0 65535;
BA_DEF_  "NmAsrWaitBusSleepTime" INT 0 65535;
BA_DEF_  "NmType" STRING ;
BA_DEF_ SG_  "SystemSignalLongSymbol" STRING ;
BA_DEF_ BO_  "SystemMessageLongSymbol" STRING ;
BA_DEF_DEF_  "DiagRequest" "No";
BA_DEF_DEF_  "DiagResponse" "No";
BA_DEF_DEF_  "DiagState" "No";
BA_DEF_DEF_  "GenMsgCycleTime" 0;
BA_DEF_DEF_  "GenMsgCycleTimeFast" 0;
BA_DEF_DEF_  "GenMsgDelayTime" 0;
BA_DEF_DEF_  "GenMsgILSupport" "Yes";
BA_DEF_DEF_  "GenMsgNrOfRepetition" 0;
BA_DEF_DEF_  "GenMsgSendType" "";
BA_DEF_DEF_  "NmAsrMessage" "No";
BA_DEF_DEF_  "NmMessage" "No";
BA_DEF_DEF_  "GenSigSendType" "";
BA_DEF_DEF_  "GenSigStartValue" 0;
BA_DEF_DEF_  "GenSigInvalidValue" 0;
BA_DEF_DEF_  "GenSigInactiveValue" 0;
BA_DEF_DEF_  "ILUsed" "Yes";
BA_DEF_DEF_  "NmAsrCanMsgReducedTime" 320;
BA_DEF_DEF_  "NmAsrNode" "No";
BA_DEF_DEF_  "Baudrate" 500000;
BA_DEF_DEF_  "BusType" "CAN";
BA_DEF_DEF_  "Manufacturer" "Launch";
BA_DEF_DEF_  "NmAsrBaseAddress" 1280;
BA_DEF_DEF_  "NmAsrCanMsgCycleTime" 640;
BA_DEF_DEF_  "NmAsrMessageCount" 128;
BA_DEF_DEF_  "NmAsrRepeatMessageTime" 3200;
BA_DEF_DEF_  "NmAsrTimeoutTime" 2000;
BA_DEF_DEF_  "NmAsrWaitBusSleepTime" 1500;
BA_DEF_DEF_  "NmType" "NmAsr";
BA_DEF_DEF_  "SystemSignalLongSymbol" "";
BA_DEF_DEF_  "SystemMessageLongSymbol" "";
BA_ "NmAsrNode" BU_ GW 1;
BA_ "NmAsrNode" BU_ BCM 1;
BA_ "NmAsrNode" BU_ ACM 1;
BA_ "NmAsrNode" BU_ BSD 1;
BA_ "GenMsgCycleTime" BO_ 133 20;
BA_ "GenMsgSendType" BO_ 133 0;
BA_ "GenMsgCycleTime" BO_ 897 200;
BA_ "GenMsgSendType" BO_ 897 0;
BA_ "GenMsgCycleTime" BO_ 1160 1000;
BA_ "GenMsgSendType" BO_ 1160 0;
BA_ "GenMsgCycleTime" BO_ 1053 100;
BA_ "GenMsgCycleTimeFast" BO_ 1053 20;
BA_ "GenMsgNrOfRepetition" BO_ 1053 5;
BA_ "GenMsgSendType" BO_ 1053 3;
BA_ "GenMsgCycleTime" BO_ 303 100;
BA_ "GenMsgSendType" BO_ 303 0;
BA_ "GenMsgCycleTime" BO_ 259 200;
BA_ "GenMsgSendType" BO_ 259 0;
BA_ "GenMsgCycleTime" BO_ 261 100;
BA_ "GenMsgSendType" BO_ 261 0;
BA_ "GenMsgCycleTime" BO_ 262 20;
BA_ "GenMsgSendType" BO_ 262 0;
BA_ "GenMsgCycleTime" BO_ 263 20;
BA_ "GenMsgSendType" BO_ 263 0;
BA_ "GenMsgCycleTime" BO_ 265 30;
BA_ "GenMsgSendType" BO_ 265 0;
BA_ "GenMsgCycleTime" BO_ 266 100;
BA_ "GenMsgSendType" BO_ 266 0;
BA_ "GenMsgCycleTime" BO_ 270 100;
BA_ "GenMsgSendType" BO_ 270 0;
BA_ "GenMsgCycleTime" BO_ 283 20;
BA_ "GenMsgSendType" BO_ 283 0;
BA_ "GenMsgCycleTime" BO_ 274 100;
BA_ "GenMsgSendType" BO_ 274 0;
BA_ "GenMsgCycleTime" BO_ 529 20;
BA_ "GenMsgSendType" BO_ 529 0;
BA_ "GenMsgCycleTime" BO_ 525 100;
BA_ "GenMsgSendType" BO_ 525 0;
BA_ "GenMsgCycleTime" BO_ 268 100;
BA_ "GenMsgSendType" BO_ 268 0;
BA_ "GenMsgCycleTime" BO_ 272 100;
BA_ "GenMsgSendType" BO_ 272 0;
BA_ "GenMsgCycleTime" BO_ 769 200;
BA_ "GenMsgSendType" BO_ 769 0;
BA_ "GenMsgCycleTime" BO_ 770 200;
BA_ "GenMsgSendType" BO_ 770 0;
BA_ "GenMsgSendType" BO_ 923 1;
BA_ "GenMsgSendType" BO_ 922 1;
BA_ "GenMsgSendType" BO_ 920 1;
BA_ "GenMsgSendType" BO_ 921 1;
BA_ "GenMsgCycleTime" BO_ 296 50;
BA_ "GenMsgSendType" BO_ 296 0;
BA_ "GenMsgCycleTime" BO_ 307 50;
BA_ "GenMsgSendType" BO_ 307 0;
BA_ "GenMsgCycleTime" BO_ 850 50;
BA_ "GenMsgSendType" BO_ 850 0;
BA_ "GenMsgCycleTime" BO_ 1216 1000;
BA_ "GenMsgSendType" BO_ 1216 0;
BA_ "GenMsgCycleTime" BO_ 851 50;
BA_ "GenMsgSendType" BO_ 851 0;
BA_ "GenMsgCycleTime" BO_ 834 10;
BA_ "GenMsgSendType" BO_ 834 0;
BA_ "GenMsgCycleTime" BO_ 322 20;
BA_ "GenMsgSendType" BO_ 322 0;
BA_ "GenMsgCycleTime" BO_ 306 20;
BA_ "GenMsgSendType" BO_ 306 0;
BA_ "GenMsgCycleTime" BO_ 994 20;
BA_ "GenMsgSendType" BO_ 994 0;
BA_ "GenMsgCycleTime" BO_ 894 20;
BA_ "GenMsgSendType" BO_ 894 0;
BA_ "GenMsgCycleTime" BO_ 382 10;
BA_ "GenMsgSendType" BO_ 382 0;
BA_ "GenMsgCycleTime" BO_ 617 20;
BA_ "GenMsgSendType" BO_ 617 0;
BA_ "GenMsgCycleTime" BO_ 814 50;
BA_ "GenMsgSendType" BO_ 814 0;
BA_ "GenMsgCycleTime" BO_ 1087 1000;
BA_ "GenMsgSendType" BO_ 1087 0;
BA_ "GenMsgCycleTime" BO_ 524 100;
BA_ "GenMsgSendType" BO_ 524 0;
BA_ "GenMsgCycleTime" BO_ 703 50;
BA_ "GenMsgSendType" BO_ 703 0;
BA_ "GenMsgCycleTimeFast" BO_ 1025 50;
BA_ "GenMsgNrOfRepetition" BO_ 1025 5;
BA_ "GenMsgSendType" BO_ 1025 1;
BA_ "GenMsgCycleTimeFast" BO_ 1026 50;
BA_ "GenMsgNrOfRepetition" BO_ 1026 5;
BA_ "GenMsgSendType" BO_ 1026 1;
BA_ "GenMsgCycleTime" BO_ 967 100;
BA_ "GenMsgCycleTimeFast" BO_ 967 50;
BA_ "GenMsgDelayTime" BO_ 967 30;
BA_ "GenMsgNrOfRepetition" BO_ 967 5;
BA_ "GenMsgSendType" BO_ 967 0;
BA_ "GenMsgCycleTime" BO_ 1074 100;
BA_ "GenMsgDelayTime" BO_ 1074 50;
BA_ "GenMsgSendType" BO_ 1074 0;
BA_ "GenMsgCycleTimeFast" BO_ 267 20;
BA_ "GenMsgNrOfRepetition" BO_ 267 5;
BA_ "GenMsgSendType" BO_ 267 1;
BA_ "GenMsgCycleTimeFast" BO_ 269 20;
BA_ "GenMsgNrOfRepetition" BO_ 269 5;
BA_ "GenMsgSendType" BO_ 269 1;
BA_ "GenMsgCycleTimeFast" BO_ 271 20;
BA_ "GenMsgNrOfRepetition" BO_ 271 5;
BA_ "GenMsgSendType" BO_ 271 1;
BA_ "SystemMessageLongSymbol" BO_ 271 "GW_MHU_BCM_HornLightControl_0x10F";
BA_ "GenMsgSendType" BO_ 852 1;
BA_ "GenMsgCycleTime" BO_ 425 20;
BA_ "GenMsgSendType" BO_ 425 0;
BA_ "GenMsgCycleTime" BO_ 725 50;
BA_ "GenMsgSendType" BO_ 725 0;
BA_ "GenMsgCycleTime" BO_ 905 50;
BA_ "GenMsgSendType" BO_ 905 0;
BA_ "GenMsgCycleTime" BO_ 504 10;
BA_ "GenMsgSendType" BO_ 504 0;
BA_ "GenMsgCycleTime" BO_ 533 50;
BA_ "GenMsgSendType" BO_ 533 0;
BA_ "NmMessage" BO_ 1281 1;
BA_ "NmAsrMessage" BO_ 1281 1;
BA_ "GenMsgCycleTime" BO_ 1281 640;
BA_ "GenMsgSendType" BO_ 1281 2;
BA_ "NmMessage" BO_ 1288 1;
BA_ "NmAsrMessage" BO_ 1288 1;
BA_ "GenMsgCycleTime" BO_ 1288 640;
BA_ "GenMsgSendType" BO_ 1288 2;
BA_ "NmMessage" BO_ 1344 1;
BA_ "NmAsrMessage" BO_ 1344 1;
BA_ "GenMsgCycleTime" BO_ 1344 640;
BA_ "GenMsgSendType" BO_ 1344 2;
BA_ "NmMessage" BO_ 1282 1;
BA_ "NmAsrMessage" BO_ 1282 1;
BA_ "GenMsgCycleTime" BO_ 1282 640;
BA_ "GenMsgSendType" BO_ 1282 2;
BA_ "DiagRequest" BO_ 1672 1;
BA_ "GenMsgSendType" BO_ 1672 1;
BA_ "DiagResponse" BO_ 1544 1;
BA_ "GenMsgSendType" BO_ 1544 1;
BA_ "DiagRequest" BO_ 1665 1;
BA_ "GenMsgSendType" BO_ 1665 1;
BA_ "DiagResponse" BO_ 1537 1;
BA_ "GenMsgSendType" BO_ 1537 1;
BA_ "DiagRequest" BO_ 1728 1;
BA_ "GenMsgSendType" BO_ 1728 1;
BA_ "DiagResponse" BO_ 1600 1;
BA_ "GenMsgSendType" BO_ 1600 1;
BA_ "DiagState" BO_ 1791 1;
BA_ "GenMsgSendType" BO_ 1791 1;
BA_ "GenSigSendType" SG_ 133 Checksum_0x85 0;
BA_ "GenSigInvalidValue" SG_ 133 Rolling_Counter_0x85 15;
BA_ "GenSigSendType" SG_ 133 Rolling_Counter_0x85 0;
BA_ "GenSigInvalidValue" SG_ 133 ACM_Crash_Sts 3;
BA_ "GenSigSendType" SG_ 133 ACM_Crash_Sts 0;
BA_ "GenSigInvalidValue" SG_ 133 ACM_Airbag_Deployment_Status 3;
BA_ "GenSigSendType" SG_ 133 ACM_Airbag_Deployment_Status 0;
BA_ "GenSigInvalidValue" SG_ 133 ACM_Crash_Intensity 7;
BA_ "GenSigSendType" SG_ 133 ACM_Crash_Intensity 0;
BA_ "GenSigInvalidValue" SG_ 133 ACM_Front_Crash 3;
BA_ "GenSigSendType" SG_ 133 ACM_Front_Crash 0;
BA_ "GenSigInvalidValue" SG_ 133 ACM_DriverSide_Crash 3;
BA_ "GenSigSendType" SG_ 133 ACM_DriverSide_Crash 0;
BA_ "GenSigInvalidValue" SG_ 133 ACM_PassSide_Crash 3;
BA_ "GenSigSendType" SG_ 133 ACM_PassSide_Crash 0;
BA_ "GenSigInvalidValue" SG_ 133 ACM_Rear_Crash 3;
BA_ "GenSigSendType" SG_ 133 ACM_Rear_Crash 0;
BA_ "GenSigInvalidValue" SG_ 133 ACM_Rollover_Crash 3;
BA_ "GenSigSendType" SG_ 133 ACM_Rollover_Crash 0;
BA_ "GenSigSendType" SG_ 897 Checksum_0x381 0;
BA_ "GenSigInvalidValue" SG_ 897 Rolling_Counter_0x381 15;
BA_ "GenSigSendType" SG_ 897 Rolling_Counter_0x381 0;
BA_ "GenSigStartValue" SG_ 897 ACM_Seat_Occupancy_Passenger 2;
BA_ "GenSigSendType" SG_ 897 ACM_Seat_Occupancy_Passenger 0;
BA_ "GenSigStartValue" SG_ 897 ACM_Seat_Occupancy_2nd_Row_Dri_r 2;
BA_ "GenSigSendType" SG_ 897 ACM_Seat_Occupancy_2nd_Row_Dri_r 0;
BA_ "SystemSignalLongSymbol" SG_ 897 ACM_Seat_Occupancy_2nd_Row_Dri_r "ACM_Seat_Occupancy_2nd_Row_Dri_reserved";
BA_ "GenSigStartValue" SG_ 897 ACM_Seat_Occupancy_2nd_Row_Pas_r 2;
BA_ "GenSigSendType" SG_ 897 ACM_Seat_Occupancy_2nd_Row_Pas_r 0;
BA_ "SystemSignalLongSymbol" SG_ 897 ACM_Seat_Occupancy_2nd_Row_Pas_r "ACM_Seat_Occupancy_2nd_Row_Pas_reserved";
BA_ "GenSigStartValue" SG_ 897 ACM_Seat_Occupancy_2nd_Row_Mid_r 2;
BA_ "GenSigSendType" SG_ 897 ACM_Seat_Occupancy_2nd_Row_Mid_r 0;
BA_ "SystemSignalLongSymbol" SG_ 897 ACM_Seat_Occupancy_2nd_Row_Mid_r "ACM_Seat_Occupancy_2nd_Row_Mid_reserved";
BA_ "GenSigSendType" SG_ 897 ACM_Seat_Belt_Status_Passenger 0;
BA_ "GenSigSendType" SG_ 897 ACM_Seat_Belt_Status_Driver 0;
BA_ "GenSigSendType" SG_ 897 ACM_Seat_Belt_Status_2nd_Row_Dri 0;
BA_ "SystemSignalLongSymbol" SG_ 897 ACM_Seat_Belt_Status_2nd_Row_Dri "ACM_Seat_Belt_Status_2nd_Row_Dri_reserved";
BA_ "GenSigSendType" SG_ 897 ACM_Seat_Belt_Status_2nd_Row_Mid 0;
BA_ "SystemSignalLongSymbol" SG_ 897 ACM_Seat_Belt_Status_2nd_Row_Mid "ACM_Seat_Belt_Status_2nd_Row_Mid_reserved";
BA_ "GenSigSendType" SG_ 897 ACM_Seat_Belt_Status_2nd_Row_Pas 0;
BA_ "SystemSignalLongSymbol" SG_ 897 ACM_Seat_Belt_Status_2nd_Row_Pas "ACM_Seat_Belt_Status_2nd_Row_Pas_reserved";
BA_ "GenSigStartValue" SG_ 897 ACM_Seat_Belt_Status_3rd_Row_Dri 2;
BA_ "GenSigSendType" SG_ 897 ACM_Seat_Belt_Status_3rd_Row_Dri 0;
BA_ "SystemSignalLongSymbol" SG_ 897 ACM_Seat_Belt_Status_3rd_Row_Dri "ACM_Seat_Belt_Status_3rd_Row_Dri_reserved";
BA_ "GenSigStartValue" SG_ 897 ACM_Seat_Belt_Status_3rd_Row_Pas 2;
BA_ "GenSigSendType" SG_ 897 ACM_Seat_Belt_Status_3rd_Row_Pas 0;
BA_ "SystemSignalLongSymbol" SG_ 897 ACM_Seat_Belt_Status_3rd_Row_Pas "ACM_Seat_Belt_Status_3rd_Row_Pas_reserved";
BA_ "GenSigSendType" SG_ 1160 Checksum_0x488 0;
BA_ "GenSigInvalidValue" SG_ 1160 Rolling_Counter_0x488 15;
BA_ "GenSigSendType" SG_ 1160 Rolling_Counter_0x488 0;
BA_ "GenSigStartValue" SG_ 1160 ACM_Malfunction 1;
BA_ "GenSigSendType" SG_ 1160 ACM_Malfunction 0;
BA_ "GenSigSendType" SG_ 1160 ACM_Pre_Drive_Check 0;
BA_ "GenSigStartValue" SG_ 1160 ACM_in_Plant_Mode 1;
BA_ "GenSigSendType" SG_ 1160 ACM_in_Plant_Mode 0;
BA_ "GenSigSendType" SG_ 1160 ACM_PAB_Suppression 0;
BA_ "GenSigSendType" SG_ 1160 ACM_Airbag_Disabled 0;
BA_ "GenSigSendType" SG_ 1160 ACM_Development_Calibration 0;
BA_ "GenSigStartValue" SG_ 1160 ACM_In_Disposal_Mode 1;
BA_ "GenSigSendType" SG_ 1160 ACM_In_Disposal_Mode 0;
BA_ "GenSigStartValue" SG_ 1160 ACM_Seatbelt_Reminder_Request 1;
BA_ "GenSigSendType" SG_ 1160 ACM_Seatbelt_Reminder_Request 0;
BA_ "GenSigStartValue" SG_ 1160 ACM_SBR_Chime_Req 1;
BA_ "GenSigSendType" SG_ 1160 ACM_SBR_Chime_Req 0;
BA_ "GenSigStartValue" SG_ 1160 ACM_SBR_Blinking_Req 1;
BA_ "GenSigSendType" SG_ 1160 ACM_SBR_Blinking_Req 0;
BA_ "GenSigStartValue" SG_ 1053 BCM_STAT_RemoteLockFeedback 1;
BA_ "GenSigInvalidValue" SG_ 1053 BCM_STAT_RemoteLockFeedback 7;
BA_ "GenSigSendType" SG_ 1053 BCM_STAT_RemoteLockFeedback 2;
BA_ "GenSigStartValue" SG_ 1053 BCM_STAT_RemoteDoorUnlock_reserv 3;
BA_ "GenSigSendType" SG_ 1053 BCM_STAT_RemoteDoorUnlock_reserv 2;
BA_ "SystemSignalLongSymbol" SG_ 1053 BCM_STAT_RemoteDoorUnlock_reserv "BCM_STAT_RemoteDoorUnlock_reserved";
BA_ "GenSigStartValue" SG_ 1053 BCM_STAT_AutoDoorUnlock 1;
BA_ "GenSigInvalidValue" SG_ 1053 BCM_STAT_AutoDoorUnlock 3;
BA_ "GenSigSendType" SG_ 1053 BCM_STAT_AutoDoorUnlock 2;
BA_ "GenSigStartValue" SG_ 1053 BCM_STAT_DoorSpeedLock 1;
BA_ "GenSigInvalidValue" SG_ 1053 BCM_STAT_DoorSpeedLock 7;
BA_ "GenSigSendType" SG_ 1053 BCM_STAT_DoorSpeedLock 2;
BA_ "GenSigStartValue" SG_ 1053 BCM_STAT_DayTimeRunningLight_res 1;
BA_ "GenSigInvalidValue" SG_ 1053 BCM_STAT_DayTimeRunningLight_res 3;
BA_ "GenSigSendType" SG_ 1053 BCM_STAT_DayTimeRunningLight_res 2;
BA_ "SystemSignalLongSymbol" SG_ 1053 BCM_STAT_DayTimeRunningLight_res "BCM_STAT_DayTimeRunningLight_reserved";
BA_ "GenSigStartValue" SG_ 1053 BCM_STAT_AntiTheftMode 3;
BA_ "GenSigInvalidValue" SG_ 1053 BCM_STAT_AntiTheftMode 7;
BA_ "GenSigSendType" SG_ 1053 BCM_STAT_AntiTheftMode 2;
BA_ "GenSigSendType" SG_ 1053 BCM_FOBID_userprofile_link 2;
BA_ "GenSigInvalidValue" SG_ 1053 BCM_feedback_FollowMeHomeTime 7;
BA_ "GenSigSendType" SG_ 1053 BCM_feedback_FollowMeHomeTime 2;
BA_ "GenSigSendType" SG_ 303 Checksum_0x12f 0;
BA_ "GenSigInvalidValue" SG_ 303 Rolling_Counter_0x12f 15;
BA_ "GenSigSendType" SG_ 303 Rolling_Counter_0x12f 0;
BA_ "GenSigSendType" SG_ 303 ST_KL_KEY_VLD 0;
BA_ "GenSigSendType" SG_ 303 ST_SSP 0;
BA_ "GenSigInvalidValue" SG_ 303 BCM_IMMO_Sts 2;
BA_ "GenSigSendType" SG_ 303 BCM_IMMO_Sts 0;
BA_ "GenSigSendType" SG_ 259 Q_Discharge 0;
BA_ "GenSigSendType" SG_ 259 Q_Charge 0;
BA_ "GenSigSendType" SG_ 259 RQ_DCDC_U 0;
BA_ "GenSigSendType" SG_ 259 REQ_ConsumerControlAudioVolumeCo 0;
BA_ "GenSigSendType" SG_ 259 REQ_CCU_PTC_Limitation 0;
BA_ "GenSigSendType" SG_ 261 Checksum_0x105 0;
BA_ "GenSigInvalidValue" SG_ 261 Rolling_Counter_0x105 15;
BA_ "GenSigSendType" SG_ 261 Rolling_Counter_0x105 0;
BA_ "GenSigSendType" SG_ 261 BCM_STAT_TrunkAjar 0;
BA_ "GenSigSendType" SG_ 261 BCM_STAT_DoorAjarDriver 0;
BA_ "GenSigSendType" SG_ 261 BCM_STAT_DoorAjarPassenger 0;
BA_ "GenSigSendType" SG_ 261 BCM_STAT_DoorAjarRL 0;
BA_ "GenSigSendType" SG_ 261 BCM_STAT_DoorAjarRR 0;
BA_ "GenSigSendType" SG_ 261 BCM_STAT_BonnetAjar 0;
BA_ "GenSigSendType" SG_ 262 Checksum_0x106 0;
BA_ "GenSigInvalidValue" SG_ 262 Rolling_Counter_0x106 15;
BA_ "GenSigSendType" SG_ 262 Rolling_Counter_0x106 0;
BA_ "GenSigSendType" SG_ 262 BCM_HighBeamSts 0;
BA_ "GenSigSendType" SG_ 262 BCM_LowBeamSts 0;
BA_ "GenSigSendType" SG_ 262 BCM_PosLmpSts 0;
BA_ "GenSigSendType" SG_ 262 BCM_TurnIndicatorSts 0;
BA_ "GenSigSendType" SG_ 262 BCM_DayRunningLampSts_reserved 0;
BA_ "GenSigSendType" SG_ 262 BCM_ReverseLightSts 0;
BA_ "GenSigSendType" SG_ 262 BCM_StopLightSts 0;
BA_ "GenSigSendType" SG_ 262 BCM_Fr_Dimming_dome_lampSts 0;
BA_ "GenSigSendType" SG_ 262 BCM_Heated_rearglass 0;
BA_ "GenSigSendType" SG_ 262 BCM_BsdLightSts 0;
BA_ "GenSigStartValue" SG_ 262 BCM_STAT_LightActivation 7;
BA_ "GenSigSendType" SG_ 262 BCM_STAT_LightActivation 0;
BA_ "GenSigStartValue" SG_ 262 BCM_STAT_InteriorLight 3;
BA_ "GenSigSendType" SG_ 262 BCM_STAT_InteriorLight 0;
BA_ "GenSigSendType" SG_ 263 Checksum_0x107 0;
BA_ "GenSigInvalidValue" SG_ 263 Rolling_Counter_0x107 15;
BA_ "GenSigSendType" SG_ 263 Rolling_Counter_0x107 0;
BA_ "GenSigSendType" SG_ 263 STAT_ATWS 0;
BA_ "GenSigSendType" SG_ 263 STAT_DoorLockDriver 0;
BA_ "GenSigSendType" SG_ 265 Checksum_0x109 0;
BA_ "GenSigInvalidValue" SG_ 265 Rolling_Counter_0x109 15;
BA_ "GenSigSendType" SG_ 265 Rolling_Counter_0x109 0;
BA_ "GenSigSendType" SG_ 265 BCM_STAT_HazardWarn 0;
BA_ "GenSigSendType" SG_ 265 BCM_STAT_Horn_Reserved 0;
BA_ "GenSigStartValue" SG_ 265 BCM_STAT_WiperStalkSW 7;
BA_ "GenSigInvalidValue" SG_ 265 BCM_STAT_WiperStalkSW 7;
BA_ "GenSigSendType" SG_ 265 BCM_STAT_WiperStalkSW 0;
BA_ "GenSigStartValue" SG_ 265 BCM_STAT_WiperStalkSW2 7;
BA_ "GenSigInvalidValue" SG_ 265 BCM_STAT_WiperStalkSW2 7;
BA_ "GenSigSendType" SG_ 265 BCM_STAT_WiperStalkSW2 0;
BA_ "GenSigSendType" SG_ 265 BCM_LigntSensor 0;
BA_ "GenSigStartValue" SG_ 265 BCM_STAT_lampStalkSW1 7;
BA_ "GenSigInvalidValue" SG_ 265 BCM_STAT_lampStalkSW1 7;
BA_ "GenSigSendType" SG_ 265 BCM_STAT_lampStalkSW1 0;
BA_ "GenSigStartValue" SG_ 265 BCM_STAT_lampStalkSW2 3;
BA_ "GenSigInvalidValue" SG_ 265 BCM_STAT_lampStalkSW2 3;
BA_ "GenSigSendType" SG_ 265 BCM_STAT_lampStalkSW2 0;
BA_ "GenSigSendType" SG_ 266 Checksum_0x10a 0;
BA_ "GenSigInvalidValue" SG_ 266 Rolling_Counter_0x10a 15;
BA_ "GenSigSendType" SG_ 266 Rolling_Counter_0x10a 0;
BA_ "GenSigSendType" SG_ 266 BCM_LVTop_up 0;
BA_ "GenSigStartValue" SG_ 266 Ubatt_Reserved 9000;
BA_ "GenSigInvalidValue" SG_ 266 Ubatt_Reserved 16383;
BA_ "GenSigSendType" SG_ 266 Ubatt_Reserved 0;
BA_ "GenSigSendType" SG_ 270 RemoteAccessKey 0;
BA_ "GenSigSendType" SG_ 270 PassiveAccessTrunk 0;
BA_ "GenSigSendType" SG_ 270 BCM_CurrentValid_FOB 0;
BA_ "GenSigSendType" SG_ 283 BCM_ACCRelayOutputSts 0;
BA_ "GenSigSendType" SG_ 283 BCM_IGN1RelayOutputSts 0;
BA_ "GenSigSendType" SG_ 283 BCM_ACCRelayFalutSts 0;
BA_ "GenSigSendType" SG_ 283 BCM_IGN1RelayFalutSts 0;
BA_ "GenSigSendType" SG_ 283 BCM_KEY_MatchSts 0;
BA_ "GenSigSendType" SG_ 274 Checksum_0x112 0;
BA_ "GenSigInvalidValue" SG_ 274 Rolling_Counter_0x112 15;
BA_ "GenSigSendType" SG_ 274 Rolling_Counter_0x112 0;
BA_ "GenSigSendType" SG_ 274 STAT_Terminal 0;
BA_ "GenSigStartValue" SG_ 274 STAT_CL30s_L_Reserved 3;
BA_ "GenSigSendType" SG_ 274 STAT_CL30s_L_Reserved 0;
BA_ "GenSigSendType" SG_ 529 PEPS_Lock_IGNNotOff_Alert 0;
BA_ "GenSigSendType" SG_ 529 PEPS_CID_NotInside_Alert 0;
BA_ "GenSigSendType" SG_ 529 PEPS_CID_Left_Alert 0;
BA_ "GenSigSendType" SG_ 529 PEPS_RMKey_BatteryLow_Alert 0;
BA_ "GenSigSendType" SG_ 529 PEPS_PressBrakePedal_Alert 0;
BA_ "GenSigSendType" SG_ 529 PEPS_Shift_Position_Alert 0;
BA_ "GenSigSendType" SG_ 529 PEPS_Lock_KeyInside_Alert 0;
BA_ "GenSigInvalidValue" SG_ 529 PEPS_EmergencyStop_Reserved 3;
BA_ "GenSigSendType" SG_ 529 PEPS_EmergencyStop_Reserved 0;
BA_ "GenSigSendType" SG_ 529 PEPS_CID_NotIndenfied_Alert 0;
BA_ "GenSigSendType" SG_ 529 BCM_Positionlight_reminder 0;
BA_ "GenSigSendType" SG_ 525 Checksum_0x20D 0;
BA_ "GenSigInvalidValue" SG_ 525 Rolling_Counter_0x20D 15;
BA_ "GenSigSendType" SG_ 525 Rolling_Counter_0x20D 0;
BA_ "GenSigInvalidValue" SG_ 525 BCM_ODO 1048575;
BA_ "GenSigSendType" SG_ 525 BCM_ODO 0;
BA_ "GenSigSendType" SG_ 268 Checksum_0x10C 0;
BA_ "GenSigInvalidValue" SG_ 268 Rolling_Counter_0x10C 15;
BA_ "GenSigSendType" SG_ 268 Rolling_Counter_0x10C 0;
BA_ "GenSigInvalidValue" SG_ 268 BCM_TboxAuthStatus 3;
BA_ "GenSigSendType" SG_ 268 BCM_TboxAuthStatus 0;
BA_ "GenSigSendType" SG_ 268 BCM_RandomNum32bit 0;
BA_ "GenSigSendType" SG_ 272 Checksum_0x110 0;
BA_ "GenSigInvalidValue" SG_ 272 Rolling_Counter_0x110 15;
BA_ "GenSigSendType" SG_ 272 Rolling_Counter_0x110 0;
BA_ "GenSigInvalidValue" SG_ 272 BCM_APM_FLWIN_Postion 7;
BA_ "GenSigSendType" SG_ 272 BCM_APM_FLWIN_Postion 0;
BA_ "GenSigInvalidValue" SG_ 272 BCM_APM_FRWIN_Postion 7;
BA_ "GenSigSendType" SG_ 272 BCM_APM_FRWIN_Postion 0;
BA_ "GenSigInvalidValue" SG_ 272 BCM_APM_RLWIN_Postion 7;
BA_ "GenSigSendType" SG_ 272 BCM_APM_RLWIN_Postion 0;
BA_ "GenSigInvalidValue" SG_ 272 BCM_APM_RRWIN_Postion 7;
BA_ "GenSigSendType" SG_ 272 BCM_APM_RRWIN_Postion 0;
BA_ "GenSigSendType" SG_ 272 APM_Status 0;
BA_ "GenSigSendType" SG_ 272 ChildProtectionStatus 0;
BA_ "GenSigInvalidValue" SG_ 272 APM_Window_DriveSW_FL_Status 7;
BA_ "GenSigSendType" SG_ 272 APM_Window_DriveSW_FL_Status 0;
BA_ "GenSigInvalidValue" SG_ 272 APM_Window_DriveSW_FR_Status 7;
BA_ "GenSigSendType" SG_ 272 APM_Window_DriveSW_FR_Status 0;
BA_ "GenSigInvalidValue" SG_ 272 APM_Window_DriveSW_RL_Status 7;
BA_ "GenSigSendType" SG_ 272 APM_Window_DriveSW_RL_Status 0;
BA_ "GenSigInvalidValue" SG_ 272 APM_Window_DriveSW_RR_Status 7;
BA_ "GenSigSendType" SG_ 272 APM_Window_DriveSW_RR_Status 0;
BA_ "GenSigInvalidValue" SG_ 272 APM_Window_PassengerSW_Status 7;
BA_ "GenSigSendType" SG_ 272 APM_Window_PassengerSW_Status 0;
BA_ "GenSigInvalidValue" SG_ 272 APM_Window_PassengerSW_RL_Status 7;
BA_ "GenSigSendType" SG_ 272 APM_Window_PassengerSW_RL_Status 0;
BA_ "GenSigInvalidValue" SG_ 272 APM_Window_PassengerSW_RR_Status 7;
BA_ "GenSigSendType" SG_ 272 APM_Window_PassengerSW_RR_Status 0;
BA_ "GenSigSendType" SG_ 769 VOD_Block 0;
BA_ "GenSigSendType" SG_ 769 VOD_UpdateFlag 0;
BA_ "GenSigStartValue" SG_ 769 VOD_Byte1 255;
BA_ "GenSigSendType" SG_ 769 VOD_Byte1 0;
BA_ "GenSigStartValue" SG_ 769 VOD_Byte2 255;
BA_ "GenSigSendType" SG_ 769 VOD_Byte2 0;
BA_ "GenSigStartValue" SG_ 769 VOD_Byte3 255;
BA_ "GenSigSendType" SG_ 769 VOD_Byte3 0;
BA_ "GenSigStartValue" SG_ 769 VOD_Byte4 255;
BA_ "GenSigSendType" SG_ 769 VOD_Byte4 0;
BA_ "GenSigStartValue" SG_ 769 VOD_Byte5 255;
BA_ "GenSigSendType" SG_ 769 VOD_Byte5 0;
BA_ "GenSigStartValue" SG_ 769 VOD_Byte6 255;
BA_ "GenSigSendType" SG_ 769 VOD_Byte6 0;
BA_ "GenSigStartValue" SG_ 769 VOD_Byte7 255;
BA_ "GenSigSendType" SG_ 769 VOD_Byte7 0;
BA_ "GenSigSendType" SG_ 770 IPC_VOD_Block 0;
BA_ "GenSigSendType" SG_ 770 IPC_VOD_UpdateFlag 0;
BA_ "GenSigStartValue" SG_ 770 IPC_VOD_Byte1 255;
BA_ "GenSigSendType" SG_ 770 IPC_VOD_Byte1 0;
BA_ "GenSigStartValue" SG_ 770 IPC_VOD_Byte2 255;
BA_ "GenSigSendType" SG_ 770 IPC_VOD_Byte2 0;
BA_ "GenSigStartValue" SG_ 770 IPC_VOD_Byte3 255;
BA_ "GenSigSendType" SG_ 770 IPC_VOD_Byte3 0;
BA_ "GenSigStartValue" SG_ 770 IPC_VOD_Byte4 255;
BA_ "GenSigSendType" SG_ 770 IPC_VOD_Byte4 0;
BA_ "GenSigStartValue" SG_ 770 IPC_VOD_Byte5 255;
BA_ "GenSigSendType" SG_ 770 IPC_VOD_Byte5 0;
BA_ "GenSigStartValue" SG_ 770 IPC_VOD_Byte6 255;
BA_ "GenSigSendType" SG_ 770 IPC_VOD_Byte6 0;
BA_ "GenSigStartValue" SG_ 770 IPC_VOD_Byte7 255;
BA_ "GenSigSendType" SG_ 770 IPC_VOD_Byte7 0;
BA_ "GenSigSendType" SG_ 923 BCM_Immo_MHU_Byte_0 1;
BA_ "GenSigSendType" SG_ 923 BCM_Immo_MHU_Byte_1 1;
BA_ "GenSigSendType" SG_ 923 BCM_Immo_MHU_Byte_2 1;
BA_ "GenSigSendType" SG_ 923 BCM_Immo_MHU_Byte_3 1;
BA_ "GenSigSendType" SG_ 923 BCM_Immo_MHU_Byte_4 1;
BA_ "GenSigSendType" SG_ 923 BCM_Immo_MHU_Byte_5 1;
BA_ "GenSigSendType" SG_ 923 BCM_Immo_MHU_Byte_6 1;
BA_ "GenSigSendType" SG_ 923 BCM_Immo_MHU_Byte_7 1;
BA_ "GenSigSendType" SG_ 922 MHU_Immo_Byte_0 1;
BA_ "GenSigSendType" SG_ 922 MHU_Immo_Byte_1 1;
BA_ "GenSigSendType" SG_ 922 MHU_Immo_Byte_2 1;
BA_ "GenSigSendType" SG_ 922 MHU_Immo_Byte_3 1;
BA_ "GenSigSendType" SG_ 922 MHU_Immo_Byte_4 1;
BA_ "GenSigSendType" SG_ 922 MHU_Immo_Byte_5 1;
BA_ "GenSigSendType" SG_ 922 MHU_Immo_Byte_6 1;
BA_ "GenSigSendType" SG_ 922 MHU_Immo_Byte_7 1;
BA_ "GenSigSendType" SG_ 920 BCM_Immo_Byte_0 1;
BA_ "GenSigSendType" SG_ 920 BCM_Immo_Byte_1 1;
BA_ "GenSigSendType" SG_ 920 BCM_Immo_Byte_2 1;
BA_ "GenSigSendType" SG_ 920 BCM_Immo_Byte_3 1;
BA_ "GenSigSendType" SG_ 920 BCM_Immo_Byte_4 1;
BA_ "GenSigSendType" SG_ 920 BCM_Immo_Byte_5 1;
BA_ "GenSigSendType" SG_ 920 BCM_Immo_Byte_6 1;
BA_ "GenSigSendType" SG_ 920 BCM_Immo_Byte_7 1;
BA_ "GenSigSendType" SG_ 921 VCU_Immo_Byte_0 1;
BA_ "GenSigSendType" SG_ 921 VCU_Immo_Byte_1 1;
BA_ "GenSigSendType" SG_ 921 VCU_Immo_Byte_2 1;
BA_ "GenSigSendType" SG_ 921 VCU_Immo_Byte_3 1;
BA_ "GenSigSendType" SG_ 921 VCU_Immo_Byte_4 1;
BA_ "GenSigSendType" SG_ 921 VCU_Immo_Byte_5 1;
BA_ "GenSigSendType" SG_ 921 VCU_Immo_Byte_6 1;
BA_ "GenSigSendType" SG_ 921 VCU_Immo_Byte_7 1;
BA_ "GenSigSendType" SG_ 296 Checksum_0x128 0;
BA_ "GenSigInvalidValue" SG_ 296 Rolling_Counter_0x128 15;
BA_ "GenSigSendType" SG_ 296 Rolling_Counter_0x128 0;
BA_ "GenSigSendType" SG_ 296 ADAS_RCTA_IndLeft 0;
BA_ "GenSigSendType" SG_ 296 ADAS_RCTA_IndRight 0;
BA_ "GenSigSendType" SG_ 296 ADAS_RCTA_SndWarn 0;
BA_ "GenSigInvalidValue" SG_ 296 ADAS_RCTA_check 3;
BA_ "GenSigSendType" SG_ 296 ADAS_RCTA_check 0;
BA_ "GenSigSendType" SG_ 296 ADAS_RCTA_state 0;
BA_ "GenSigStartValue" SG_ 296 ADAS_RCTA_sens_Feed_Reserved 1;
BA_ "GenSigInvalidValue" SG_ 296 ADAS_RCTA_sens_Feed_Reserved 3;
BA_ "GenSigSendType" SG_ 296 ADAS_RCTA_sens_Feed_Reserved 0;
BA_ "GenSigStartValue" SG_ 296 ADAS_RCTA_Mode_Feed 1;
BA_ "GenSigInvalidValue" SG_ 296 ADAS_RCTA_Mode_Feed 3;
BA_ "GenSigSendType" SG_ 296 ADAS_RCTA_Mode_Feed 0;
BA_ "GenSigSendType" SG_ 307 Checksum_0x133 0;
BA_ "GenSigInvalidValue" SG_ 307 Rolling_Counter_0x133 15;
BA_ "GenSigSendType" SG_ 307 Rolling_Counter_0x133 0;
BA_ "GenSigInvalidValue" SG_ 307 ADAS_BSD_check 3;
BA_ "GenSigSendType" SG_ 307 ADAS_BSD_check 0;
BA_ "GenSigSendType" SG_ 307 ADAS_BSD_state 0;
BA_ "GenSigStartValue" SG_ 307 ADAS_BSD_AudChime_Feed 1;
BA_ "GenSigInvalidValue" SG_ 307 ADAS_BSD_AudChime_Feed 3;
BA_ "GenSigSendType" SG_ 307 ADAS_BSD_AudChime_Feed 0;
BA_ "GenSigSendType" SG_ 307 ADAS_BSD_IndLeft 0;
BA_ "GenSigSendType" SG_ 307 ADAS_BSD_IndRight 0;
BA_ "GenSigSendType" SG_ 307 ADAS_BSD_SndWarn 0;
BA_ "GenSigStartValue" SG_ 307 ADAS_BSD_Mode_Feed 1;
BA_ "GenSigInvalidValue" SG_ 307 ADAS_BSD_Mode_Feed 3;
BA_ "GenSigSendType" SG_ 307 ADAS_BSD_Mode_Feed 0;
BA_ "GenSigStartValue" SG_ 307 ADAS_BSD_sens_Feed 1;
BA_ "GenSigInvalidValue" SG_ 307 ADAS_BSD_sens_Feed 3;
BA_ "GenSigSendType" SG_ 307 ADAS_BSD_sens_Feed 0;
BA_ "GenSigSendType" SG_ 850 Checksum_0x352 0;
BA_ "GenSigInvalidValue" SG_ 850 Rolling_Counter_0x352 15;
BA_ "GenSigSendType" SG_ 850 Rolling_Counter_0x352 0;
BA_ "GenSigSendType" SG_ 850 ADAS_DOW_Warn 0;
BA_ "GenSigSendType" SG_ 850 ADAS_DOW_SndWarn 0;
BA_ "GenSigSendType" SG_ 850 ADAS_DOW_state 0;
BA_ "GenSigSendType" SG_ 850 ADAS_DOW_IndLeft 0;
BA_ "GenSigSendType" SG_ 850 ADAS_DOW_IndRight 0;
BA_ "GenSigStartValue" SG_ 850 ADAS_DOW_sens_Feed_Reserved 1;
BA_ "GenSigInvalidValue" SG_ 850 ADAS_DOW_sens_Feed_Reserved 3;
BA_ "GenSigSendType" SG_ 850 ADAS_DOW_sens_Feed_Reserved 0;
BA_ "GenSigStartValue" SG_ 850 ADAS_DOW_Mode_Feed 1;
BA_ "GenSigInvalidValue" SG_ 850 ADAS_DOW_Mode_Feed 3;
BA_ "GenSigSendType" SG_ 850 ADAS_DOW_Mode_Feed 0;
BA_ "GenSigStartValue" SG_ 850 ADAS_DOW_AudChime_Feed 1;
BA_ "GenSigInvalidValue" SG_ 850 ADAS_DOW_AudChime_Feed 3;
BA_ "GenSigSendType" SG_ 850 ADAS_DOW_AudChime_Feed 0;
BA_ "GenSigInvalidValue" SG_ 850 ADAS_DOW_check 3;
BA_ "GenSigSendType" SG_ 850 ADAS_DOW_check 0;
BA_ "GenSigSendType" SG_ 1216 Checksum_0x4C0 0;
BA_ "GenSigInvalidValue" SG_ 1216 Rolling_Counter_0x4C0 15;
BA_ "GenSigSendType" SG_ 1216 Rolling_Counter_0x4C0 0;
BA_ "GenSigSendType" SG_ 1216 ADAS_Warning_Flag_1 0;
BA_ "GenSigSendType" SG_ 1216 ADAS_Warning_Flag_2 0;
BA_ "GenSigSendType" SG_ 1216 ADAS_Warning_Flag_3 0;
BA_ "GenSigSendType" SG_ 1216 ADAS_Warning_Flag_4 0;
BA_ "GenSigSendType" SG_ 1216 ADAS_Warning_Flag_5 0;
BA_ "GenSigSendType" SG_ 1216 ADAS_Warning_Flag_6 0;
BA_ "GenSigSendType" SG_ 1216 ADAS_Warning_Flag_7 0;
BA_ "GenSigSendType" SG_ 1216 ADAS_Warning_Flag_8 0;
BA_ "GenSigSendType" SG_ 1216 ADAS_Warning_Flag_9 0;
BA_ "GenSigSendType" SG_ 1216 ADAS_Warning_Flag_10 0;
BA_ "GenSigSendType" SG_ 1216 ADAS_Warning_Flag_11 0;
BA_ "GenSigSendType" SG_ 1216 ADAS_Warning_Flag_12 0;
BA_ "GenSigSendType" SG_ 1216 ADAS_Warning_Flag_13 0;
BA_ "GenSigSendType" SG_ 1216 ADAS_Warning_Flag_14 0;
BA_ "GenSigSendType" SG_ 1216 ADAS_Warning_Flag_15 0;
BA_ "GenSigSendType" SG_ 1216 ADAS_Warning_Flag_16 0;
BA_ "GenSigSendType" SG_ 1216 ADAS_Warning_Flag_17 0;
BA_ "GenSigSendType" SG_ 1216 ADAS_Warning_Flag_18 0;
BA_ "GenSigSendType" SG_ 1216 ADAS_Warning_Flag_19 0;
BA_ "GenSigSendType" SG_ 1216 ADAS_Warning_Flag_20 0;
BA_ "GenSigSendType" SG_ 1216 ADAS_Warning_Flag_21 0;
BA_ "GenSigSendType" SG_ 1216 ADAS_Warning_Flag_22 0;
BA_ "GenSigSendType" SG_ 1216 ADAS_Warning_Flag_23 0;
BA_ "GenSigSendType" SG_ 1216 ADAS_Warning_Flag_24 0;
BA_ "GenSigSendType" SG_ 1216 ADAS_Warning_Flag_25 0;
BA_ "GenSigSendType" SG_ 1216 ADAS_Warning_Flag_26 0;
BA_ "GenSigSendType" SG_ 1216 ADAS_Warning_Flag_27 0;
BA_ "GenSigSendType" SG_ 1216 ADAS_Warning_Flag_28 0;
BA_ "GenSigSendType" SG_ 1216 ADAS_Reserved_signal3 0;
BA_ "GenSigSendType" SG_ 1216 ADAS_Reserved_signal4 0;
BA_ "GenSigSendType" SG_ 1216 ADAS_Reserved_signal5 0;
BA_ "GenSigSendType" SG_ 851 Checksum_0x353 0;
BA_ "GenSigInvalidValue" SG_ 851 Rolling_Counter_0x353 15;
BA_ "GenSigSendType" SG_ 851 Rolling_Counter_0x353 0;
BA_ "GenSigSendType" SG_ 851 ADAS_RadarRight_Cal_Status 0;
BA_ "GenSigSendType" SG_ 851 ADAS_RadarLeft_Cal_Status 0;
BA_ "GenSigSendType" SG_ 851 ADAS_RadarRight_DynaCal_Status 0;
BA_ "GenSigSendType" SG_ 851 ADAS_RadarLeft_DynaCal_Status 0;
BA_ "GenSigSendType" SG_ 851 ADAS_MasterSRR_check 0;
BA_ "GenSigSendType" SG_ 851 ADAS_SlaveSRR_check 0;
BA_ "GenSigInvalidValue" SG_ 851 ADAS_CalSensorMasterProgress 255;
BA_ "GenSigSendType" SG_ 851 ADAS_CalSensorMasterProgress 0;
BA_ "GenSigInvalidValue" SG_ 851 ADAS_CalSensorSlaverProgress 255;
BA_ "GenSigSendType" SG_ 851 ADAS_CalSensorSlaverProgress 0;
BA_ "GenSigSendType" SG_ 851 ADAS_Cal_LeftInstallDeviation 0;
BA_ "GenSigSendType" SG_ 851 ADAS_Cal_RightInstallDeviation 0;
BA_ "GenSigSendType" SG_ 834 Checksum_0x342 0;
BA_ "GenSigInvalidValue" SG_ 834 RollingCounter_0x342 15;
BA_ "GenSigSendType" SG_ 834 RollingCounter_0x342 0;
BA_ "GenSigInvalidValue" SG_ 834 ABS_LRWhlSpdRaw 32767;
BA_ "GenSigSendType" SG_ 834 ABS_LRWhlSpdRaw 0;
BA_ "GenSigSendType" SG_ 834 ABS_LRWhlSpdRawValid 0;
BA_ "GenSigInvalidValue" SG_ 834 ABS_RRWhlSpdRaw 32767;
BA_ "GenSigSendType" SG_ 834 ABS_RRWhlSpdRaw 0;
BA_ "GenSigSendType" SG_ 834 ABS_RRWhlSpdRawValid 0;
BA_ "GenSigInvalidValue" SG_ 834 ABS_VehSpd 32767;
BA_ "GenSigSendType" SG_ 834 ABS_VehSpd 0;
BA_ "GenSigSendType" SG_ 834 ABS_VehSpdValid 0;
BA_ "GenSigSendType" SG_ 322 Checksum_0x142 0;
BA_ "GenSigInvalidValue" SG_ 322 RollingCounter_0x142 15;
BA_ "GenSigSendType" SG_ 322 RollingCounter_0x142 0;
BA_ "GenSigSendType" SG_ 322 AbsDiagSessionLampReq_Reserved 0;
BA_ "GenSigSendType" SG_ 322 ABS_AbsCtrlActv 0;
BA_ "GenSigSendType" SG_ 322 ABS_EbdFlgFlt 0;
BA_ "GenSigSendType" SG_ 322 ABS_AbsFlgFlt 0;
BA_ "GenSigSendType" SG_ 322 ABS_ESS_Active 0;
BA_ "GenSigSendType" SG_ 322 ABS_LowBrakeFluid 0;
BA_ "GenSigSendType" SG_ 306 Checksum_0x132 0;
BA_ "GenSigInvalidValue" SG_ 306 RollingCounter_0x132 15;
BA_ "GenSigSendType" SG_ 306 RollingCounter_0x132 0;
BA_ "GenSigSendType" SG_ 306 ESC_HSA_Control_Status 0;
BA_ "GenSigSendType" SG_ 306 ESC_HSA_Status_Fault 0;
BA_ "GenSigInvalidValue" SG_ 306 ESC_TcsDisableSts 3;
BA_ "GenSigSendType" SG_ 306 ESC_TcsDisableSts 0;
BA_ "GenSigSendType" SG_ 306 ESC_TcsCtrlActv 0;
BA_ "GenSigSendType" SG_ 306 ESC_TcsFlgFlt 0;
BA_ "GenSigSendType" SG_ 306 ESC_EscDisableSts 0;
BA_ "GenSigSendType" SG_ 306 ESC_EscCtrlActv 0;
BA_ "GenSigSendType" SG_ 306 ESC_EscFlgFlt 0;
BA_ "GenSigSendType" SG_ 306 ESC_HBAFlgFlt 0;
BA_ "GenSigSendType" SG_ 306 ESC_HbaCtrlActv 0;
BA_ "GenSigInvalidValue" SG_ 306 ESC_SlopeGradeAngle 255;
BA_ "GenSigSendType" SG_ 306 ESC_SlopeGradeAngle 0;
BA_ "GenSigStartValue" SG_ 306 ESC_MasterCylinderPressure 1000;
BA_ "GenSigInvalidValue" SG_ 306 ESC_MasterCylinderPressure 4095;
BA_ "GenSigSendType" SG_ 306 ESC_MasterCylinderPressure 0;
BA_ "GenSigSendType" SG_ 994 Checksum_0x3E2 0;
BA_ "GenSigInvalidValue" SG_ 994 RollingCounter_0x3E2 15;
BA_ "GenSigSendType" SG_ 994 RollingCounter_0x3E2 0;
BA_ "GenSigStartValue" SG_ 994 ESC_LateralACC 127;
BA_ "GenSigInvalidValue" SG_ 994 ESC_LateralACC 255;
BA_ "GenSigSendType" SG_ 994 ESC_LateralACC 0;
BA_ "GenSigSendType" SG_ 994 ESC_LateralACC_Valid 0;
BA_ "GenSigStartValue" SG_ 994 ESC_LongitudeACC 511;
BA_ "GenSigInvalidValue" SG_ 994 ESC_LongitudeACC 1023;
BA_ "GenSigSendType" SG_ 994 ESC_LongitudeACC 0;
BA_ "GenSigSendType" SG_ 994 ESC_LongitudeACC_Valid 0;
BA_ "GenSigInvalidValue" SG_ 994 ESC_VehDynYawRate 16383;
BA_ "GenSigSendType" SG_ 994 ESC_VehDynYawRate 0;
BA_ "GenSigSendType" SG_ 994 ESC_VehDynYawRate_Valid 0;
BA_ "GenSigSendType" SG_ 894 Checksum_0x37E 0;
BA_ "GenSigInvalidValue" SG_ 894 Rolling_counter_0x37E 15;
BA_ "GenSigSendType" SG_ 894 Rolling_counter_0x37E 0;
BA_ "GenSigInvalidValue" SG_ 894 EPS_SteeringTorque 4095;
BA_ "GenSigSendType" SG_ 894 EPS_SteeringTorque 0;
BA_ "GenSigInvalidValue" SG_ 894 EPS_TorqSensorStatus 1;
BA_ "GenSigSendType" SG_ 894 EPS_TorqSensorStatus 0;
BA_ "GenSigStartValue" SG_ 894 EPS_EpsFailed 1;
BA_ "GenSigInvalidValue" SG_ 894 EPS_EpsFailed 1;
BA_ "GenSigSendType" SG_ 894 EPS_EpsFailed 0;
BA_ "GenSigInvalidValue" SG_ 894 EPS_Mode 3;
BA_ "GenSigSendType" SG_ 894 EPS_Mode 0;
BA_ "GenSigSendType" SG_ 382 Checksum_0x17E 0;
BA_ "GenSigInvalidValue" SG_ 382 Rolling_counter_0x17E 15;
BA_ "GenSigSendType" SG_ 382 Rolling_counter_0x17E 0;
BA_ "GenSigStartValue" SG_ 382 SAS_SteerWheelAngle 32773;
BA_ "GenSigInvalidValue" SG_ 382 SAS_SteerWheelAngle 65535;
BA_ "GenSigSendType" SG_ 382 SAS_SteerWheelAngle 0;
BA_ "GenSigSendType" SG_ 382 SAS_SteeringAngleValid 0;
BA_ "GenSigSendType" SG_ 382 SAS_SASStsSnsr 0;
BA_ "GenSigInvalidValue" SG_ 382 SAS_SteerWhlRotSpd 16383;
BA_ "GenSigSendType" SG_ 382 SAS_SteerWhlRotSpd 0;
BA_ "GenSigSendType" SG_ 382 SAS_SteerWhlRotSpdStatus 0;
BA_ "GenSigSendType" SG_ 382 SAS_Calibrated 0;
BA_ "GenSigSendType" SG_ 382 SAS_SASFailure 0;
BA_ "GenSigSendType" SG_ 617 Checksum_0x269 0;
BA_ "GenSigInvalidValue" SG_ 617 RollingCounter_0x269 15;
BA_ "GenSigSendType" SG_ 617 RollingCounter_0x269 0;
BA_ "GenSigInvalidValue" SG_ 617 VCU_VehicleHVStatus 3;
BA_ "GenSigSendType" SG_ 617 VCU_VehicleHVStatus 0;
BA_ "GenSigStartValue" SG_ 617 VCU_ActualGear 2;
BA_ "GenSigInvalidValue" SG_ 617 VCU_ActualGear 7;
BA_ "GenSigSendType" SG_ 617 VCU_ActualGear 0;
BA_ "GenSigInvalidValue" SG_ 617 VCU_ActualGearValid 1;
BA_ "GenSigSendType" SG_ 617 VCU_ActualGearValid 0;
BA_ "GenSigInvalidValue" SG_ 617 VCU_AccPedalPosition 255;
BA_ "GenSigSendType" SG_ 617 VCU_AccPedalPosition 0;
BA_ "GenSigInvalidValue" SG_ 617 VCU_AccPedalPositionValid 1;
BA_ "GenSigSendType" SG_ 617 VCU_AccPedalPositionValid 0;
BA_ "GenSigStartValue" SG_ 617 VCU_TqReductionRqstResponse_Rese 1;
BA_ "GenSigSendType" SG_ 617 VCU_TqReductionRqstResponse_Rese 0;
BA_ "SystemSignalLongSymbol" SG_ 617 VCU_TqReductionRqstResponse_Rese "VCU_TqReductionRqstResponse_Reserved";
BA_ "GenSigInvalidValue" SG_ 617 VCU_BrakePedalSts 3;
BA_ "GenSigSendType" SG_ 617 VCU_BrakePedalSts 0;
BA_ "GenSigStartValue" SG_ 814 CCU_ExternalTemperature 255;
BA_ "GenSigInvalidValue" SG_ 814 CCU_ExternalTemperature 255;
BA_ "GenSigSendType" SG_ 814 CCU_ExternalTemperature 0;
BA_ "GenSigStartValue" SG_ 814 CCU_ExternalTemperatureFailSts 1;
BA_ "GenSigInvalidValue" SG_ 814 CCU_ExternalTemperatureFailSts 1;
BA_ "GenSigSendType" SG_ 814 CCU_ExternalTemperatureFailSts 0;
BA_ "GenSigInvalidValue" SG_ 1087 IPC_Sec 63;
BA_ "GenSigSendType" SG_ 1087 IPC_Sec 0;
BA_ "GenSigInvalidValue" SG_ 1087 IPC_Min 63;
BA_ "GenSigSendType" SG_ 1087 IPC_Min 0;
BA_ "GenSigInvalidValue" SG_ 1087 IPC_Hour 31;
BA_ "GenSigSendType" SG_ 1087 IPC_Hour 0;
BA_ "GenSigStartValue" SG_ 1087 IPC_Day 1;
BA_ "GenSigInvalidValue" SG_ 1087 IPC_Day 31;
BA_ "GenSigSendType" SG_ 1087 IPC_Day 0;
BA_ "GenSigStartValue" SG_ 1087 IPC_Month 1;
BA_ "GenSigInvalidValue" SG_ 1087 IPC_Month 15;
BA_ "GenSigSendType" SG_ 1087 IPC_Month 0;
BA_ "GenSigInvalidValue" SG_ 1087 IPC_Year 255;
BA_ "GenSigSendType" SG_ 1087 IPC_Year 0;
BA_ "GenSigSendType" SG_ 1087 IPC_SelfCheckStatus 0;
BA_ "GenSigSendType" SG_ 524 Checksum_0x20C 0;
BA_ "GenSigInvalidValue" SG_ 524 Rolling_Counter_0x20C 15;
BA_ "GenSigSendType" SG_ 524 Rolling_Counter_0x20C 0;
BA_ "GenSigInvalidValue" SG_ 524 IPC_ODO 1048575;
BA_ "GenSigSendType" SG_ 524 IPC_ODO 0;
BA_ "GenSigInvalidValue" SG_ 703 IPC_TripA 65535;
BA_ "GenSigSendType" SG_ 703 IPC_TripA 0;
BA_ "GenSigInvalidValue" SG_ 703 IPC_AverageSpeedTripA 4095;
BA_ "GenSigSendType" SG_ 703 IPC_AverageSpeedTripA 0;
BA_ "GenSigInvalidValue" SG_ 703 IPC_AverageConsumptionTripA 1023;
BA_ "GenSigSendType" SG_ 703 IPC_AverageConsumptionTripA 0;
BA_ "GenSigInvalidValue" SG_ 703 IPC_ParkBrakeSts 3;
BA_ "GenSigSendType" SG_ 703 IPC_ParkBrakeSts 0;
BA_ "GenSigInvalidValue" SG_ 703 IPC_VehSpd 32767;
BA_ "GenSigSendType" SG_ 703 IPC_VehSpd 0;
BA_ "GenSigStartValue" SG_ 1025 MHU_SET_DoorSpeedLock 6;
BA_ "GenSigSendType" SG_ 1025 MHU_SET_DoorSpeedLock 1;
BA_ "GenSigStartValue" SG_ 1025 MHU_SET_RemoteDoorUnlock_reserve 2;
BA_ "GenSigSendType" SG_ 1025 MHU_SET_RemoteDoorUnlock_reserve 1;
BA_ "SystemSignalLongSymbol" SG_ 1025 MHU_SET_RemoteDoorUnlock_reserve "MHU_SET_RemoteDoorUnlock_reserved";
BA_ "GenSigStartValue" SG_ 1025 MHU_SET_RemoteLockFeedback 4;
BA_ "GenSigSendType" SG_ 1025 MHU_SET_RemoteLockFeedback 1;
BA_ "GenSigStartValue" SG_ 1025 MHU_SET_AutoUnlockDoor 2;
BA_ "GenSigSendType" SG_ 1025 MHU_SET_AutoUnlockDoor 1;
BA_ "GenSigStartValue" SG_ 1025 MHU_SET_MirrorAuto_reserved 1;
BA_ "GenSigSendType" SG_ 1025 MHU_SET_MirrorAuto_reserved 1;
BA_ "GenSigStartValue" SG_ 1025 MHU_Anti_theftAlarmSet 4;
BA_ "GenSigSendType" SG_ 1025 MHU_Anti_theftAlarmSet 2;
BA_ "GenSigSendType" SG_ 1025 MHU_TriggerReadKey 2;
BA_ "GenSigStartValue" SG_ 1026 MHU_Heatrearglass_Set 2;
BA_ "GenSigInvalidValue" SG_ 1026 MHU_Heatrearglass_Set 3;
BA_ "GenSigSendType" SG_ 1026 MHU_Heatrearglass_Set 2;
BA_ "GenSigStartValue" SG_ 1026 MHU_SET_DayTimeRunningLight_rese 1;
BA_ "GenSigSendType" SG_ 1026 MHU_SET_DayTimeRunningLight_rese 2;
BA_ "SystemSignalLongSymbol" SG_ 1026 MHU_SET_DayTimeRunningLight_rese "MHU_SET_DayTimeRunningLight_reserved";
BA_ "GenSigSendType" SG_ 1026 MHU_SET_FollowMeHomeTime 2;
BA_ "GenSigStartValue" SG_ 967 MHU_VehsSpd_Warn 12000;
BA_ "GenSigInvalidValue" SG_ 967 MHU_VehsSpd_Warn 32767;
BA_ "GenSigSendType" SG_ 967 MHU_VehsSpd_Warn 2;
BA_ "GenSigInvalidValue" SG_ 967 MHU_SET_Volume 255;
BA_ "GenSigSendType" SG_ 967 MHU_SET_Volume 2;
BA_ "GenSigStartValue" SG_ 967 MHU_St_DimmingIPC 10;
BA_ "GenSigInvalidValue" SG_ 967 MHU_St_DimmingIPC 15;
BA_ "GenSigSendType" SG_ 967 MHU_St_DimmingIPC 2;
BA_ "GenSigSendType" SG_ 1074 Checksum_0x432 0;
BA_ "GenSigInvalidValue" SG_ 1074 Rolling_Counter_0x432 15;
BA_ "GenSigSendType" SG_ 1074 Rolling_Counter_0x432 0;
BA_ "GenSigSendType" SG_ 1074 MHU_FOTA_State 0;
BA_ "GenSigSendType" SG_ 1074 MHU_FOTA_Error_Code 0;
BA_ "GenSigInvalidValue" SG_ 267 TBOX_STAT_TerminalReq 7;
BA_ "GenSigSendType" SG_ 267 TBOX_STAT_TerminalReq 2;
BA_ "GenSigSendType" SG_ 267 TBOX_AuthCode_0x10B 1;
BA_ "GenSigStartValue" SG_ 269 MHU_BCM_reqTrunk 2;
BA_ "GenSigSendType" SG_ 269 MHU_BCM_reqTrunk 2;
BA_ "GenSigStartValue" SG_ 269 MHU_BCM_RemoteDoorCtrl 2;
BA_ "GenSigSendType" SG_ 269 MHU_BCM_RemoteDoorCtrl 2;
BA_ "GenSigInvalidValue" SG_ 269 MHU_APM_ReqWindow 7;
BA_ "GenSigSendType" SG_ 269 MHU_APM_ReqWindow 2;
BA_ "GenSigSendType" SG_ 269 TBOX_AuthCode_0x10D 1;
BA_ "GenSigStartValue" SG_ 271 MHU_SetHighBeam 2;
BA_ "GenSigInvalidValue" SG_ 271 MHU_SetHighBeam 3;
BA_ "GenSigSendType" SG_ 271 MHU_SetHighBeam 2;
BA_ "GenSigStartValue" SG_ 271 MHU_SetHornOnOff 2;
BA_ "GenSigInvalidValue" SG_ 271 MHU_SetHornOnOff 3;
BA_ "GenSigSendType" SG_ 271 MHU_SetHornOnOff 2;
BA_ "GenSigStartValue" SG_ 271 MHU_SetLowBeam 2;
BA_ "GenSigInvalidValue" SG_ 271 MHU_SetLowBeam 3;
BA_ "GenSigSendType" SG_ 271 MHU_SetLowBeam 2;
BA_ "GenSigSendType" SG_ 271 TBOX_AuthCode_0x10F 1;
BA_ "GenSigStartValue" SG_ 852 MHU_BSD_On 2;
BA_ "GenSigInvalidValue" SG_ 852 MHU_BSD_On 3;
BA_ "GenSigSendType" SG_ 852 MHU_BSD_On 1;
BA_ "GenSigStartValue" SG_ 852 MHU_BSD_sens_Reserved 3;
BA_ "GenSigInvalidValue" SG_ 852 MHU_BSD_sens_Reserved 7;
BA_ "GenSigSendType" SG_ 852 MHU_BSD_sens_Reserved 1;
BA_ "GenSigStartValue" SG_ 852 MHU_BSD_AudWarning 2;
BA_ "GenSigInvalidValue" SG_ 852 MHU_BSD_AudWarning 3;
BA_ "GenSigSendType" SG_ 852 MHU_BSD_AudWarning 1;
BA_ "GenSigStartValue" SG_ 852 MHU_RCTA_On 2;
BA_ "GenSigInvalidValue" SG_ 852 MHU_RCTA_On 3;
BA_ "GenSigSendType" SG_ 852 MHU_RCTA_On 1;
BA_ "GenSigStartValue" SG_ 852 MHU_RCTA_sens_Reserved 3;
BA_ "GenSigInvalidValue" SG_ 852 MHU_RCTA_sens_Reserved 7;
BA_ "GenSigSendType" SG_ 852 MHU_RCTA_sens_Reserved 1;
BA_ "GenSigStartValue" SG_ 852 MHU_PA_On 2;
BA_ "GenSigInvalidValue" SG_ 852 MHU_PA_On 3;
BA_ "GenSigSendType" SG_ 852 MHU_PA_On 1;
BA_ "GenSigStartValue" SG_ 852 MHU_DOW_Mode 2;
BA_ "GenSigInvalidValue" SG_ 852 MHU_DOW_Mode 3;
BA_ "GenSigSendType" SG_ 852 MHU_DOW_Mode 1;
BA_ "GenSigStartValue" SG_ 852 MHU_DOW_sens_Reserved 3;
BA_ "GenSigInvalidValue" SG_ 852 MHU_DOW_sens_Reserved 7;
BA_ "GenSigSendType" SG_ 852 MHU_DOW_sens_Reserved 1;
BA_ "GenSigStartValue" SG_ 852 MHU_DOW_AudWarning 2;
BA_ "GenSigInvalidValue" SG_ 852 MHU_DOW_AudWarning 3;
BA_ "GenSigSendType" SG_ 852 MHU_DOW_AudWarning 1;
BA_ "GenSigStartValue" SG_ 425 VCU_RegenLevel_Feed 2;
BA_ "GenSigSendType" SG_ 425 VCU_RegenLevel_Feed 0;
BA_ "GenSigSendType" SG_ 425 VCU_RBCSts 0;
BA_ "GenSigSendType" SG_ 425 VCU_RDCSts 0;
BA_ "GenSigSendType" SG_ 425 VCU_Veh_ERR 0;
BA_ "GenSigSendType" SG_ 425 VCU_DrvSys_ERR 0;
BA_ "GenSigSendType" SG_ 425 VCU_PackSys_ERR 0;
BA_ "GenSigSendType" SG_ 425 VCU_TBOX_Veh_STS_Reserved 0;
BA_ "GenSigSendType" SG_ 425 VCU_VehChg_STS 0;
BA_ "GenSigStartValue" SG_ 425 VCU_BatterVoltage_Reserved 171;
BA_ "GenSigInvalidValue" SG_ 425 VCU_BatterVoltage_Reserved 255;
BA_ "GenSigSendType" SG_ 425 VCU_BatterVoltage_Reserved 0;
BA_ "GenSigSendType" SG_ 425 VCU_BatteryVoltErr_Reserved 0;
BA_ "GenSigSendType" SG_ 425 VCU_MotorCoolingCircuitErr_Reser 0;
BA_ "SystemSignalLongSymbol" SG_ 425 VCU_MotorCoolingCircuitErr_Reser "VCU_MotorCoolingCircuitErr_Reserved";
BA_ "GenSigSendType" SG_ 425 VCU_PackCoolingCircuitErr_Reserv 0;
BA_ "SystemSignalLongSymbol" SG_ 425 VCU_PackCoolingCircuitErr_Reserv "VCU_PackCoolingCircuitErr_Reserved";
BA_ "GenSigInvalidValue" SG_ 425 VCU_VehicleHVStatus 3;
BA_ "GenSigSendType" SG_ 425 VCU_VehicleHVStatus 0;
BA_ "GenSigInvalidValue" SG_ 425 VCU_InstantPowerConsump 1023;
BA_ "GenSigSendType" SG_ 425 VCU_InstantPowerConsump 0;
BA_ "GenSigInvalidValue" SG_ 425 VCU_AveragePowerConsump 1023;
BA_ "GenSigSendType" SG_ 425 VCU_AveragePowerConsump 0;
BA_ "GenSigSendType" SG_ 425 VCU_BrakePedalSts 0;
BA_ "GenSigSendType" SG_ 725 VCU_DCDC_Output_REQ 0;
BA_ "GenSigInvalidValue" SG_ 725 VCU_DCDC_OutVoltage_REQ 511;
BA_ "GenSigSendType" SG_ 725 VCU_DCDC_OutVoltage_REQ 0;
BA_ "GenSigInvalidValue" SG_ 725 VCU_DCDCAllowedPower 511;
BA_ "GenSigSendType" SG_ 725 VCU_DCDCAllowedPower 0;
BA_ "GenSigSendType" SG_ 905 VCU_FanControl_Sts 0;
BA_ "GenSigStartValue" SG_ 905 VCU_HVACInletWateTemp 40;
BA_ "GenSigInvalidValue" SG_ 905 VCU_HVACInletWateTemp 255;
BA_ "GenSigSendType" SG_ 905 VCU_HVACInletWateTemp 0;
BA_ "GenSigInvalidValue" SG_ 905 VCU_IMMO_Sts 2;
BA_ "GenSigSendType" SG_ 905 VCU_IMMO_Sts 0;
BA_ "GenSigInvalidValue" SG_ 905 VCU_VacuumSts_reserved 3;
BA_ "GenSigSendType" SG_ 905 VCU_VacuumSts_reserved 0;
BA_ "GenSigInvalidValue" SG_ 905 VCU_VacuumPresWrn 3;
BA_ "GenSigSendType" SG_ 905 VCU_VacuumPresWrn 0;
BA_ "GenSigSendType" SG_ 504 Checksum_0x1F8 0;
BA_ "GenSigInvalidValue" SG_ 504 Rolling_Counter_0x1F8 15;
BA_ "GenSigSendType" SG_ 504 Rolling_Counter_0x1F8 0;
BA_ "GenSigStartValue" SG_ 504 EDS_output_trq_FR 4000;
BA_ "GenSigInvalidValue" SG_ 504 EDS_output_trq_FR 65535;
BA_ "GenSigSendType" SG_ 504 EDS_output_trq_FR 0;
BA_ "GenSigSendType" SG_ 504 EDS_output_trqValid_FR 0;
BA_ "GenSigStartValue" SG_ 504 EDS_Spd_FR 20000;
BA_ "GenSigInvalidValue" SG_ 504 EDS_Spd_FR 65535;
BA_ "GenSigSendType" SG_ 504 EDS_Spd_FR 0;
BA_ "GenSigSendType" SG_ 504 EDS_SpdValid_FR 0;
BA_ "GenSigInvalidValue" SG_ 504 EDS_MotorDriveSts_FR 3;
BA_ "GenSigSendType" SG_ 504 EDS_MotorDriveSts_FR 0;
BA_ "GenSigInvalidValue" SG_ 504 EDS_Work_STS_FR 15;
BA_ "GenSigSendType" SG_ 504 EDS_Work_STS_FR 0;
BA_ "GenSigSendType" SG_ 504 EDS_powoff_req_FR 0;
BA_ "GenSigSendType" SG_ 533 Checksum_0x215 0;
BA_ "GenSigInvalidValue" SG_ 533 Rolling_Counter_0x215 15;
BA_ "GenSigSendType" SG_ 533 Rolling_Counter_0x215 0;
BA_ "GenSigStartValue" SG_ 533 BMS_SOE 54;
BA_ "GenSigInvalidValue" SG_ 533 BMS_SOE 255;
BA_ "GenSigSendType" SG_ 533 BMS_SOE 0;
BA_ "GenSigSendType" SG_ 533 BMS_HWCrash_Sts 0;
BA_ "GenSigSendType" SG_ 533 BMS_HVIL_STS 0;
BA_ "GenSigSendType" SG_ 533 BMS_IGN_Sts 0;
BA_ "GenSigInvalidValue" SG_ 533 BMS_Sys_STS 8;
BA_ "GenSigSendType" SG_ 533 BMS_Sys_STS 0;
BA_ "GenSigSendType" SG_ 533 BMS_HVOnOff_STS 0;
BA_ "GenSigSendType" SG_ 533 BMS_Balance_STS 0;
BA_ "GenSigInvalidValue" SG_ 533 BMS_SocActual_EST 1023;
BA_ "GenSigSendType" SG_ 533 BMS_SocActual_EST 0;
BA_ "GenSigSendType" SG_ 533 BMS_BatBalance_ERR 0;
BA_ "GenSigSendType" SG_ 533 BMS_ISU_Status 0;
BA_ "GenSigInvalidValue" SG_ 533 BMS_ERR_LEV 15;
BA_ "GenSigSendType" SG_ 533 BMS_ERR_LEV 0;
BA_ "GenSigStartValue" SG_ 533 BMS_SOH 54;
BA_ "GenSigInvalidValue" SG_ 533 BMS_SOH 255;
BA_ "GenSigSendType" SG_ 533 BMS_SOH 0;
BA_ "GenSigSendType" SG_ 533 BMS_HV_Sts 0;
BA_ "GenSigSendType" SG_ 1281 BCM_sourceID 0;
BA_ "GenSigSendType" SG_ 1281 BCM_CBV 0;
BA_ "GenSigSendType" SG_ 1281 BCM_Data0 0;
BA_ "GenSigSendType" SG_ 1281 BCM_Data1 0;
BA_ "GenSigSendType" SG_ 1281 BCM_Data2 0;
BA_ "GenSigSendType" SG_ 1281 BCM_Data3 0;
BA_ "GenSigSendType" SG_ 1281 BCM_Data4 0;
BA_ "GenSigSendType" SG_ 1281 BCM_Data5 0;
BA_ "GenSigSendType" SG_ 1288 ACM_sourceID 0;
BA_ "GenSigSendType" SG_ 1288 ACM_CBV 0;
BA_ "GenSigSendType" SG_ 1288 ACM_Data0 0;
BA_ "GenSigSendType" SG_ 1288 ACM_Data1 0;
BA_ "GenSigSendType" SG_ 1288 ACM_Data2 0;
BA_ "GenSigSendType" SG_ 1288 ACM_Data3 0;
BA_ "GenSigSendType" SG_ 1288 ACM_Data4 0;
BA_ "GenSigSendType" SG_ 1288 ACM_Data5 0;
BA_ "GenSigSendType" SG_ 1344 BSD_sourceID 0;
BA_ "GenSigSendType" SG_ 1344 BSD_CBV 0;
BA_ "GenSigSendType" SG_ 1344 BSD_Data0 0;
BA_ "GenSigSendType" SG_ 1344 BSD_Data1 0;
BA_ "GenSigSendType" SG_ 1344 BSD_Data2 0;
BA_ "GenSigSendType" SG_ 1344 BSD_Data3 0;
BA_ "GenSigSendType" SG_ 1344 BSD_Data4 0;
BA_ "GenSigSendType" SG_ 1344 BSD_Data5 0;
BA_ "GenSigSendType" SG_ 1282 GW_sourceID 0;
BA_ "GenSigSendType" SG_ 1282 GW_CBV 0;
BA_ "GenSigSendType" SG_ 1282 GW_Data0 0;
BA_ "GenSigSendType" SG_ 1282 GW_Data1 0;
BA_ "GenSigSendType" SG_ 1282 GW_Data2 0;
BA_ "GenSigSendType" SG_ 1282 GW_Data3 0;
BA_ "GenSigSendType" SG_ 1282 GW_Data4 0;
BA_ "GenSigSendType" SG_ 1282 GW_Data5 0;
BA_ "GenSigSendType" SG_ 1672 ACM_DiagReqData0 0;
BA_ "GenSigSendType" SG_ 1672 ACM_DiagReqData1 0;
BA_ "GenSigSendType" SG_ 1672 ACM_DiagReqData2 0;
BA_ "GenSigSendType" SG_ 1672 ACM_DiagReqData3 0;
BA_ "GenSigSendType" SG_ 1672 ACM_DiagReqData4 0;
BA_ "GenSigSendType" SG_ 1672 ACM_DiagReqData5 0;
BA_ "GenSigSendType" SG_ 1672 ACM_DiagReqData6 0;
BA_ "GenSigSendType" SG_ 1672 ACM_DiagReqData7 0;
BA_ "GenSigSendType" SG_ 1544 ACM_DiagRespData0 0;
BA_ "GenSigSendType" SG_ 1544 ACM_DiagRespData1 0;
BA_ "GenSigSendType" SG_ 1544 ACM_DiagRespData2 0;
BA_ "GenSigSendType" SG_ 1544 ACM_DiagRespData3 0;
BA_ "GenSigSendType" SG_ 1544 ACM_DiagRespData4 0;
BA_ "GenSigSendType" SG_ 1544 ACM_DiagRespData5 0;
BA_ "GenSigSendType" SG_ 1544 ACM_DiagRespData6 0;
BA_ "GenSigSendType" SG_ 1544 ACM_DiagRespData7 0;
BA_ "GenSigSendType" SG_ 1665 BCM_DiagReq_Data0 0;
BA_ "GenSigSendType" SG_ 1665 BCM_DiagReq_Data1 0;
BA_ "GenSigSendType" SG_ 1665 BCM_DiagReq_Data2 0;
BA_ "GenSigSendType" SG_ 1665 BCM_DiagReq_Data3 0;
BA_ "GenSigSendType" SG_ 1665 BCM_DiagReq_Data4 0;
BA_ "GenSigSendType" SG_ 1665 BCM_DiagReq_Data5 0;
BA_ "GenSigSendType" SG_ 1665 BCM_DiagReq_Data6 0;
BA_ "GenSigSendType" SG_ 1665 BCM_DiagReq_Data7 0;
BA_ "GenSigSendType" SG_ 1537 BCM_DiagResp_Data0 0;
BA_ "GenSigSendType" SG_ 1537 BCM_DiagResp_Data1 0;
BA_ "GenSigSendType" SG_ 1537 BCM_DiagResp_Data2 0;
BA_ "GenSigSendType" SG_ 1537 BCM_DiagResp_Data3 0;
BA_ "GenSigSendType" SG_ 1537 BCM_DiagResp_Data4 0;
BA_ "GenSigSendType" SG_ 1537 BCM_DiagResp_Data5 0;
BA_ "GenSigSendType" SG_ 1537 BCM_DiagResp_Data6 0;
BA_ "GenSigSendType" SG_ 1537 BCM_DiagResp_Data7 0;
BA_ "GenSigSendType" SG_ 1728 BSD_DiagReq_Data0 0;
BA_ "GenSigSendType" SG_ 1728 BSD_DiagReq_Data1 0;
BA_ "GenSigSendType" SG_ 1728 BSD_DiagReq_Data2 0;
BA_ "GenSigSendType" SG_ 1728 BSD_DiagReq_Data3 0;
BA_ "GenSigSendType" SG_ 1728 BSD_DiagReq_Data4 0;
BA_ "GenSigSendType" SG_ 1728 BSD_DiagReq_Data5 0;
BA_ "GenSigSendType" SG_ 1728 BSD_DiagReq_Data6 0;
BA_ "GenSigSendType" SG_ 1728 BSD_DiagReq_Data7 0;
BA_ "GenSigSendType" SG_ 1600 BSD_DiagResp_Data0 0;
BA_ "GenSigSendType" SG_ 1600 BSD_DiagResp_Data1 0;
BA_ "GenSigSendType" SG_ 1600 BSD_DiagResp_Data2 0;
BA_ "GenSigSendType" SG_ 1600 BSD_DiagResp_Data3 0;
BA_ "GenSigSendType" SG_ 1600 BSD_DiagResp_Data4 0;
BA_ "GenSigSendType" SG_ 1600 BSD_DiagResp_Data5 0;
BA_ "GenSigSendType" SG_ 1600 BSD_DiagResp_Data6 0;
BA_ "GenSigSendType" SG_ 1600 BSD_DiagResp_Data7 0;
BA_ "GenSigSendType" SG_ 1791 GW_DiagFunctionalAddressingData0 0;
BA_ "GenSigSendType" SG_ 1791 GW_DiagFunctionalAddressingData1 0;
BA_ "GenSigSendType" SG_ 1791 GW_DiagFunctionalAddressingData2 0;
BA_ "GenSigSendType" SG_ 1791 GW_DiagFunctionalAddressingData3 0;
BA_ "GenSigSendType" SG_ 1791 GW_DiagFunctionalAddressingData4 0;
BA_ "GenSigSendType" SG_ 1791 GW_DiagFunctionalAddressingData5 0;
BA_ "GenSigSendType" SG_ 1791 GW_DiagFunctionalAddressingData6 0;
BA_ "GenSigSendType" SG_ 1791 GW_DiagFunctionalAddressingData7 0;
VAL_ 133 Rolling_Counter_0x85 15 "Invalid" ;
VAL_ 133 ACM_Crash_Sts 3 "Invalid Value" 2 "Invalid Value" 1 "Crash_Detected" 0 "No_Event" ;
VAL_ 133 ACM_Airbag_Deployment_Status 3 "Invalid Value" 2 "Invalid Value" 1 "Airbag_Deployment" 0 "No_Airbag_Deployment" ;
VAL_ 133 ACM_Crash_Intensity 7 "Invalid_Value" 6 "Invalid_Value" 5 "Invalid_Value" 4 "Invalid_Value" 3 "Crash_Intensity_3" 2 "Crash_Intensity_2" 1 "Crash_Intensity_1" 0 "No_Crash" ;
VAL_ 133 ACM_Front_Crash 3 "Invalid Value" 2 "Invalid Value" 1 "Front_Crash_Detected" 0 "No_Event" ;
VAL_ 133 ACM_DriverSide_Crash 3 "Invalid Value" 2 "Invalid Value" 1 "Driverside_Crash_Detected" 0 "No_Event" ;
VAL_ 133 ACM_PassSide_Crash 3 "Invalid Value" 2 "Invalid Value" 1 "PassSide_Crash_Detected" 0 "No_Event" ;
VAL_ 133 ACM_Rear_Crash 3 "Invalid Value" 2 "Invalid Value" 1 "Rear_Crash_Detected" 0 "No_Event" ;
VAL_ 133 ACM_Rollover_Crash 3 "Invalid Value" 2 "Invalid Value" 1 "Rollover_Crash_Detected" 0 "No_Event" ;
VAL_ 897 Rolling_Counter_0x381 15 "Invalid" ;
VAL_ 897 ACM_Seat_Occupancy_Passenger 3 "Failure" 2 "Not_Available" 1 "Seat Occupied" 0 "Seat_Not_Occupied" ;
VAL_ 897 ACM_Seat_Occupancy_2nd_Row_Dri_r 3 "Failure" 2 "Not_Available" 1 "Seat Occupied" 0 "Seat_Not_Occupied" ;
VAL_ 897 ACM_Seat_Occupancy_2nd_Row_Pas_r 3 "Failure" 2 "Not_Available" 1 "Seat Occupied" 0 "Seat_Not_Occupied" ;
VAL_ 897 ACM_Seat_Occupancy_2nd_Row_Mid_r 3 "Failure" 2 "Not_Available" 1 "Seat Occupied" 0 "Seat_Not_Occupied" ;
VAL_ 897 ACM_Seat_Belt_Status_Passenger 3 "Failure" 2 "Not_Available" 1 "Buckled" 0 "Not_buckled" ;
VAL_ 897 ACM_Seat_Belt_Status_Driver 3 "Failure" 2 "Not_Available" 1 "Buckled" 0 "Not_buckled" ;
VAL_ 897 ACM_Seat_Belt_Status_2nd_Row_Dri 3 "Failure" 2 "Not_Available" 1 "Buckled" 0 "Not_buckled" ;
VAL_ 897 ACM_Seat_Belt_Status_2nd_Row_Mid 3 "Failure" 2 "Not_Available" 1 "Buckled" 0 "Not_buckled" ;
VAL_ 897 ACM_Seat_Belt_Status_2nd_Row_Pas 3 "Failure" 2 "Not_Available" 1 "Buckled" 0 "Not_buckled" ;
VAL_ 897 ACM_Seat_Belt_Status_3rd_Row_Dri 3 "Failure" 2 "Not_Available" 1 "Buckled" 0 "Not_buckled" ;
VAL_ 897 ACM_Seat_Belt_Status_3rd_Row_Pas 3 "Failure" 2 "Not_Available" 1 "Buckled" 0 "Not_buckled" ;
VAL_ 1160 Rolling_Counter_0x488 15 "Invalid" ;
VAL_ 1160 ACM_Malfunction 0 "ACM_Failure" 1 "ACM_Normal_Operation" ;
VAL_ 1160 ACM_Pre_Drive_Check 0 "ACM_Pre_Drive_Check" 1 "ACM_Normal_Operation" ;
VAL_ 1160 ACM_in_Plant_Mode 0 "ACM_in_Plant_Mode" 1 "ACM_in_Normal_Mode" ;
VAL_ 1160 ACM_PAB_Suppression 0 "Not_Suppressed" 1 "Suppressed" 2 "Function Failure" 3 "Invalid_Value" ;
VAL_ 1160 ACM_Airbag_Disabled 0 "ACM_AirBag_Disabled" 1 "ACM_Normal_Operation" ;
VAL_ 1160 ACM_Development_Calibration 0 "ACM_Dev_Calibrated" 1 "ACM_Normal_Operation" ;
VAL_ 1160 ACM_In_Disposal_Mode 0 "ACM_In_Disposal_Mode" 1 "ACM_Normal_Operation" ;
VAL_ 1160 ACM_Seatbelt_Reminder_Request 0 "Seatbelt reminder NOT activated" 1 "Seatbelt reminder activated" ;
VAL_ 1160 ACM_SBR_Chime_Req 0 "No Active Chime" 1 "Active Chime" ;
VAL_ 1160 ACM_SBR_Blinking_Req 0 "No Blinking" 1 "Blinking 1Hz" ;
VAL_ 1053 BCM_STAT_RemoteLockFeedback 7 "Signal invalid" 6 "Reserved" 5 "Reserved" 4 "Inactive" 3 "Horn Only" 2 "Lights Only" 1 "Lights and Horn" 0 "OFF" ;
VAL_ 1053 BCM_STAT_RemoteDoorUnlock_reserv 3 "Signal invalid" 2 "All doors" 1 "Driver door" 0 "Reserved" ;
VAL_ 1053 BCM_STAT_AutoDoorUnlock 3 "Signal invalid" 2 "Reserved" 1 "ON" 0 "OFF" ;
VAL_ 1053 BCM_STAT_DoorSpeedLock 7 "Signal invalid" 5 "25KMH" 4 "20KMH" 3 "15KMH" 2 "10KMH" 1 "5KMH" 0 "OFF" ;
VAL_ 1053 BCM_STAT_DayTimeRunningLight_res 3 "Signal invalid" 2 "Reserved" 1 "ON" 0 "OFF" ;
VAL_ 1053 BCM_STAT_AntiTheftMode 7 "Signal invalid" 3 "Light and Horn" 2 "Horn Only" 1 "Light Only" 0 "OFF" ;
VAL_ 1053 BCM_FOBID_userprofile_link 5 "Searching" 4 "No key found" 3 "key illegal" 2 "Fob2" 1 "Fob1" 0 "No trigger from MHU" ;
VAL_ 1053 BCM_feedback_FollowMeHomeTime 4 "120s" 3 "90s" 2 "60s" 1 "30s" 0 "OFF" ;
VAL_ 303 Rolling_Counter_0x12f 15 "Invalid" ;
VAL_ 303 ST_KL_KEY_VLD 15 "Signal invalid" 14 "Error" 13 "Reserved" 12 "Reserved" 11 "Reserved" 10 "Reserved" 9 "Reserved" 8 "Reserved" 7 "Reserved" 6 "Reserved" 5 "Key 10sec delay" 4 "Key valid IR" 3 "Key valid AR" 2 "Key search activ" 1 "Key invalid" 0 "Init" ;
VAL_ 303 ST_SSP 3 "Signal invalid" 2 "Reserve" 1 "SSB pressed" 0 "SSB not pressed" ;
VAL_ 303 BCM_IMMO_Sts 2 "failed " 1 "pass " 0 "init" ;
VAL_ 259 REQ_ConsumerControlAudioVolumeCo 7 "signal invalid" 6 "Reserved" 5 "Reserved" 4 "Reserved" 3 "Reserved" 2 "Level 2" 1 "Level 1" 0 "No Reduction" ;
VAL_ 261 Rolling_Counter_0x105 15 "Invalid" ;
VAL_ 261 BCM_STAT_TrunkAjar 3 "Signal invalid" 2 "Reserved" 1 "Opened" 0 "Closed" ;
VAL_ 261 BCM_STAT_DoorAjarDriver 3 "Signal invalid" 2 "Reserved" 1 "Opened" 0 "Closed" ;
VAL_ 261 BCM_STAT_DoorAjarPassenger 3 "Signal invalid" 2 "Reserved" 1 "Opened" 0 "Closed" ;
VAL_ 261 BCM_STAT_DoorAjarRL 3 "Signal invalid" 2 "Reserved" 1 "Opened" 0 "Closed" ;
VAL_ 261 BCM_STAT_DoorAjarRR 3 "Signal invalid" 2 "Reserved" 1 "Opened" 0 "Closed" ;
VAL_ 261 BCM_STAT_BonnetAjar 3 "Signal invalid" 2 "Reserved" 1 "Opened" 0 "Closed" ;
VAL_ 262 Rolling_Counter_0x106 15 "Invalid" ;
VAL_ 262 BCM_HighBeamSts 0 "OFF" 1 "ON" 2 "Fault (Reserved)" 3 "Signal Invalid" ;
VAL_ 262 BCM_LowBeamSts 0 "OFF" 1 "ON" 2 "Fault (Reserved)" 3 "Signal Invalid" ;
VAL_ 262 BCM_PosLmpSts 0 "OFF" 1 "ON" 2 "Fault (Reserved)" 3 "Signal Invalid" ;
VAL_ 262 BCM_TurnIndicatorSts 0 "OFF" 1 "Left On" 2 "Right On" 3 "Left and Right On" ;
VAL_ 262 BCM_DayRunningLampSts_reserved 0 "OFF" 1 "ON" 2 "Fault (Reserved)" 3 "Signal Invalid" ;
VAL_ 262 BCM_ReverseLightSts 0 "OFF" 1 "ON" 2 "Fault (Reserved)" 3 "Signal Invalid" ;
VAL_ 262 BCM_StopLightSts 0 "OFF" 1 "ON" 2 "Fault (Reserved)" 3 "Signal Invalid" ;
VAL_ 262 BCM_Fr_Dimming_dome_lampSts 0 "OFF" 1 "ON" 2 "Fault (Reserved)" 3 "Signal Invalid" ;
VAL_ 262 BCM_Heated_rearglass 0 "OFF" 1 "ON" 2 "Fault (Reserved)" 3 "Signal Invalid" ;
VAL_ 262 BCM_BsdLightSts 0 "OFF" 1 "Left On" 2 "Right On" 3 "Left and Right On" ;
VAL_ 262 BCM_STAT_LightActivation 7 "Signal invalid" 6 "Reserved" 5 "Reserved" 4 "Reserved" 3 "AutoLight" 2 "LowBeam" 1 "PositionLight" 0 "OFF" ;
VAL_ 262 BCM_STAT_InteriorLight 3 "Signal invalid" 2 "Reserved" 1 "ON" 0 "OFF" ;
VAL_ 263 Rolling_Counter_0x107 15 "Invalid" ;
VAL_ 263 STAT_ATWS 7 "Signal invalid" 6 "Reserved" 5 "Reserved" 4 "Security Failure" 3 "Partly secured" 2 "Alarm" 1 "Unsecured" 0 "Secured" ;
VAL_ 263 STAT_DoorLockDriver 3 "Signal invalid" 2 "Reserved" 1 "Locked" 0 "Unlocked" ;
VAL_ 265 Rolling_Counter_0x109 15 "Invalid" ;
VAL_ 265 BCM_STAT_HazardWarn 3 "Signal invalid" 2 "Reserved" 1 "Active" 0 "Not active" ;
VAL_ 265 BCM_STAT_Horn_Reserved 3 "Signal invalid" 2 "Reserved" 1 "ON" 0 "OFF" ;
VAL_ 265 BCM_STAT_WiperStalkSW 7 "Invalid" 6 "Reserved" 5 "Reserved" 4 "High" 3 "Low/Mist" 2 "Auto" 1 "OFF" 0 "Mist (reserved)" ;
VAL_ 265 BCM_STAT_WiperStalkSW2 7 "Invalid" 6 "Reserved" 5 "Reserved" 4 "wash(Front wash)" 3 "wiper&wash" 2 "wiper (rear wiper)" 1 "OFF(rear wiper)" 0 "wiper&wash(rear wiper and rear wash)" ;
VAL_ 265 BCM_LigntSensor 1 "invalid" 0 "valid" ;
VAL_ 265 BCM_STAT_lampStalkSW1 7 "Invalid" 6 "Reserved" 5 "Reserved" 4 "Reserved" 3 "OFF" 2 "positionlight" 1 "Lowbeam" 0 "Auto" ;
VAL_ 265 BCM_STAT_lampStalkSW2 3 "Invalid" 2 "neutral status" 1 "HighBeam" 0 "FlashHighBeam" ;
VAL_ 266 Rolling_Counter_0x10a 15 "Invalid" ;
VAL_ 266 BCM_LVTop_up 1 "start Top up" 0 "stop Top up" ;
VAL_ 270 RemoteAccessKey 15 "Invalid" 8 "Panic alarm press" 7 "Panic alarm long press" 6 "Long press unlock" 5 "Long press lock" 4 "Tailgate unlock" 3 "Tailgate unlock long press" 2 "Unlock" 1 "Lock" 0 "No command" ;
VAL_ 270 PassiveAccessTrunk 3 "Signal invalid" 2 "Reserved" 1 "Pressed" 0 "Not pressed" ;
VAL_ 270 BCM_CurrentValid_FOB 0 "No Valid FOB" 1 "FOB_1" 2 "FOB_2" 3 "FOB_3" 4 "FOB_4" 5 "Reserved" 6 "Reserved" 7 "Reserved" ;
VAL_ 283 BCM_ACCRelayOutputSts 0 "Inactive" 1 "Active" 2 "Reserved" 3 "Signal Invalid" ;
VAL_ 283 BCM_IGN1RelayOutputSts 0 "Inactive" 1 "Active" 2 "Reserved" 3 "Signal Invalid" ;
VAL_ 283 BCM_ACCRelayFalutSts 0 "No Fault" 1 "Fault" 2 "Reserved" 3 "Signal Invalid" ;
VAL_ 283 BCM_IGN1RelayFalutSts 0 "No Fault" 1 "Fault" 2 "Reserved" 3 "Signal Invalid" ;
VAL_ 283 BCM_KEY_MatchSts 0 "No Match" 1 "Match Success" 2 "Match Failed" 3 "Matching" ;
VAL_ 274 Rolling_Counter_0x112 15 "Invalid" ;
VAL_ 274 STAT_Terminal 7 "Signal invalid" 6 "Reserved" 5 "Reserved" 4 "SW update OTA (Not used in VFe34)" 3 "Engine start (eMotor running)" 2 "ON (Driver Present)" 1 "ACC (Park)" 0 "OFF(Comfort Enable)" ;
VAL_ 274 STAT_CL30s_L_Reserved 3 "Signal invalid" 2 "Failure" 1 "ON" 0 "OFF" ;
VAL_ 529 PEPS_Lock_IGNNotOff_Alert 1 "Active" 0 "Inactive" ;
VAL_ 529 PEPS_CID_NotInside_Alert 1 "Active" 0 "Inactive" ;
VAL_ 529 PEPS_CID_Left_Alert 1 "Active" 0 "Inactive" ;
VAL_ 529 PEPS_RMKey_BatteryLow_Alert 1 "Active" 0 "Inactive" ;
VAL_ 529 PEPS_PressBrakePedal_Alert 1 "Active" 0 "Inactive" ;
VAL_ 529 PEPS_Shift_Position_Alert 1 "Active" 0 "Inactive" ;
VAL_ 529 PEPS_Lock_KeyInside_Alert 1 "Active" 0 "Inactive" ;
VAL_ 529 PEPS_EmergencyStop_Reserved 3 "Invalid" 2 "Reserved" 1 "EmergencyStopMode" 0 "Normal" ;
VAL_ 529 PEPS_CID_NotIndenfied_Alert 1 "Active" 0 "InActive" ;
VAL_ 529 BCM_Positionlight_reminder 0 "Inactive" 1 "Active" 2 "Reserved" 3 "Signal Invalid" ;
VAL_ 525 Rolling_Counter_0x20D 15 "Invalid" ;
VAL_ 525 BCM_ODO 1048575 "Invalid" ;
VAL_ 268 Rolling_Counter_0x10C 15 "Invalid" ;
VAL_ 268 BCM_TboxAuthStatus 0 "Have not learn. Not allow action" 1 "PASSED" 2 "FALIED: Authentication fail" 3 "Invalid" ;
VAL_ 272 Rolling_Counter_0x110 15 "Invalid" ;
VAL_ 272 BCM_APM_FLWIN_Postion 7 "Reserved" 6 "closing" 5 "opening" 4 "Open-80%（Bottom to 80%）" 3 "80%-Close(80% to Top) " 2 "Open(Bottom) " 1 "Closed(Top)" 0 "NotActive" ;
VAL_ 272 BCM_APM_FRWIN_Postion 7 "Reserved" 6 "closing " 5 "opening" 4 "Open-80%（Bottom to 80%）" 3 "80%-Close(80% to Top) " 2 "Open(Bottom) " 1 "Closed(Top)" 0 "NotActive" ;
VAL_ 272 BCM_APM_RLWIN_Postion 7 "Reserved" 6 "closing " 5 "opening" 4 "Open-80%（Bottom to 80%）" 3 "80%-Close(80% to Top) " 2 "Open(Bottom) " 1 "Closed(Top)" 0 "NotActive" ;
VAL_ 272 BCM_APM_RRWIN_Postion 7 "Reserved" 6 "closing " 5 "opening" 4 "Open-80%（Bottom to 80%）" 3 "80%-Close(80% to Top) " 2 "Open(Bottom) " 1 "Closed(Top)" 0 "NotActive" ;
VAL_ 272 APM_Status 1 "Error" 0 "No Error" ;
VAL_ 272 ChildProtectionStatus 3 "Invaild" 2 "Reserved" 1 "ON" 0 "OFF" ;
VAL_ 272 APM_Window_DriveSW_FL_Status 5 "Reserved" 4 "Auto up" 3 "Manual up " 2 "OFF " 1 "Manual down" 0 "Auto down" ;
VAL_ 272 APM_Window_DriveSW_FR_Status 7 "Reserved" 6 "Reserved" 5 "Reserved" 4 "Manual up (Reserved Auto up)" 3 "Manual up " 2 "OFF " 1 "Manual down" 0 "Auto down" ;
VAL_ 272 APM_Window_DriveSW_RL_Status 7 "Reserved" 6 "Reserved" 5 "Reserved" 4 "Manual up (Reserved Auto up)" 3 "Manual up " 2 "OFF " 1 "Manual down" 0 "Auto down" ;
VAL_ 272 APM_Window_DriveSW_RR_Status 7 "Reserved" 6 "Reserved" 5 "Reserved" 4 "Manual up (Reserved Auto up)" 3 "Manual up " 2 "OFF " 1 "Manual down" 0 "Auto down" ;
VAL_ 272 APM_Window_PassengerSW_Status 7 "Reserved" 6 "Reserved" 5 "Reserved" 4 "Manual up (Reserved Auto up)" 3 "Manual up " 2 "OFF " 1 "Manual down" 0 "Auto down" ;
VAL_ 272 APM_Window_PassengerSW_RL_Status 7 "Reserved" 6 "Reserved" 5 "Reserved" 4 "Manual up (Reserved Auto up)" 3 "Manual up " 2 "OFF " 1 "Manual down" 0 "Auto down" ;
VAL_ 272 APM_Window_PassengerSW_RR_Status 7 "Reserved" 6 "Reserved" 5 "Reserved" 4 "Manual up (Reserved Auto up)" 3 "Manual up " 2 "OFF " 1 "Manual down" 0 "Auto down" ;
VAL_ 296 Rolling_Counter_0x128 15 "Invalid" ;
VAL_ 296 ADAS_RCTA_IndLeft 0 "Indicator output off" 1 "Indicator On(warning stage - 1)" 2 "Indicator flashing(warning stage - 2)" 3 "Reserved" ;
VAL_ 296 ADAS_RCTA_IndRight 0 "Indicator output off" 1 "Indicator On(warning stage - 1)" 2 "Indicator flashing(warning stage - 2)" 3 "Reserved" ;
VAL_ 296 ADAS_RCTA_SndWarn 0 "Sound Warning disable" 1 "Left Sound Warning enable" 2 "Right Sound Warning enable" 3 "Left and Right Sound Warning enable" ;
VAL_ 296 ADAS_RCTA_check 0 "Available" 1 "Temporarily not available" 2 "Permanently not available" 3 "signal invalid" ;
VAL_ 296 ADAS_RCTA_state 0 "OFF State" 1 "Stand by state" 2 "Armed state" 3 "Warning stage" ;
VAL_ 296 ADAS_RCTA_sens_Feed_Reserved 0 "Early" 1 "Normal" 2 "Late" 3 "signal invalid" ;
VAL_ 296 ADAS_RCTA_Mode_Feed 0 "Off" 1 "On" 2 "Reserved" 3 "signal invalid" ;
VAL_ 307 Rolling_Counter_0x133 15 "Invalid" ;
VAL_ 307 ADAS_BSD_check 0 "Available" 1 "Temporarily not available" 2 "Permanently not available" 3 "signal invalid" ;
VAL_ 307 ADAS_BSD_state 0 "OFF State" 1 "Stand by state" 2 "Armed state" 3 "Warning" ;
VAL_ 307 ADAS_BSD_AudChime_Feed 0 "Off" 1 "On" 2 "Reserved" 3 "signal invalid" ;
VAL_ 307 ADAS_BSD_IndLeft 0 "Indicator output off" 1 "Indicator On(warning stage - 1)" 2 "Indicator flashing(warning stage - 2)" 3 "Sensor Fault" ;
VAL_ 307 ADAS_BSD_IndRight 0 "Indicator output off" 1 "Indicator On(warning stage - 1)" 2 "Indicator flashing(warning stage - 2)" 3 "Sensor Fault" ;
VAL_ 307 ADAS_BSD_SndWarn 0 "Sound Warning disable" 1 "Sound Warning enable" ;
VAL_ 307 ADAS_BSD_Mode_Feed 0 "Off" 1 "On" 2 "Reserved" 3 "signal invalid" ;
VAL_ 307 ADAS_BSD_sens_Feed 0 "Early" 1 "Normal" 2 "Late" 3 "signal invalid" ;
VAL_ 850 Rolling_Counter_0x352 15 "Invalid" ;
VAL_ 850 ADAS_DOW_Warn 0 "No Info" 1 "Left Warning" 2 "Right Warning" 3 "Left & Right Warning" ;
VAL_ 850 ADAS_DOW_SndWarn 0 "Sound Warning disable" 1 "Left Sound Warning enable" 2 "Right Sound Warning enable" 3 "Left and Right Sound Warning enable" ;
VAL_ 850 ADAS_DOW_state 0 "OFF State" 1 "Stand by state" 2 "Armed state" 3 "Warning stage" ;
VAL_ 850 ADAS_DOW_IndLeft 0 "Indicator output off" 1 "Indicator On(warning stage - 1)" 2 "Indicator flashing(warning stage - 2)" 3 "Sensor Fault" ;
VAL_ 850 ADAS_DOW_IndRight 0 "Indicator output off" 1 "Indicator On(warning stage - 1)" 2 "Indicator flashing(warning stage - 2)" 3 "Sensor Fault" ;
VAL_ 850 ADAS_DOW_sens_Feed_Reserved 0 "Early" 1 "Normal" 2 "Late" 3 "signal invalid" ;
VAL_ 850 ADAS_DOW_Mode_Feed 3 "signal invalid" 2 "Reserved" 1 "ON" 0 "OFF" ;
VAL_ 850 ADAS_DOW_AudChime_Feed 0 "Off" 1 "On" 2 "Reserved" 3 "signal invalid" ;
VAL_ 850 ADAS_DOW_check 0 "Available" 1 "Temporarily not available" 2 "Permanently not available" 3 "signal invalid" ;
VAL_ 1216 Rolling_Counter_0x4C0 15 "Invalid" ;
VAL_ 1216 ADAS_Warning_Flag_1 0 "No Error" 1 "Error" ;
VAL_ 1216 ADAS_Warning_Flag_2 0 "No Error" 1 "Error" ;
VAL_ 1216 ADAS_Warning_Flag_3 0 "No Error" 1 "Error" ;
VAL_ 1216 ADAS_Warning_Flag_4 0 "No Error" 1 "Error" ;
VAL_ 1216 ADAS_Warning_Flag_5 0 "No Error" 1 "Error" ;
VAL_ 1216 ADAS_Warning_Flag_6 0 "No Error" 1 "Error" ;
VAL_ 1216 ADAS_Warning_Flag_7 0 "No Error" 1 "Error" ;
VAL_ 1216 ADAS_Warning_Flag_8 0 "No Error" 1 "Error" ;
VAL_ 1216 ADAS_Warning_Flag_9 0 "No Error" 1 "Error" ;
VAL_ 1216 ADAS_Warning_Flag_10 0 "No Error" 1 "Error" ;
VAL_ 1216 ADAS_Warning_Flag_11 0 "No Error" 1 "Error" ;
VAL_ 1216 ADAS_Warning_Flag_12 0 "No Error" 1 "Error" ;
VAL_ 1216 ADAS_Warning_Flag_13 0 "No Error" 1 "Error" ;
VAL_ 1216 ADAS_Warning_Flag_14 0 "No Error" 1 "Error" ;
VAL_ 1216 ADAS_Warning_Flag_15 0 "No Error" 1 "Error" ;
VAL_ 1216 ADAS_Warning_Flag_16 0 "No Error" 1 "Error" ;
VAL_ 1216 ADAS_Warning_Flag_17 0 "No Error" 1 "Error" ;
VAL_ 1216 ADAS_Warning_Flag_18 0 "No Error" 1 "Error" ;
VAL_ 1216 ADAS_Warning_Flag_19 0 "No Error" 1 "Error" ;
VAL_ 1216 ADAS_Warning_Flag_20 0 "No Error" 1 "Error" ;
VAL_ 1216 ADAS_Warning_Flag_21 0 "No Error" 1 "Error" ;
VAL_ 1216 ADAS_Warning_Flag_22 0 "No Error" 1 "Error" ;
VAL_ 1216 ADAS_Warning_Flag_23 0 "No Error" 1 "Error" ;
VAL_ 1216 ADAS_Warning_Flag_24 0 "No Error" 1 "Error" ;
VAL_ 1216 ADAS_Warning_Flag_25 0 "No Error" 1 "Error" ;
VAL_ 1216 ADAS_Warning_Flag_26 0 "No Error" 1 "Error" ;
VAL_ 1216 ADAS_Warning_Flag_27 0 "No Error" 1 "Error" ;
VAL_ 1216 ADAS_Warning_Flag_28 0 "No Error" 1 "Error" ;
VAL_ 851 Rolling_Counter_0x353 15 "Invalid" ;
VAL_ 851 ADAS_RadarRight_Cal_Status 0 "No Calib" 1 "Calib OK" ;
VAL_ 851 ADAS_RadarLeft_Cal_Status 0 "No Calib" 1 "Calib OK" ;
VAL_ 851 ADAS_RadarRight_DynaCal_Status 0 "In Calibrating" 1 "The absolute value of calibration angle is greater than 6 degrees" ;
VAL_ 851 ADAS_RadarLeft_DynaCal_Status 0 "In Calibrating" 1 "The absolute value of calibration angle is greater than 6 degrees" ;
VAL_ 851 ADAS_MasterSRR_check 0 "Available" 1 "Temporarily not available" 2 "Permanently not available" ;
VAL_ 851 ADAS_SlaveSRR_check 0 "Available" 1 "Temporarily not available" 2 "Permanently not available" ;
VAL_ 851 ADAS_CalSensorMasterProgress 255 "Invaild" ;
VAL_ 851 ADAS_CalSensorSlaverProgress 255 "Invalid" ;
VAL_ 834 RollingCounter_0x342 15 "Invalid" ;
VAL_ 834 ABS_LRWhlSpdRaw 32767 "Invalid" ;
VAL_ 834 ABS_LRWhlSpdRawValid 1 "Valid" 0 "Invalid" ;
VAL_ 834 ABS_RRWhlSpdRaw 32767 "Invalid" ;
VAL_ 834 ABS_RRWhlSpdRawValid 1 "Valid" 0 "Invalid" ;
VAL_ 834 ABS_VehSpd 32767 "Invalid" ;
VAL_ 834 ABS_VehSpdValid 1 "Valid" 0 "Invalid" ;
VAL_ 322 RollingCounter_0x142 15 "Invalid" ;
VAL_ 322 AbsDiagSessionLampReq_Reserved 1 "lamp on" 0 "lamp off" ;
VAL_ 322 ABS_AbsCtrlActv 1 "active" 0 "inactive" ;
VAL_ 322 ABS_EbdFlgFlt 1 "failure" 0 "no failure" ;
VAL_ 322 ABS_AbsFlgFlt 1 "failure" 0 "no failure" ;
VAL_ 322 ABS_ESS_Active 1 "active" 0 "inactive" ;
VAL_ 322 ABS_LowBrakeFluid 1 "failure" 0 "no failure" ;
VAL_ 306 RollingCounter_0x132 15 "Invalid" ;
VAL_ 306 ESC_HSA_Control_Status 1 "active" 0 "inactive" ;
VAL_ 306 ESC_HSA_Status_Fault 1 " HSA Defective" 0 "HSA Normale" ;
VAL_ 306 ESC_TcsDisableSts 3 "signal invalid" 2 "reservred" 1 "disabled" 0 "enabled" ;
VAL_ 306 ESC_TcsCtrlActv 1 "active" 0 "inactive" ;
VAL_ 306 ESC_TcsFlgFlt 1 "failure" 0 "no failure" ;
VAL_ 306 ESC_EscDisableSts 1 "disabled" 0 "enabled" ;
VAL_ 306 ESC_EscCtrlActv 1 "active" 0 "inactive" ;
VAL_ 306 ESC_EscFlgFlt 1 "failure" 0 "no failure" ;
VAL_ 306 ESC_HBAFlgFlt 1 "failure" 0 "no failure" ;
VAL_ 306 ESC_HbaCtrlActv 1 "active" 0 "inactive" ;
VAL_ 306 ESC_SlopeGradeAngle 255 "Invalid" ;
VAL_ 306 ESC_MasterCylinderPressure 4095 "Invalid" ;
VAL_ 994 RollingCounter_0x3E2 15 "Invalid" ;
VAL_ 994 ESC_LateralACC 255 "Invalid" ;
VAL_ 994 ESC_LateralACC_Valid 1 "Valid" 0 "Invalid" ;
VAL_ 994 ESC_LongitudeACC 1023 "Invalid" ;
VAL_ 994 ESC_LongitudeACC_Valid 1 "Valid" 0 "Invalid" ;
VAL_ 994 ESC_VehDynYawRate 16383 "Invalid" ;
VAL_ 994 ESC_VehDynYawRate_Valid 1 "Valid" 0 "Invalid" ;
VAL_ 894 Rolling_counter_0x37E 15 "Invalid" ;
VAL_ 894 EPS_SteeringTorque 4095 "Invalid" ;
VAL_ 894 EPS_TorqSensorStatus 1 "Invalid" 0 "Valid" ;
VAL_ 894 EPS_EpsFailed 1 "failed" 0 "not failed" ;
VAL_ 894 EPS_Mode 3 " Invalid" 1 "low assist" 0 "full assist" ;
VAL_ 382 Rolling_counter_0x17E 15 "Invalid" ;
VAL_ 382 SAS_SteerWheelAngle 65535 "Invalid" ;
VAL_ 382 SAS_SteeringAngleValid 1 "Valid" 0 "Invalid" ;
VAL_ 382 SAS_SASStsSnsr 1 "sensor value valid" 0 "sensor value Invalid" ;
VAL_ 382 SAS_SteerWhlRotSpd 16383 "Invalid" ;
VAL_ 382 SAS_SteerWhlRotSpdStatus 1 "Valid" 0 "Invalid" ;
VAL_ 382 SAS_Calibrated 1 "Calibrated" 0 "Not Calibrated" ;
VAL_ 382 SAS_SASFailure 1 "No Failure" 0 "Failure" ;
VAL_ 617 RollingCounter_0x269 15 "Invalid" ;
VAL_ 617 VCU_VehicleHVStatus 3 "Reserved" 2 "ReadyToDrive" 1 "HV On" 0 "Not ready" ;
VAL_ 617 VCU_ActualGear 7 "Fault" 6 "Reserved" 5 "Reserved" 4 "Reserved" 3 "D" 2 "N" 1 "R" 0 "P reserved" ;
VAL_ 617 VCU_ActualGearValid 1 "nvalid" 0 "Valid" ;
VAL_ 617 VCU_AccPedalPosition 255 "Invalid" ;
VAL_ 617 VCU_AccPedalPositionValid 1 "Invalid" 0 "Valid" ;
VAL_ 617 VCU_TqReductionRqstResponse_Rese 1 "active" 0 "inactive" ;
VAL_ 617 VCU_BrakePedalSts 3 "Invalid" 2 "Reserved" 1 "pressed" 0 "Not pressed" ;
VAL_ 814 CCU_ExternalTemperature 255 "Invaild" ;
VAL_ 814 CCU_ExternalTemperatureFailSts 1 "invalid" 0 "valid" ;
VAL_ 1087 IPC_Sec 63 "Invalid" ;
VAL_ 1087 IPC_Min 63 "Invalid" ;
VAL_ 1087 IPC_Hour 31 "Invalid" ;
VAL_ 1087 IPC_Day 31 "Invalid" ;
VAL_ 1087 IPC_Month 15 "Invalid" ;
VAL_ 1087 IPC_Year 255 "Invalid" ;
VAL_ 1087 IPC_SelfCheckStatus 1 "self-check finish" 0 "self-checking" ;
VAL_ 524 Rolling_Counter_0x20C 15 "Invalid" ;
VAL_ 524 IPC_ODO 1048575 "Invalid" ;
VAL_ 703 IPC_TripA 65535 "Invalid" ;
VAL_ 703 IPC_AverageSpeedTripA 4095 "Invalid" ;
VAL_ 703 IPC_AverageConsumptionTripA 1023 "Invalid" ;
VAL_ 703 IPC_ParkBrakeSts 3 "Invalid" 2 "Reserved" 1 "Applied" 0 "Released" ;
VAL_ 703 IPC_VehSpd 32767 "Invalid" ;
VAL_ 1025 MHU_SET_DoorSpeedLock 15 "Invalid" 14 "Reserved" 13 "Reserved" 12 "Reserved" 11 "Reserved" 10 "Reserved" 9 "Reserved" 8 "Reserved" 7 "Reserved" 6 "Inactive" 5 "25KMH" 4 "20KMH" 3 "15KMH" 2 "10KMH" 1 "5KMH" 0 "OFF" ;
VAL_ 1025 MHU_SET_RemoteDoorUnlock_reserve 3 "Signal invalid" 2 "Reserved" 1 "All doors" 0 "Driver door" ;
VAL_ 1025 MHU_SET_RemoteLockFeedback 7 "Signal Invalid" 6 "Reserved" 5 "Reserved" 4 "inactive" 3 "Horn" 2 "Light" 1 "Light/Horn" 0 "OFF" ;
VAL_ 1025 MHU_SET_AutoUnlockDoor 7 "Invalid" 6 "Reserved" 5 "Reserved" 4 "Reserved" 3 "Reserved" 2 "Inactive" 1 "ON" 0 "OFF" ;
VAL_ 1025 MHU_SET_MirrorAuto_reserved 3 "Signal invalid" 2 "Reserved" 1 "ON" 0 "OFF" ;
VAL_ 1025 MHU_Anti_theftAlarmSet 7 "Invalid" 6 "Reserved" 5 "Reserved" 4 "inactive" 3 "Light/Horn" 2 "Horn" 1 "Light" 0 "OFF" ;
VAL_ 1025 MHU_TriggerReadKey 3 "Signal Invalid" 2 "Reserved" 1 "Request" 0 "No Request" ;
VAL_ 1026 MHU_Heatrearglass_Set 0 "OFF" 1 "ON" 2 "No action" 3 "Invalid" ;
VAL_ 1026 MHU_SET_DayTimeRunningLight_rese 3 "Signal invalid" 2 "Reserved" 1 "ON" 0 "OFF" ;
VAL_ 1026 MHU_SET_FollowMeHomeTime 7 "Invalid" 6 "Inactive" 5 "Reserved" 4 "120s" 3 "90s" 2 "60s" 1 "30s" 0 "OFF" ;
VAL_ 967 MHU_St_DimmingIPC 15 "Invalid" 14 "Level 15" 13 "Level 14" 12 "Level 13" 11 "Level 12" 10 "Level 11" 9 "Level 10" 8 "Level 9" 7 "Level 8" 6 "Level 7" 5 "Level 6" 4 "Level 5" 3 "Level 4" 2 "Level 3" 1 "Level 2" 0 "Level 1" ;
VAL_ 1074 Rolling_Counter_0x432 15 "Invalid" ;
VAL_ 1074 MHU_FOTA_State 0 "INIT" 1 "NORMAL" 2 "FOTA FLASHING" 3 "FOTA-SUSPENDED" 4 "FAIL-SAFE-ERROR" 5 "SHUTDOWN" 6 "REMOTE DIAGNOSTICS" 7 "Invalid" ;
VAL_ 267 TBOX_STAT_TerminalReq 7 "Signal invalid" 6 "No action" 5 "Reserved" 4 "SW Update OTA" 3 "Engine start (eMotor running)" 2 "ON (Driver Present)" 1 "ACC (Park)" 0 "OFF(Comfort Enable)" ;
VAL_ 269 MHU_BCM_reqTrunk 3 "Signal invalid" 2 "No action" 1 "Open" 0 "Close reserved" ;
VAL_ 269 MHU_BCM_RemoteDoorCtrl 3 "Signal invalid" 2 "Reserved" 1 "Unlock" 0 "Lock" ;
VAL_ 269 MHU_APM_ReqWindow 2 "Open(Bottom) " 1 "Closed(Top)" 0 "No action" ;
VAL_ 271 MHU_SetHighBeam 1 "Request flashing" 2 "No request" 3 "Invalid" ;
VAL_ 271 MHU_SetHornOnOff 0 "OFF" 1 "ON" 2 "No action" 3 "Invalid" ;
VAL_ 271 MHU_SetLowBeam 0 "OFF" 1 "ON" 2 "No action" 3 "Invalid" ;
VAL_ 852 MHU_BSD_On 3 "Signal invalid" 2 "inactive" 1 "ON" 0 "OFF" ;
VAL_ 852 MHU_BSD_sens_Reserved 7 "invalid" 6 "Reserved" 5 "Reserved" 4 "Reserved" 3 "Inactive" 2 "Late" 1 "Normal" 0 "Early" ;
VAL_ 852 MHU_BSD_AudWarning 3 "Signal invalid" 2 "inactive" 1 "ON" 0 "OFF" ;
VAL_ 852 MHU_RCTA_On 3 "Signal invalid" 2 "inactive" 1 "ON" 0 "OFF" ;
VAL_ 852 MHU_RCTA_sens_Reserved 7 "invalid" 6 "Reserved" 5 "Reserved" 4 "Reserved" 3 "Inactive" 2 "Late" 1 "Normal" 0 "Early" ;
VAL_ 852 MHU_PA_On 3 "Signal invalid" 2 "inactive" 1 "ON" 0 "OFF" ;
VAL_ 852 MHU_DOW_Mode 3 "Signal invalid" 2 "inactive" 1 "ON" 0 "OFF" ;
VAL_ 852 MHU_DOW_sens_Reserved 7 "invalid" 6 "Reserved" 5 "Reserved" 4 "Reserved" 3 "Inactive" 2 "Late" 1 "Normal" 0 "Early" ;
VAL_ 852 MHU_DOW_AudWarning 3 "Signal invalid" 2 "inactive" 1 "ON" 0 "OFF" ;
VAL_ 425 VCU_RegenLevel_Feed 3 "invalid" 2 "High" 1 "Low" 0 "none" ;
VAL_ 425 VCU_RBCSts 1 "active" 0 "incative" ;
VAL_ 425 VCU_RDCSts 1 "active" 0 "incative" ;
VAL_ 425 VCU_Veh_ERR 1 "Error" 0 "Normal" ;
VAL_ 425 VCU_DrvSys_ERR 1 "Error" 0 "Normal" ;
VAL_ 425 VCU_PackSys_ERR 1 "Error" 0 "Normal" ;
VAL_ 425 VCU_TBOX_Veh_STS_Reserved 3 "Other" 2 "Off" 1 "Start" 0 "Invalid" ;
VAL_ 425 VCU_VehChg_STS 3 "Charge fault" 2 "Charging complete" 1 "Charging in progress" 0 "Charging not in progress" ;
VAL_ 425 VCU_BatterVoltage_Reserved 255 "Invalid" ;
VAL_ 425 VCU_BatteryVoltErr_Reserved 1 "warning" 0 "no warning" ;
VAL_ 425 VCU_MotorCoolingCircuitErr_Reser 1 "Error" 0 "Normal" ;
VAL_ 425 VCU_PackCoolingCircuitErr_Reserv 1 "Error" 0 "Normal" ;
VAL_ 425 VCU_VehicleHVStatus 3 "Reserved" 2 "ReadyToDrive" 1 "HV On" 0 "Not ready" ;
VAL_ 425 VCU_InstantPowerConsump 1023 "Invalid" ;
VAL_ 425 VCU_AveragePowerConsump 1023 "Invalid" ;
VAL_ 425 VCU_BrakePedalSts 3 "Invalid" 2 "Reserved" 1 "pressed" 0 "Not pressed" ;
VAL_ 725 VCU_DCDC_Output_REQ 1 "enable" 0 "disable" ;
VAL_ 725 VCU_DCDC_OutVoltage_REQ 511 "Invalid" ;
VAL_ 725 VCU_DCDCAllowedPower 511 "Invalid" ;
VAL_ 905 VCU_FanControl_Sts 2 "FAN High " 1 "FAN Low " 0 " off" ;
VAL_ 905 VCU_IMMO_Sts 2 "failed " 1 "pass " 0 "init" ;
VAL_ 905 VCU_VacuumSts_reserved 3 "Invalid" 2 "quick leak " 1 "slow leak " 0 "Normal" ;
VAL_ 905 VCU_VacuumPresWrn 3 "Invalid" 2 "Serious Insufficient " 1 "Slight Insufficient " 0 "Normal" ;
VAL_ 504 Rolling_Counter_0x1F8 15 "Invalid" ;
VAL_ 504 EDS_output_trq_FR 65535 "Invalid" ;
VAL_ 504 EDS_output_trqValid_FR 1 "valid" 0 "invalid" ;
VAL_ 504 EDS_Spd_FR 65535 "Invalid" ;
VAL_ 504 EDS_SpdValid_FR 1 "valid" 0 "invalid" ;
VAL_ 504 EDS_MotorDriveSts_FR 3 "Invaild" 2 "regen control" 1 "Drive control" 0 "Zero control" ;
VAL_ 504 EDS_Work_STS_FR 15 "invaild" 14 "power off" 13 "Failure" 12 "after run" 11 "shut down" 5 "HVReady" 4 "normal" 3 "precharge" 2 "standby" 1 "init" 0 "default" ;
VAL_ 504 EDS_powoff_req_FR 1 "(Request high voltage power down)" 0 "(No request)" ;
VAL_ 533 Rolling_Counter_0x215 15 "Invalid" ;
VAL_ 533 BMS_SOE 255 "Invalid" ;
VAL_ 533 BMS_HWCrash_Sts 1 "Crash " 0 "No Crash" ;
VAL_ 533 BMS_HVIL_STS 2 "short to ground" 1 "Open & short to battery" 0 "Closed" ;
VAL_ 533 BMS_IGN_Sts 1 "ON " 0 "OFF" ;
VAL_ 533 BMS_Sys_STS 8 "Invalid" 7 "Failure, unable to operate" 6 "BCU Sleep mode" 5 "Successful Power Down" 4 "Power Down process" 3 "Successful Power Down of HV" 2 "Successful High Voltage Power Up" 1 "Self-check passes, can be high-voltage" 0 "Initialization of power on, self-checking" ;
VAL_ 533 BMS_HVOnOff_STS 3 "Fail to HV on " 2 "HV On " 1 "Precharge " 0 "HV Off" ;
VAL_ 533 BMS_Balance_STS 1 "active " 0 "Inactive" ;
VAL_ 533 BMS_SocActual_EST 1023 "Invalid" ;
VAL_ 533 BMS_BatBalance_ERR 1 "normal " 0 "Error" ;
VAL_ 533 BMS_ISU_Status 3 "Level3(<100 Ohms/V)" 2 "Level2(<200 Ohms/V)" 1 "Level1 <500 Ohms/V ~ >200 Ohms/V" 0 "Normal (> 500 Ohms/V)" ;
VAL_ 533 BMS_ERR_LEV 7 "Battery locked -Reserved" 6 "Fault, needs Shutdown and Wakeup" 5 "Emergency off condition" 4 "Delayed power down with FTTI" 3 "Power down without FTTI" 2 "Limp Home" 1 " Warning (any warning in system)" 0 "No error" ;
VAL_ 533 BMS_SOH 255 "Invalid" ;
VAL_ 533 BMS_HV_Sts 4 "AC Charge" 3 "Super Fast Charge" 2 "HV ON" 1 "Precharge" 0 "HV Off" ;
